AUTOSAR XML (schema 4-2-2)
standard types defined: boolean, float32, float64, sint16, sint32, sint64, sint8, uint16, uint32, uint64, uint8
package /AUTOSAR_PlatformTypes/CompuMethods
  compu method CompuMethod_boolean: 0=false (CompuMethod_boolean_false), 1=true (CompuMethod_boolean_true)
package /AUTOSAR_PlatformTypes/DataConstraints
  range DataConstr_boolean: raw 0..1
  range DataConstr_sint16: phys -32768..32767, raw -32768..32767
  range DataConstr_sint32: phys -2147483648..2147483647, raw -2147483648..2147483647
  range DataConstr_sint64: phys -9223372036854775808..9223372036854775807, raw -9223372036854775808..9223372036854775807
  range DataConstr_sint8: phys -128..127, raw -128..127
  range DataConstr_uint16: phys 0..65535, raw 0..65535
  range DataConstr_uint32: phys 0..4294967295, raw 0..4294967295
  range DataConstr_uint64: phys 0..18446744073709551615, raw 0..18446744073709551615
  range DataConstr_uint8: phys 0..255, raw 0..255
package /BaseType
  77 x base type:
    BT_AB_Abschaltanf_SIH_BF: category=FIXED_LENGTH, base-type-size=1, base-type-encoding=NONE, byte-order=little-endian
    BT_AB_Anforderung_USM: category=FIXED_LENGTH, base-type-size=1, base-type-encoding=NONE, byte-order=little-endian
    BT_AB_Anforderung_eCall: category=FIXED_LENGTH, base-type-size=1, base-type-encoding=NONE, byte-order=little-endian
    BT_AB_Anprall_FGS: category=FIXED_LENGTH, base-type-size=1, base-type-encoding=NONE, byte-order=little-endian
    BT_AB_Anprall_Front_Beifahrer: category=FIXED_LENGTH, base-type-size=1, base-type-encoding=NONE, byte-order=little-endian
    BT_AB_Anprall_Front_Fahrer: category=FIXED_LENGTH, base-type-size=1, base-type-encoding=NONE, byte-order=little-endian
    BT_AB_Anprall_Heck_Beifahrer: category=FIXED_LENGTH, base-type-size=1, base-type-encoding=NONE, byte-order=little-endian
    BT_AB_Anprall_Heck_Fahrer: category=FIXED_LENGTH, base-type-size=1, base-type-encoding=NONE, byte-order=little-endian
    BT_AB_Anprall_Rollover: category=FIXED_LENGTH, base-type-size=1, base-type-encoding=NONE, byte-order=little-endian
    BT_AB_Anprall_Seite_Beifahrer: category=FIXED_LENGTH, base-type-size=1, base-type-encoding=NONE, byte-order=little-endian
    BT_AB_Anprall_Seite_Fahrer: category=FIXED_LENGTH, base-type-size=1, base-type-encoding=NONE, byte-order=little-endian
    BT_AB_Anzeige_Fussg: category=FIXED_LENGTH, base-type-size=2, base-type-encoding=NONE, byte-order=little-endian
    BT_AB_Belegung_VB: category=FIXED_LENGTH, base-type-size=2, base-type-encoding=NONE, byte-order=little-endian
    BT_AB_Belegung_VF: category=FIXED_LENGTH, base-type-size=2, base-type-encoding=NONE, byte-order=little-endian
    BT_AB_Crash_Int: category=FIXED_LENGTH, base-type-size=3, base-type-encoding=NONE, byte-order=little-endian
    BT_AB_Crashschwere: category=FIXED_LENGTH, base-type-size=3, base-type-encoding=NONE, byte-order=little-endian
    BT_AB_Deaktiviert: category=FIXED_LENGTH, base-type-size=1, base-type-encoding=NONE, byte-order=little-endian
    BT_AB_Deaktivierung_HV: category=FIXED_LENGTH, base-type-size=3, base-type-encoding=NONE, byte-order=little-endian
    BT_AB_Diagnose: category=FIXED_LENGTH, base-type-size=1, base-type-encoding=NONE, byte-order=little-endian
    BT_AB_EDR_Trigger: category=FIXED_LENGTH, base-type-size=2, base-type-encoding=NONE, byte-order=little-endian
    BT_AB_Erh_Auf_VB: category=FIXED_LENGTH, base-type-size=2, base-type-encoding=NONE, byte-order=little-endian
    BT_AB_Front_Crash: category=FIXED_LENGTH, base-type-size=1, base-type-encoding=NONE, byte-order=little-endian
    BT_AB_Gurtschloss_BF: category=FIXED_LENGTH, base-type-size=2, base-type-encoding=NONE, byte-order=little-endian
    BT_AB_Gurtschloss_FA: category=FIXED_LENGTH, base-type-size=2, base-type-encoding=NONE, byte-order=little-endian
    BT_AB_Gurtschloss_FA_ext: category=FIXED_LENGTH, base-type-size=3, base-type-encoding=NONE, byte-order=little-endian
    BT_AB_Gurtschloss_FA_ext_aktiv: category=FIXED_LENGTH, base-type-size=1, base-type-encoding=NONE, byte-order=little-endian
    BT_AB_Gurtschloss_Reihe2_BF: category=FIXED_LENGTH, base-type-size=2, base-type-encoding=NONE, byte-order=little-endian
    BT_AB_Gurtschloss_Reihe2_FA: category=FIXED_LENGTH, base-type-size=2, base-type-encoding=NONE, byte-order=little-endian
    BT_AB_Gurtschloss_Reihe2_MI: category=FIXED_LENGTH, base-type-size=2, base-type-encoding=NONE, byte-order=little-endian
    BT_AB_Gurtschloss_Reihe3_BF: category=FIXED_LENGTH, base-type-size=2, base-type-encoding=NONE, byte-order=little-endian
    BT_AB_Gurtschloss_Reihe3_FA: category=FIXED_LENGTH, base-type-size=2, base-type-encoding=NONE, byte-order=little-endian
    BT_AB_Gurtschloss_Reihe3_MI: category=FIXED_LENGTH, base-type-size=2, base-type-encoding=NONE, byte-order=little-endian
    BT_AB_Gurtwarn_VB: category=FIXED_LENGTH, base-type-size=1, base-type-encoding=NONE, byte-order=little-endian
    BT_AB_Gurtwarn_VF: category=FIXED_LENGTH, base-type-size=1, base-type-encoding=NONE, byte-order=little-endian
    BT_AB_Heck_Crash: category=FIXED_LENGTH, base-type-size=1, base-type-encoding=NONE, byte-order=little-endian
    BT_AB_Lampe: category=FIXED_LENGTH, base-type-size=1, base-type-encoding=NONE, byte-order=little-endian
    BT_AB_MKB_Anforderung: category=FIXED_LENGTH, base-type-size=1, base-type-encoding=NONE, byte-order=little-endian
    BT_AB_MKB_gueltig: category=FIXED_LENGTH, base-type-size=1, base-type-encoding=NONE, byte-order=little-endian
    BT_AB_PAO_Leuchte_Anf: category=FIXED_LENGTH, base-type-size=1, base-type-encoding=NONE, byte-order=little-endian
    BT_AB_RGS_Anst: category=FIXED_LENGTH, base-type-size=4, base-type-encoding=NONE, byte-order=little-endian
    BT_AB_Rollover_Crash: category=FIXED_LENGTH, base-type-size=1, base-type-encoding=NONE, byte-order=little-endian
    BT_AB_SB_Crash: category=FIXED_LENGTH, base-type-size=1, base-type-encoding=NONE, byte-order=little-endian
    BT_AB_SF_Crash: category=FIXED_LENGTH, base-type-size=1, base-type-encoding=NONE, byte-order=little-endian
    BT_AB_Sitzpos_Sens_BF: category=FIXED_LENGTH, base-type-size=2, base-type-encoding=NONE, byte-order=little-endian
    BT_AB_Sitzpos_Sens_FA: category=FIXED_LENGTH, base-type-size=2, base-type-encoding=NONE, byte-order=little-endian
    BT_AB_Stellgliedtest: category=FIXED_LENGTH, base-type-size=1, base-type-encoding=NONE, byte-order=little-endian
    BT_AB_Systemfehler: category=FIXED_LENGTH, base-type-size=1, base-type-encoding=NONE, byte-order=little-endian
    BT_AB_Texte_AKS: category=FIXED_LENGTH, base-type-size=2, base-type-encoding=NONE, byte-order=little-endian
    BT_AB_VB_deaktiviert: category=FIXED_LENGTH, base-type-size=1, base-type-encoding=NONE, byte-order=little-endian
    BT_AB_Versorgungsspannung: category=FIXED_LENGTH, base-type-size=1, base-type-encoding=NONE, byte-order=little-endian
    BT_AB_Wickelklappung_Reihe2_BF: category=FIXED_LENGTH, base-type-size=2, base-type-encoding=NONE, byte-order=little-endian
    BT_AB_Wickelklappung_Reihe2_FA: category=FIXED_LENGTH, base-type-size=2, base-type-encoding=NONE, byte-order=little-endian
    BT_AB_Wickelklappung_Reihe2_MI: category=FIXED_LENGTH, base-type-size=2, base-type-encoding=NONE, byte-order=little-endian
    BT_AB_eCS_Aktuatortest_BF: category=FIXED_LENGTH, base-type-size=2, base-type-encoding=NONE, byte-order=little-endian
    BT_AB_eCS_Aktuatortest_FA: category=FIXED_LENGTH, base-type-size=2, base-type-encoding=NONE, byte-order=little-endian
    BT_AB_eCS_Aktuatortest_Reihe2_BF: category=FIXED_LENGTH, base-type-size=2, base-type-encoding=NONE, byte-order=little-endian
    BT_AB_eCS_Aktuatortest_Reihe2_FA: category=FIXED_LENGTH, base-type-size=2, base-type-encoding=NONE, byte-order=little-endian
    BT_AB_eCS_Aktuatortest_Reihe3_BF: category=FIXED_LENGTH, base-type-size=2, base-type-encoding=NONE, byte-order=little-endian
    BT_AB_eCS_Aktuatortest_Reihe3_FA: category=FIXED_LENGTH, base-type-size=2, base-type-encoding=NONE, byte-order=little-endian
    BT_AB_eCS_Error: category=FIXED_LENGTH, base-type-size=1, base-type-encoding=NONE, byte-order=little-endian
    BT_ASM_Masterzeit_02: category=FIXED_LENGTH, base-type-size=8, base-type-encoding=NONE, byte-order=little-endian
    BT_Airbag_01_BZ: category=FIXED_LENGTH, base-type-size=4, base-type-encoding=NONE, byte-order=little-endian
    BT_Airbag_01_CRC: category=FIXED_LENGTH, base-type-size=8, base-type-encoding=NONE, byte-order=little-endian
    BT_Airbag_02_BZ: category=FIXED_LENGTH, base-type-size=4, base-type-encoding=NONE, byte-order=little-endian
    BT_Airbag_02_CRC: category=FIXED_LENGTH, base-type-size=8, base-type-encoding=NONE, byte-order=little-endian
    BT_LoGeWa_Event_Kombiwarnung: category=FIXED_LENGTH, base-type-size=4, base-type-encoding=NONE, byte-order=little-endian
    BT_SC_PAO_OFF_Anf: category=FIXED_LENGTH, base-type-size=2, base-type-encoding=NONE, byte-order=little-endian
    BT_SC_PAO_ON_Anf: category=FIXED_LENGTH, base-type-size=2, base-type-encoding=NONE, byte-order=little-endian
    BT_SC_PAO_Schriftzug_Anf: category=FIXED_LENGTH, base-type-size=2, base-type-encoding=NONE, byte-order=little-endian
    BT_SignalVoid: category=VOID, base-type-encoding=VOID
    BT_eCS_Gurtschloss_Status_Reihe2_BF: category=FIXED_LENGTH, base-type-size=2, base-type-encoding=NONE, byte-order=little-endian
    BT_eCS_Gurtschloss_Status_Reihe2_FA: category=FIXED_LENGTH, base-type-size=2, base-type-encoding=NONE, byte-order=little-endian
    BT_eCS_HW_defekt: category=FIXED_LENGTH, base-type-size=1, base-type-encoding=NONE, byte-order=little-endian
    BT_eCS_SBS_Belegung_Reihe2_BF: category=FIXED_LENGTH, base-type-size=2, base-type-encoding=NONE, byte-order=little-endian
    BT_eCS_SBS_Belegung_Reihe2_FA: category=FIXED_LENGTH, base-type-size=2, base-type-encoding=NONE, byte-order=little-endian
    BT_eCS_Status: category=FIXED_LENGTH, base-type-size=2, base-type-encoding=NONE, byte-order=little-endian
    BT_eCS_Stoerung: category=FIXED_LENGTH, base-type-size=1, base-type-encoding=NONE, byte-order=little-endian
package /BasetypePackage
  base type uint1: category=FIXED_LENGTH, base-type-size=32, base-type-encoding=NONE, byte-order=opaque
  base type uint512: category=FIXED_LENGTH, base-type-size=32, base-type-encoding=NONE, byte-order=opaque
package /Cluster
  can cluster Airbag_SUBCANFD: baudrate=500000, protocol-name=CAN, protocol-version=2.0, bus-off-recovery={bor-counter-l-1-to-l-2=1, bor-time-l-1=0.05, bor-time-l-2=0.2}, can-fd-baudrate=500000  # SubCAN FD Airbag
    can physical channel CHNL: comm-connectors=[CanCommunicationConnector_0, CanCommunicationConnector_1]
      frame Airbag_01: id 0x40, from Airbag, frame-length=8, can-addressing-mode=STANDARD, can-frame-rx-behavior=CAN-FD, can-frame-tx-behavior=CAN-FD
        pdu ipdu_Airbag_01: length=8, transmission-mode-true-timing=cyclic-timing={time-offset=0.0, time-period=0.04}
          signal is_AB_Anzeige_Fussg1: start 34, 2 bit, little-endian, system signal sys_AB_Anzeige_Fussg, init-value=0, base-type=BasetypePackage/uint8, transfer-property=TRIGGERED, to eCS  # Anzeige für ausgelöste Fussgängerschutz-Aktuatorik  # Airbag_SUBCANFD_V14.09.00.01E Generated by BUSNETNG Produktiv 9.24.6
          signal is_AB_Belegung_VF1: start 47, 2 bit, little-endian, system signal sys_AB_Belegung_VF, init-value=0, base-type=BasetypePackage/uint8, transfer-property=TRIGGERED, to eCS  # Belegungserkennung vorne Fahrer.  # Airbag_SUBCANFD_V14.09.00.01E Generated by BUSNETNG Produktiv 9.24.6
          signal is_AB_Crash_Int1: start 21, 3 bit, little-endian, system signal sys_AB_Crash_Int, init-value=0, base-type=BasetypePackage/uint8, transfer-property=TRIGGERED, to eCS  # Crash_Intensität_1 = fahrzeugabhängige Reaktionen im Crash Crash_Intensität_2 = fahrzeugabhängige Reaktionen im Crash Crash_Intensität_3 = fahrzeugabhängige Reaktionen im Crash Die jeweiligen fahrzeugabhängigen Reaktionen im Crash sind in einem separ  # Airbag_SUBCANFD_V14.09.00.01E Generated by BUSNETNG Produktiv 9.24.6
          signal is_AB_Deaktiviert1: start 25, 1 bit, little-endian, system signal sys_AB_Deaktiviert, init-value=0, base-type=uint1, transfer-property=TRIGGERED, to eCS  # Airbag oder Gurtstraffer wurden per Anpassung deaktiviert: Aktualisierung erst nach Selbsttest  # Airbag_SUBCANFD_V14.09.00.01E Generated by BUSNETNG Produktiv 9.24.6
          signal is_AB_Deaktivierung_HV1: start 42, 3 bit, little-endian, system signal sys_AB_Deaktivierung_HV, init-value=0, base-type=BasetypePackage/uint8, transfer-property=TRIGGERED, to eCS  # Deaktivierung des HV-Systems und der HV-Teilnehmer im Crash (u.a. Hybrid- und Elektrofahrzeuge)  # Airbag_SUBCANFD_V14.09.00.01E Generated by BUSNETNG Produktiv 9.24.6
          signal is_AB_Diagnose1: start 28, 1 bit, little-endian, system signal sys_AB_Diagnose, init-value=0, base-type=uint1, transfer-property=TRIGGERED, to eCS  # Airbag in Diagnose  # Airbag_SUBCANFD_V14.09.00.01E Generated by BUSNETNG Produktiv 9.24.6
          signal is_AB_EDR_Trigger1: start 45, 2 bit, little-endian, system signal sys_AB_EDR_Trigger, init-value=0, base-type=BasetypePackage/uint8, transfer-property=TRIGGERED, to eCS  # Triggerbedingung zur dezentralen Aufzeichnung unfallrelevanter Daten im Event Data Recorder  # Airbag_SUBCANFD_V14.09.00.01E Generated by BUSNETNG Produktiv 9.24.6
          signal is_AB_Erh_Auf_VB1: start 30, 2 bit, little-endian, system signal sys_AB_Erh_Auf_VB, init-value=0, base-type=BasetypePackage/uint8, transfer-property=TRIGGERED, to eCS  # Der Fahrer soll bei einem Statuswechsel des Beifahrerairbags (ausgelöst durch die Beifahrerinsassenerkennung oder den Schlüsselschloßschalter) aufmerksam gemacht werden durch eine Anzeige im Kombi. Nur Audi: gültig für: AB2 (4-Türer AU352), B7, C6, D3  # Airbag_SUBCANFD_V14.09.00.01E Generated by BUSNETNG Produktiv 9.24.6
          signal is_AB_Front_Crash1: start 16, 1 bit, little-endian, system signal sys_AB_Front_Crash, init-value=0, base-type=uint1, transfer-property=TRIGGERED, to eCS  # Bit wird bei Überschreitung der Gurtstraffer-, US- und RdW-Schwelle gesetzt  # Airbag_SUBCANFD_V14.09.00.01E Generated by BUSNETNG Produktiv 9.24.6
          signal is_AB_Gurtschloss_FA_ext1: start 49, 3 bit, little-endian, system signal sys_AB_Gurtschloss_FA_ext, init-value=6, base-type=BasetypePackage/uint8, transfer-property=TRIGGERED, to eCS  # Das Ergebnis der Basisfunktion 'Plausibilisierung Gurtschloss' des Verlassenskonzepts wird im Signal dargestellt.  # Airbag_SUBCANFD_V14.09.00.01E Generated by BUSNETNG Produktiv 9.24.6
          signal is_AB_Gurtschloss_FA_ext_aktiv1: start 52, 1 bit, little-endian, system signal sys_AB_Gurtschloss_FA_ext_aktiv, init-value=0, base-type=uint1, transfer-property=TRIGGERED, to eCS  # Über dieses Signal wird signalisiert ob die Erweiterte Gurtdiagnose (Ergebnis wird im Signal AB_Gurtschloss_FA_ext dargestellt) aktiviert oder deaktiviert ist.  # Airbag_SUBCANFD_V14.09.00.01E Generated by BUSNETNG Produktiv 9.24.6
          signal is_AB_Gurtwarn_VB1: start 33, 1 bit, little-endian, system signal sys_AB_Gurtwarn_VB, init-value=0, base-type=uint1, transfer-property=TRIGGERED, to eCS  # Beifahrer hat Gurt nicht gesteckt, Anzeige im Kombi  # Airbag_SUBCANFD_V14.09.00.01E Generated by BUSNETNG Produktiv 9.24.6
          signal is_AB_Gurtwarn_VF1: start 32, 1 bit, little-endian, system signal sys_AB_Gurtwarn_VF, init-value=0, base-type=uint1, transfer-property=TRIGGERED, to eCS  # Fahrer hat Gurt nicht gesteckt, Anzeige im Kombi  # Airbag_SUBCANFD_V14.09.00.01E Generated by BUSNETNG Produktiv 9.24.6
          signal is_AB_Heck_Crash1: start 17, 1 bit, little-endian, system signal sys_AB_Heck_Crash, init-value=0, base-type=uint1, transfer-property=TRIGGERED, to eCS  # Wird für alle neu anlaufenden Projekte umgesetzt: AB8.4, Audi8/VW8  # Airbag_SUBCANFD_V14.09.00.01E Generated by BUSNETNG Produktiv 9.24.6
          signal is_AB_Lampe1: start 24, 1 bit, little-endian, system signal sys_AB_Lampe, init-value=1, base-type=uint1, transfer-property=TRIGGERED, to eCS  # Sicherheitswarnlampe im Kombi wird vom Airbag-SG angesteuert; Zustand der Lampe wird auf dem CAN-Bus ausgegeben (auch Blinkinformation).  # Airbag_SUBCANFD_V14.09.00.01E Generated by BUSNETNG Produktiv 9.24.6
          signal is_AB_MKB_Anforderung1: start 40, 1 bit, little-endian, system signal sys_AB_MKB_Anforderung, init-value=0, base-type=uint1, transfer-property=TRIGGERED, to eCS  # Anforderung Multi-Kollisions-Bremsung  # Airbag_SUBCANFD_V14.09.00.01E Generated by BUSNETNG Produktiv 9.24.6
          signal is_AB_MKB_gueltig1: start 39, 1 bit, little-endian, system signal sys_AB_MKB_gueltig, init-value=0, base-type=uint1, transfer-property=TRIGGERED, to eCS  # Multi-Kollisions-Bremsung im Airbag freigeschaltet  # Airbag_SUBCANFD_V14.09.00.01E Generated by BUSNETNG Produktiv 9.24.6
          signal is_AB_PAO_Leuchte_Anf1: start 38, 1 bit, little-endian, system signal sys_AB_PAO_Leuchte_Anf, init-value=1, base-type=uint1, transfer-property=TRIGGERED, to eCS  # Anforderung an die Passenger-Airbag-Off Leuchte in der Dachkonsole (ein / aus), Einsatz nur bei PAG  # Airbag_SUBCANFD_V14.09.00.01E Generated by BUSNETNG Produktiv 9.24.6
          signal is_AB_RGS_Anst1: start 12, 4 bit, little-endian, system signal sys_AB_RGS_Anst, init-value=8, base-type=BasetypePackage/uint8, transfer-property=TRIGGERED, to eCS  # PreCrash-Ansteuerung reversibler Gurtstraffer (Aktivierung und Kraftniveau) 10xx = deaktiviert  # Airbag_SUBCANFD_V14.09.00.01E Generated by BUSNETNG Produktiv 9.24.6
          signal is_AB_Rollover_Crash1: start 20, 1 bit, little-endian, system signal sys_AB_Rollover_Crash, init-value=0, base-type=uint1, transfer-property=TRIGGERED, to eCS  # Wird im B6/B7 Cabrio und New Beetle Cabrio bedient.  # Airbag_SUBCANFD_V14.09.00.01E Generated by BUSNETNG Produktiv 9.24.6
          signal is_AB_SB_Crash1: start 19, 1 bit, little-endian, system signal sys_AB_SB_Crash, init-value=0, base-type=uint1, transfer-property=TRIGGERED, to eCS  # Z.Zt. nur in Verbindung mit Crash-Intensität >= 100b (Kraftstoffpumpenabschaltung) verwendet.  # Airbag_SUBCANFD_V14.09.00.01E Generated by BUSNETNG Produktiv 9.24.6
          signal is_AB_SF_Crash1: start 18, 1 bit, little-endian, system signal sys_AB_SF_Crash, init-value=0, base-type=uint1, transfer-property=TRIGGERED, to eCS  # Z.Zt. nur in Verbindung mit Crash-Intensität >= 100b (Kraftstoffpumpenabschaltung) verwendet.  # Airbag_SUBCANFD_V14.09.00.01E Generated by BUSNETNG Produktiv 9.24.6
          signal is_AB_Stellgliedtest1: start 29, 1 bit, little-endian, system signal sys_AB_Stellgliedtest, init-value=0, base-type=uint1, transfer-property=TRIGGERED, to eCS  # Information, ob Airbag im Stellgliedtest ist, um eine Notrufauflösung beim Stellgliedtest zu verhindern  # Airbag_SUBCANFD_V14.09.00.01E Generated by BUSNETNG Produktiv 9.24.6
          signal is_AB_Systemfehler1: start 27, 1 bit, little-endian, system signal sys_AB_Systemfehler, init-value=0, base-type=uint1, transfer-property=TRIGGERED, to eCS  # Systemfehler Ggf. wird Warnlampe dauernd eingeschaltet.  # Airbag_SUBCANFD_V14.09.00.01E Generated by BUSNETNG Produktiv 9.24.6
          signal is_AB_Texte_AKS1: start 36, 2 bit, little-endian, system signal sys_AB_Texte_AKS, init-value=0, base-type=BasetypePackage/uint8, transfer-property=TRIGGERED, to eCS  # Textanzeige für pyrotechnische Auslösung der aktiven Kopfstütze (AKS)  # Airbag_SUBCANFD_V14.09.00.01E Generated by BUSNETNG Produktiv 9.24.6
          signal is_AB_VB_deaktiviert1: start 26, 1 bit, little-endian, system signal sys_AB_VB_deaktiviert, init-value=1, base-type=uint1, transfer-property=TRIGGERED, to eCS  # Als Option vorgehalten, Beifahrerairbag wurden per Schlüsselschalter oder Insassenerkennung deaktiviert  # Airbag_SUBCANFD_V14.09.00.01E Generated by BUSNETNG Produktiv 9.24.6
          signal is_AB_Versorgungsspannung1: start 41, 1 bit, little-endian, system signal sys_AB_Versorgungsspannung, init-value=0, base-type=uint1, transfer-property=TRIGGERED, to eCS  # Übertragung der Plausibilitätsinformation Kl.15-Last vs. Kl.15-CAN. Bedienung im Fall Kl.15-Last 'EIN' und Kl.15-CAN 'AUS' mit Ausgabe Warnung/Akustik im Kombi.  # Airbag_SUBCANFD_V14.09.00.01E Generated by BUSNETNG Produktiv 9.24.6
          signal is_AB_eCS_Error1: start 53, 1 bit, little-endian, system signal sys_AB_eCS_Error, init-value=0, base-type=uint1, transfer-property=TRIGGERED, to eCS  # Signal zur Anforderung der Anzeige von Störungen im System der elektrischen Gurtverriegelung  # Airbag_SUBCANFD_V14.09.00.01E Generated by BUSNETNG Produktiv 9.24.6
          signal is_ASM_Masterzeit_021: start 56, 8 bit, little-endian, system signal sys_ASM_Masterzeit_02, init-value=255, base-type=BasetypePackage/uint8, transfer-property=TRIGGERED, to eCS  # Masterzeit für alle ASM Sender  # Airbag_SUBCANFD_V14.09.00.01E Generated by BUSNETNG Produktiv 9.24.6
          signal is_Airbag_01_BZ1: start 8, 4 bit, little-endian, system signal sys_Airbag_01_BZ, init-value=0, base-type=BasetypePackage/uint8, transfer-property=TRIGGERED, to eCS  # Airbag_SUBCANFD_V14.09.00.01E Generated by BUSNETNG Produktiv 9.24.6
          signal is_Airbag_01_CRC1: start 0, 8 bit, little-endian, system signal sys_Airbag_01_CRC, init-value=0, base-type=BasetypePackage/uint8, transfer-property=TRIGGERED, to eCS  # Für MLB: 'Berechnung siehe Lastenheft 'Kommunikationsabsicherung für FlexRay und CAN'' Ab MQB und MLBevo: 'Berechnung siehe Lastenheft 'End-to-End Kommunikationsabsicherung'' Endwerte siehe Begleitdokument 'S-PDU Kennungsfolgen'  # Airbag_SUBCANFD_V14.09.00.01E Generated by BUSNETNG Produktiv 9.24.6
      frame Airbag_02: id 0x520, from Airbag, frame-length=8, can-addressing-mode=STANDARD, can-frame-rx-behavior=CAN-FD, can-frame-tx-behavior=CAN-FD
        pdu ipdu_Airbag_02: length=8, transmission-mode-true-timing=cyclic-timing={time-offset=0.0, time-period=0.2}
          signal is_AB_Abschaltanf_SIH_BF1: start 28, 1 bit, little-endian, system signal sys_AB_Abschaltanf_SIH_BF, init-value=0, base-type=uint1, transfer-property=TRIGGERED, to eCS  # Die Insassenerkennung auf der Beifahrerseite fordert bei Übertemperatur eine Abschaltung der Sitzheizung an. Die Übertemperatur kann bei niederohmigen Nebenschlüssen der Sitzheizungsmatte als Folge von zu hohem resultierenden Strom auftreten.  # Airbag_SUBCANFD_V14.09.00.01E Generated by BUSNETNG Produktiv 9.24.6
          signal is_AB_Anforderung_USM1: start 39, 1 bit, little-endian, system signal sys_AB_Anforderung_USM, init-value=0, base-type=uint1, transfer-property=TRIGGERED, to eCS  # Trigger für Gateway (OBDC) und MIB/MMI, dass ein USM-Ereignis erkannt wurde.  # Airbag_SUBCANFD_V14.09.00.01E Generated by BUSNETNG Produktiv 9.24.6
          signal is_AB_Anforderung_eCall1: start 16, 1 bit, little-endian, system signal sys_AB_Anforderung_eCall, init-value=0, base-type=uint1, transfer-property=TRIGGERED, to eCS  # Trigger für Car2X Steuergerät das ein eCall Ereignis erkannt wurde.  # Airbag_SUBCANFD_V14.09.00.01E Generated by BUSNETNG Produktiv 9.24.6
          signal is_AB_Anprall_FGS1: start 19, 1 bit, little-endian, system signal sys_AB_Anprall_FGS, init-value=0, base-type=uint1, transfer-property=TRIGGERED, to eCS  # Uebermittlung der Lage einer Kollision, Fussgaengerschutz-Aktorik  # Airbag_SUBCANFD_V14.09.00.01E Generated by BUSNETNG Produktiv 9.24.6
          signal is_AB_Anprall_Front_Beifahrer1: start 20, 1 bit, little-endian, system signal sys_AB_Anprall_Front_Beifahrer, init-value=0, base-type=uint1, transfer-property=TRIGGERED, to eCS  # Uebermittlung der Lage einer Kollision, Anprallzone Front Beifahrerseite  # Airbag_SUBCANFD_V14.09.00.01E Generated by BUSNETNG Produktiv 9.24.6
          signal is_AB_Anprall_Front_Fahrer1: start 21, 1 bit, little-endian, system signal sys_AB_Anprall_Front_Fahrer, init-value=0, base-type=uint1, transfer-property=TRIGGERED, to eCS  # Uebermittlung der Lage einer Kollision, Anprallzone Front Fahrerseite  # Airbag_SUBCANFD_V14.09.00.01E Generated by BUSNETNG Produktiv 9.24.6
          signal is_AB_Anprall_Heck_Beifahrer1: start 22, 1 bit, little-endian, system signal sys_AB_Anprall_Heck_Beifahrer, init-value=0, base-type=uint1, transfer-property=TRIGGERED, to eCS  # Uebermittlung der Lage einer Kollision, Anprallzone Beifahrerseite hinten  # Airbag_SUBCANFD_V14.09.00.01E Generated by BUSNETNG Produktiv 9.24.6
          signal is_AB_Anprall_Heck_Fahrer1: start 23, 1 bit, little-endian, system signal sys_AB_Anprall_Heck_Fahrer, init-value=0, base-type=uint1, transfer-property=TRIGGERED, to eCS  # Uebermittlung der Lage einer Kollision, Anprallzone Fahrerseite hinten  # Airbag_SUBCANFD_V14.09.00.01E Generated by BUSNETNG Produktiv 9.24.6
          signal is_AB_Anprall_Rollover1: start 18, 1 bit, little-endian, system signal sys_AB_Anprall_Rollover, init-value=0, base-type=uint1, transfer-property=TRIGGERED, to eCS  # Uebermittlung der Lage einer Kollision, Rollover erkannt  # Airbag_SUBCANFD_V14.09.00.01E Generated by BUSNETNG Produktiv 9.24.6
          signal is_AB_Anprall_Seite_Beifahrer1: start 17, 1 bit, little-endian, system signal sys_AB_Anprall_Seite_Beifahrer, init-value=0, base-type=uint1, transfer-property=TRIGGERED, to eCS  # Uebermittlung der Lage einer Kollision, Anprallzone Beifahrerseite Seite  # Airbag_SUBCANFD_V14.09.00.01E Generated by BUSNETNG Produktiv 9.24.6
          signal is_AB_Anprall_Seite_Fahrer1: start 29, 1 bit, little-endian, system signal sys_AB_Anprall_Seite_Fahrer, init-value=0, base-type=uint1, transfer-property=TRIGGERED, to eCS  # Uebermittlung der Lage einer Kollision, Anprallzone Fahrerseite Seite  # Airbag_SUBCANFD_V14.09.00.01E Generated by BUSNETNG Produktiv 9.24.6
          signal is_AB_Belegung_VB1: start 26, 2 bit, little-endian, system signal sys_AB_Belegung_VB, init-value=0, base-type=BasetypePackage/uint8, transfer-property=TRIGGERED, to eCS  # Belegungserkennung vorne Beifahrer. Wird in US-Steuergeräten über Bladder-Matte bedient, optional bei RdW, falls SBE_EuroNCAP entschieden wird.  # Airbag_SUBCANFD_V14.09.00.01E Generated by BUSNETNG Produktiv 9.24.6
          signal is_AB_Crashschwere1: start 36, 3 bit, little-endian, system signal sys_AB_Crashschwere, init-value=0, base-type=BasetypePackage/uint8, transfer-property=TRIGGERED, to eCS  # Übermittlung der Crashschwere an das Gateway (OBDC)  # Airbag_SUBCANFD_V14.09.00.01E Generated by BUSNETNG Produktiv 9.24.6
          signal is_AB_Gurtschloss_BF1: start 42, 2 bit, little-endian, system signal sys_AB_Gurtschloss_BF, init-value=1, base-type=BasetypePackage/uint8, transfer-property=TRIGGERED, to eCS  # Gurtschlossstatus Beifahrerseite  # Airbag_SUBCANFD_V14.09.00.01E Generated by BUSNETNG Produktiv 9.24.6
          signal is_AB_Gurtschloss_FA1: start 40, 2 bit, little-endian, system signal sys_AB_Gurtschloss_FA, init-value=1, base-type=BasetypePackage/uint8, transfer-property=TRIGGERED, to eCS  # Gurtschlosstatatus Fahrerseite  # Airbag_SUBCANFD_V14.09.00.01E Generated by BUSNETNG Produktiv 9.24.6
          signal is_AB_Gurtschloss_Reihe2_BF1: start 48, 2 bit, little-endian, system signal sys_AB_Gurtschloss_Reihe2_BF, init-value=1, base-type=BasetypePackage/uint8, transfer-property=TRIGGERED, to eCS  # Gurtschlossstatus 2. Reihe Beifahrerseite, Mehrausstattung  # Airbag_SUBCANFD_V14.09.00.01E Generated by BUSNETNG Produktiv 9.24.6
          signal is_AB_Gurtschloss_Reihe2_FA1: start 44, 2 bit, little-endian, system signal sys_AB_Gurtschloss_Reihe2_FA, init-value=1, base-type=BasetypePackage/uint8, transfer-property=TRIGGERED, to eCS  # Gurtschlossstatus 2. Reihe Fahrerseite, Mehrausstattung  # Airbag_SUBCANFD_V14.09.00.01E Generated by BUSNETNG Produktiv 9.24.6
          signal is_AB_Gurtschloss_Reihe2_MI1: start 46, 2 bit, little-endian, system signal sys_AB_Gurtschloss_Reihe2_MI, init-value=1, base-type=BasetypePackage/uint8, transfer-property=TRIGGERED, to eCS  # Gurtschlossstatus 2. Reihe Mitte, Mehrausstattung  # Airbag_SUBCANFD_V14.09.00.01E Generated by BUSNETNG Produktiv 9.24.6
          signal is_AB_Gurtschloss_Reihe3_BF1: start 54, 2 bit, little-endian, system signal sys_AB_Gurtschloss_Reihe3_BF, init-value=1, base-type=BasetypePackage/uint8, transfer-property=TRIGGERED, to eCS  # Gurtschlossstatus 3. Reihe Beifahrerseite, Mehrausstattung  # Airbag_SUBCANFD_V14.09.00.01E Generated by BUSNETNG Produktiv 9.24.6
          signal is_AB_Gurtschloss_Reihe3_FA1: start 50, 2 bit, little-endian, system signal sys_AB_Gurtschloss_Reihe3_FA, init-value=1, base-type=BasetypePackage/uint8, transfer-property=TRIGGERED, to eCS  # Gurtschlossstatus 3. Reihe Fahrerseite, Mehrausstattung  # Airbag_SUBCANFD_V14.09.00.01E Generated by BUSNETNG Produktiv 9.24.6
          signal is_AB_Gurtschloss_Reihe3_MI1: start 52, 2 bit, little-endian, system signal sys_AB_Gurtschloss_Reihe3_MI, init-value=1, base-type=BasetypePackage/uint8, transfer-property=TRIGGERED, to eCS  # Gurtschlossstatus 3. Reihe Mitte, Mehrausstattung  # Airbag_SUBCANFD_V14.09.00.01E Generated by BUSNETNG Produktiv 9.24.6
          signal is_AB_Sitzpos_Sens_BF1: start 58, 2 bit, little-endian, system signal sys_AB_Sitzpos_Sens_BF, init-value=0, base-type=BasetypePackage/uint8, transfer-property=TRIGGERED, to eCS  # Ausgabe Sitzposition Beifahrer  # Airbag_SUBCANFD_V14.09.00.01E Generated by BUSNETNG Produktiv 9.24.6
          signal is_AB_Sitzpos_Sens_FA1: start 56, 2 bit, little-endian, system signal sys_AB_Sitzpos_Sens_FA, init-value=0, base-type=BasetypePackage/uint8, transfer-property=TRIGGERED, to eCS  # Ausgabe Sitzposition Fahrer  # Airbag_SUBCANFD_V14.09.00.01E Generated by BUSNETNG Produktiv 9.24.6
          signal is_AB_Wickelklappung_Reihe2_BF1: start 60, 2 bit, little-endian, system signal sys_AB_Wickelklappung_Reihe2_BF, init-value=1, base-type=BasetypePackage/uint8, transfer-property=TRIGGERED, to eCS  # Status Wickelklappung 2. Reihe Beifahrerseite, Mehrausstattung  # Airbag_SUBCANFD_V14.09.00.01E Generated by BUSNETNG Produktiv 9.24.6
          signal is_AB_Wickelklappung_Reihe2_FA1: start 62, 2 bit, little-endian, system signal sys_AB_Wickelklappung_Reihe2_FA, init-value=1, base-type=BasetypePackage/uint8, transfer-property=TRIGGERED, to eCS  # Status Wickelklappung 2. Reihe Fahrerseite, Mehrausstattung  # Airbag_SUBCANFD_V14.09.00.01E Generated by BUSNETNG Produktiv 9.24.6
          signal is_AB_Wickelklappung_Reihe2_MI1: start 24, 2 bit, little-endian, system signal sys_AB_Wickelklappung_Reihe2_MI, init-value=1, base-type=BasetypePackage/uint8, transfer-property=TRIGGERED, to eCS  # Status Wickelklappung 2. Reihe Mitte, Mehrausstattung  # Airbag_SUBCANFD_V14.09.00.01E Generated by BUSNETNG Produktiv 9.24.6
          signal is_Airbag_02_BZ1: start 8, 4 bit, little-endian, system signal sys_Airbag_02_BZ, init-value=0, base-type=BasetypePackage/uint8, transfer-property=TRIGGERED, to eCS  # Airbag_SUBCANFD_V14.09.00.01E Generated by BUSNETNG Produktiv 9.24.6
          signal is_Airbag_02_CRC1: start 0, 8 bit, little-endian, system signal sys_Airbag_02_CRC, init-value=0, base-type=BasetypePackage/uint8, transfer-property=TRIGGERED, to eCS  # Für MLB: 'Berechnung siehe Lastenheft 'Kommunikationsabsicherung für FlexRay und CAN'' Ab MQB und MLBevo: 'Berechnung siehe Lastenheft 'End-to-End Kommunikationsabsicherung'' Endwerte siehe Begleitdokument 'S-PDU Kennungsfolgen'  # Airbag_SUBCANFD_V14.09.00.01E Generated by BUSNETNG Produktiv 9.24.6
          signal is_LoGeWa_Event_Kombiwarnung1: start 12, 4 bit, little-endian, system signal sys_LoGeWa_Event_Kombiwarnung, init-value=0, base-type=BasetypePackage/uint8, transfer-property=TRIGGERED, to eCS  # Event für Kombiwarnung  # Airbag_SUBCANFD_V14.09.00.01E Generated by BUSNETNG Produktiv 9.24.6
          signal is_SC_PAO_OFF_Anf1: start 34, 2 bit, little-endian, system signal sys_SC_PAO_OFF_Anf, init-value=0, base-type=BasetypePackage/uint8, transfer-property=TRIGGERED, to eCS  # Sollwert für LED 'OFF' in Anzeige Passenger Airbag On/Off  # Airbag_SUBCANFD_V14.09.00.01E Generated by BUSNETNG Produktiv 9.24.6
          signal is_SC_PAO_ON_Anf1: start 32, 2 bit, little-endian, system signal sys_SC_PAO_ON_Anf, init-value=0, base-type=BasetypePackage/uint8, transfer-property=TRIGGERED, to eCS  # Sollwert für LED 'ON' in Anzeige Passenger Airbag On/Off  # Airbag_SUBCANFD_V14.09.00.01E Generated by BUSNETNG Produktiv 9.24.6
          signal is_SC_PAO_Schriftzug_Anf1: start 30, 2 bit, little-endian, system signal sys_SC_PAO_Schriftzug_Anf, init-value=0, base-type=BasetypePackage/uint8, transfer-property=TRIGGERED, to eCS  # Sollwert für LED 'PASSENGER AIRBAG' in Anzeige Passenger Airbag On/Off  # Airbag_SUBCANFD_V14.09.00.01E Generated by BUSNETNG Produktiv 9.24.6
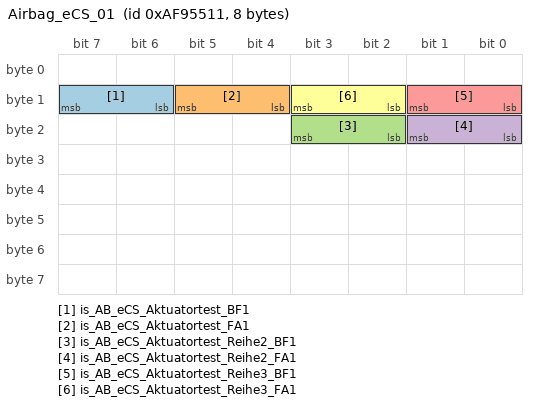
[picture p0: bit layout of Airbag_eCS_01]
      frame Airbag_eCS_01: id 0xAF95511, from Airbag, frame-length=8, can-addressing-mode=EXTENDED, can-frame-rx-behavior=CAN-FD, can-frame-tx-behavior=CAN-FD
        pdu ipdu_Airbag_eCS_01: length=8, transmission-mode-true-timing=cyclic-timing={time-offset=0.0, time-period=0.05}
          signal is_AB_eCS_Aktuatortest_BF1: start 14, 2 bit, little-endian, system signal sys_AB_eCS_Aktuatortest_BF, init-value=0, base-type=BasetypePackage/uint8, transfer-property=TRIGGERED, to eCS  # Signal zum Stellgliedtest Beifahrersitz  # Airbag_SUBCANFD_V14.09.00.01E Generated by BUSNETNG Produktiv 9.24.6
          signal is_AB_eCS_Aktuatortest_FA1: start 12, 2 bit, little-endian, system signal sys_AB_eCS_Aktuatortest_FA, init-value=0, base-type=BasetypePackage/uint8, transfer-property=TRIGGERED, to eCS  # Signal zum Stellgliedtest Fahrersitz  # Airbag_SUBCANFD_V14.09.00.01E Generated by BUSNETNG Produktiv 9.24.6
          signal is_AB_eCS_Aktuatortest_Reihe2_BF1: start 18, 2 bit, little-endian, system signal sys_AB_eCS_Aktuatortest_Reihe2_BF, init-value=0, base-type=BasetypePackage/uint8, transfer-property=TRIGGERED, to eCS  # Signal zum Stellgliedtest Sitz hinten in 2. SR Beifahrerseite  # Airbag_SUBCANFD_V14.09.00.01E Generated by BUSNETNG Produktiv 9.24.6
          signal is_AB_eCS_Aktuatortest_Reihe2_FA1: start 16, 2 bit, little-endian, system signal sys_AB_eCS_Aktuatortest_Reihe2_FA, init-value=0, base-type=BasetypePackage/uint8, transfer-property=TRIGGERED, to eCS  # Signal zum Stellgliedtest Sitz hinten in 2. SR Fahrerseite  # Airbag_SUBCANFD_V14.09.00.01E Generated by BUSNETNG Produktiv 9.24.6
          signal is_AB_eCS_Aktuatortest_Reihe3_BF1: start 8, 2 bit, little-endian, system signal sys_AB_eCS_Aktuatortest_Reihe3_BF, init-value=0, base-type=BasetypePackage/uint8, transfer-property=TRIGGERED, to eCS  # Signal zum Stellgliedtest Sitz hinten in 3. SR Beifahrerseite  # Airbag_SUBCANFD_V14.09.00.01E Generated by BUSNETNG Produktiv 9.24.6
          signal is_AB_eCS_Aktuatortest_Reihe3_FA1: start 10, 2 bit, little-endian, system signal sys_AB_eCS_Aktuatortest_Reihe3_FA, init-value=0, base-type=BasetypePackage/uint8, transfer-property=TRIGGERED, to eCS  # Signal zum Stellgliedtest Sitz hinten in 3. SR Fahrerseite  # Airbag_SUBCANFD_V14.09.00.01E Generated by BUSNETNG Produktiv 9.24.6
      frame DIA_eCS_Req_XIX_Airbag_SUBCANFD: id 0x17FC4206, from Airbag, frame-length=8, can-addressing-mode=EXTENDED, can-frame-rx-behavior=CAN-FD, can-frame-tx-behavior=CAN-FD
        n pdu DIA_eCS_Req_XIX_Airbag_SUBCANFD: length=8
      frame DIA_eCS_Req_FD_XIX_Airbag_SUBCANFD: id 0x1C404206, from Airbag, frame-length=64, can-addressing-mode=EXTENDED, can-frame-rx-behavior=CAN-FD, can-frame-tx-behavior=CAN-FD
        n pdu DIA_eCS_Req_FD_XIX_Airbag_SUBCANFD: length=64
      frame DIA_eCS_Resp_XIX_Airbag_SUBCANFD: id 0x17FE4206, from eCS, to Airbag, frame-length=8, can-addressing-mode=EXTENDED, can-frame-rx-behavior=CAN-FD, can-frame-tx-behavior=CAN-FD
        n pdu DIA_eCS_Resp_XIX_Airbag_SUBCANFD: length=8
      frame DIA_eCS_Resp_FD_XIX_Airbag_SUBCANFD: id 0x1C424206, from eCS, to Airbag, frame-length=64, can-addressing-mode=EXTENDED, can-frame-rx-behavior=CAN-FD, can-frame-tx-behavior=CAN-FD
        n pdu DIA_eCS_Resp_FD_XIX_Airbag_SUBCANFD: length=64
      frame Diag_eCS_Req_FD_XIX_Airbag_SUBCANFD: id 0x1C405206, from Airbag, frame-length=64, can-addressing-mode=EXTENDED, can-frame-rx-behavior=CAN-FD, can-frame-tx-behavior=CAN-FD
        n pdu Diag_eCS_Req_FD_XIX_Airbag_SUBCANFD: length=64
      frame Diag_eCS_Resp_FD_XIX_Airbag_SUBCANFD: id 0x1C425206, from eCS, to Airbag, frame-length=64, can-addressing-mode=EXTENDED, can-frame-rx-behavior=CAN-FD, can-frame-tx-behavior=CAN-FD
        n pdu Diag_eCS_Resp_FD_XIX_Airbag_SUBCANFD: length=64
      frame OBDC_SSN_eCS_Req_FD_XIX_Airbag_SUBCANFD: id 0x1C407206, from Airbag, frame-length=64, can-addressing-mode=EXTENDED, can-frame-rx-behavior=CAN-FD, can-frame-tx-behavior=CAN-FD
        n pdu OBDC_SSN_eCS_Req_FD_XIX_Airbag_SUBCANFD: length=64
      frame OBDC_SSN_eCS_Resp_FD_XIX_Airbag_SUBCANFD: id 0x1C427206, from eCS, to Airbag, frame-length=64, can-addressing-mode=EXTENDED, can-frame-rx-behavior=CAN-FD, can-frame-tx-behavior=CAN-FD
        n pdu OBDC_SSN_eCS_Resp_FD_XIX_Airbag_SUBCANFD: length=64
      frame eCS_01: id 0xAF95510, from eCS, to Airbag, frame-length=8, can-addressing-mode=EXTENDED, can-frame-rx-behavior=CAN-FD, can-frame-tx-behavior=CAN-FD
        pdu ipdu_eCS_01: length=8, transmission-mode-true-timing=cyclic-timing={time-offset=0.0, time-period=0.05}
          signal is_eCS_Error_Reihe1_BFS_1: start 39, 3 bit, little-endian, system signal sys_eCS_Error_Reihe1_BFS_1, init-value=0, base-type=SwBaseTypes/uint8, to Airbag
          signal is_eCS_Error_Reihe1_BFS_2: start 45, 3 bit, little-endian, system signal sys_eCS_Error_Reihe1_BFS_2, init-value=0, base-type=SwBaseTypes/uint8, to Airbag
          signal is_eCS_Error_Reihe1_FS_1: start 36, 3 bit, little-endian, system signal sys_eCS_Error_Reihe1_FS_1, init-value=0, base-type=SwBaseTypes/uint8, to Airbag
          signal is_eCS_Error_Reihe1_FS_2: start 42, 3 bit, little-endian, system signal sys_eCS_Error_Reihe1_FS_2, init-value=0, base-type=SwBaseTypes/uint8, to Airbag
          signal is_eCS_Error_Reihe2_BFS: start 51, 3 bit, little-endian, system signal sys_eCS_Error_Reihe2_BFS, init-value=0, base-type=SwBaseTypes/uint8, to Airbag
          signal is_eCS_Error_Reihe2_FS: start 48, 3 bit, little-endian, system signal sys_eCS_Error_Reihe2_FS, init-value=0, base-type=SwBaseTypes/uint8, to Airbag
          signal is_eCS_SBS_LastState_Reihe2_BFS: start 56, 2 bit, little-endian, system signal sys_eCS_SBS_LastState_Reihe2_BFS, init-value=0, base-type=SwBaseTypes/uint8, to Airbag
          signal is_eCS_SBS_LastState_Reihe2_FS: start 54, 2 bit, little-endian, system signal sys_eCS_SBS_LastState_Reihe2_FS, init-value=0, base-type=SwBaseTypes/uint8, to Airbag
          signal is_eCS_Status_Verr_Reihe1_BFS_1: start 26, 2 bit, little-endian, system signal sys_eCS_Status_Verr_Reihe1_BFS_1, init-value=0, base-type=SwBaseTypes/uint8, to Airbag
          signal is_eCS_Status_Verr_Reihe1_BFS_2: start 30, 2 bit, little-endian, system signal sys_eCS_Status_Verr_Reihe1_BFS_2, init-value=0, base-type=SwBaseTypes/uint8, to Airbag
          signal is_eCS_Status_Verr_Reihe1_FS_1: start 24, 2 bit, little-endian, system signal sys_eCS_Status_Verr_Reihe1_FS_1, init-value=0, base-type=SwBaseTypes/uint8, to Airbag
          signal is_eCS_Status_Verr_Reihe1_FS_2: start 28, 2 bit, little-endian, system signal sys_eCS_Status_Verr_Reihe1_FS_2, init-value=0, base-type=SwBaseTypes/uint8, to Airbag
          signal is_eCS_Status_Verr_Reihe2_BFS: start 34, 2 bit, little-endian, system signal sys_eCS_Status_Verr_Reihe2_BFS, init-value=0, base-type=SwBaseTypes/uint8, to Airbag
          signal is_eCS_Status_Verr_Reihe2_FS: start 32, 2 bit, little-endian, system signal sys_eCS_Status_Verr_Reihe2_FS, init-value=0, base-type=SwBaseTypes/uint8, to Airbag
          signal is_eCS_Gurtschloss_Status_Reihe2_BF1: start 18, 2 bit, little-endian, system signal sys_eCS_Gurtschloss_Status_Reihe2_BF, init-value=1, base-type=BasetypePackage/uint8, transfer-property=TRIGGERED, to Airbag  # Das eCS SG sendet den Status des Gutschlosses 2.SR Beifahrer an das Airbag SG  # Airbag_SUBCANFD_V14.09.00.01E Generated by BUSNETNG Produktiv 9.24.6
          signal is_eCS_Gurtschloss_Status_Reihe2_FA1: start 16, 2 bit, little-endian, system signal sys_eCS_Gurtschloss_Status_Reihe2_FA, init-value=1, base-type=BasetypePackage/uint8, transfer-property=TRIGGERED, to Airbag  # Das eCS SG sendet den Status des Gutschlosses 2.SR Fahrer an das Airbag SG  # Airbag_SUBCANFD_V14.09.00.01E Generated by BUSNETNG Produktiv 9.24.6
          signal is_eCS_HW_defekt1: start 15, 1 bit, little-endian, system signal sys_eCS_HW_defekt, init-value=0, base-type=BasetypePackage/uint8, transfer-property=TRIGGERED, to Airbag  # das eCS signalisiert ein HW_defekt  # Airbag_SUBCANFD_V14.09.00.01E Generated by BUSNETNG Produktiv 9.24.6
          signal is_eCS_SBS_Belegung_Reihe2_BF1: start 22, 2 bit, little-endian, system signal sys_eCS_SBS_Belegung_Reihe2_BF, init-value=2, base-type=BasetypePackage/uint8, transfer-property=TRIGGERED, to Airbag  # Das eCS SG sendet den Status der Sitzbelegung 2.SR Beifahrer an dem Airbag SG  # Airbag_SUBCANFD_V14.09.00.01E Generated by BUSNETNG Produktiv 9.24.6
          signal is_eCS_SBS_Belegung_Reihe2_FA1: start 20, 2 bit, little-endian, system signal sys_eCS_SBS_Belegung_Reihe2_FA, init-value=2, base-type=BasetypePackage/uint8, transfer-property=TRIGGERED, to Airbag  # Das eCS SG sendet den Status der Sitzbelegung 2.SR Fahrer an dem Airbag SG  # Airbag_SUBCANFD_V14.09.00.01E Generated by BUSNETNG Produktiv 9.24.6
          signal is_eCS_Status1: start 12, 2 bit, little-endian, system signal sys_eCS_Status, init-value=0, base-type=BasetypePackage/uint8, transfer-property=TRIGGERED, to Airbag  # Das eCS SG sendet den Status des Gurtband verriegelt oder entriegelt (Magnethub am Gurt gesperrt oder entsperrt)  # Airbag_SUBCANFD_V14.09.00.01E Generated by BUSNETNG Produktiv 9.24.6
          signal is_eCS_Stoerung1: start 14, 1 bit, little-endian, system signal sys_eCS_Stoerung, init-value=0, base-type=BasetypePackage/uint8, transfer-property=TRIGGERED, to Airbag  # Das eCS signalisiert einen sporadischen Fehler oder einen Kommunikations-Timeout  # Airbag_SUBCANFD_V14.09.00.01E Generated by BUSNETNG Produktiv 9.24.6
      frame Can_Frame_MF_Logger: id 0x7C5, from eCS, to Airbag, can-addressing-mode=EXTENDED, can-fd-frame-support=false, j-1939-requestable=false, rx-mask=0, tx-mask=0
      frame Can_Frame_CanDataOut_0: id 0x100, from eCS, to Airbag, can-addressing-mode=STANDARD, can-fd-frame-support=false, j-1939-requestable=false, rx-mask=0, tx-mask=0
      frame Can_Frame_MF: id 0x7C4, from eCS, to Airbag, can-addressing-mode=EXTENDED, can-fd-frame-support=false, j-1939-requestable=false, rx-mask=0, tx-mask=0
      pdu triggering PT_Airbag_SUBCANFD_XIX_TPCHType_CANFD_Diag_XIX_0x1C405206_XIX_0x1C425206_XIX_Physical: pdu=DCM_Airbag_SUBCANFD_XIX_TPCHType_CANFD_Diag_XIX_0x1C405206_XIX_0x1C425206_XIX_Physical
      pdu triggering PT_Airbag_SUBCANFD_XIX_TPCHType_CANFD_Diag_XIX_0x1C425206_XIX_0x1C405206_XIX_Physical: pdu=DCM_Airbag_SUBCANFD_XIX_TPCHType_CANFD_Diag_XIX_0x1C425206_XIX_0x1C405206_XIX_Physical
      pdu triggering PT_Airbag_SUBCANFD_XIX_TPCHType_CANFD_Flash_DIA_XIX_0x1C404206_XIX_0x1C424206_XIX_Physical: pdu=DCM_Airbag_SUBCANFD_XIX_TPCHType_CANFD_Flash_DIA_XIX_0x1C404206_XIX_0x1C424206_XIX_Physical
      pdu triggering PT_Airbag_SUBCANFD_XIX_TPCHType_CANFD_Flash_DIA_XIX_0x1C424206_XIX_0x1C404206_XIX_Physical: pdu=DCM_Airbag_SUBCANFD_XIX_TPCHType_CANFD_Flash_DIA_XIX_0x1C424206_XIX_0x1C404206_XIX_Physical
      pdu triggering PT_Airbag_SUBCANFD_XIX_TPCHType_CANFD_OBDC_SSN_Diagnose_XIX_0x1C407206_XIX_0x1C427206_XIX_Physical: pdu=DCM_Airbag_SUBCANFD_XIX_TPCHType_CANFD_OBDC_SSN_Diagnose_XIX_0x1C407206_XIX_0x1C427206_XIX_Physical
      pdu triggering PT_Airbag_SUBCANFD_XIX_TPCHType_CANFD_OBDC_SSN_Diagnose_XIX_0x1C427206_XIX_0x1C407206_XIX_Physical: pdu=DCM_Airbag_SUBCANFD_XIX_TPCHType_CANFD_OBDC_SSN_Diagnose_XIX_0x1C427206_XIX_0x1C407206_XIX_Physical
      pdu triggering PT_Airbag_SUBCANFD_XIX_TPCHType_CANHS_Flash_DIA_XIX_0x17FC4206_XIX_0x17FE4206_XIX_Physical: pdu=DCM_Airbag_SUBCANFD_XIX_TPCHType_CANHS_Flash_DIA_XIX_0x17FC4206_XIX_0x17FE4206_XIX_Physical
      pdu triggering PT_Airbag_SUBCANFD_XIX_TPCHType_CANHS_Flash_DIA_XIX_0x17FE4206_XIX_0x17FC4206_XIX_Physical: pdu=DCM_Airbag_SUBCANFD_XIX_TPCHType_CANHS_Flash_DIA_XIX_0x17FE4206_XIX_0x17FC4206_XIX_Physical
      pdu triggering PduTriggering0: pdu=IPdu_MFData, from eCS, to Airbag
      pdu triggering PduTriggering1: pdu=IPdu_MFData_Logger, from eCS, to Airbag
      pdu triggering PduTriggering65: pdu=IPdu_Dev_Out_0, from eCS, to Airbag
package /CommunicationClusterPackage
  can tp config CanTPConfig_MQBw_Baseline_eCS: communication-cluster=MQBw_Baseline_Airbag_SUBCANFD_KMatrix_V14_09_00_01E_20230404_MH_Alv_CANBus
    8 x can tp address, all with tp-address-extension-value=0:
      TA_0x17FC4206: tp-address=402407942
      TA_0x17FE4206: tp-address=402539014
      TA_0x1C404206: tp-address=473973254
      TA_0x1C405206: tp-address=473977350
      TA_0x1C407206: tp-address=473985542
      TA_0x1C424206: tp-address=474104326
      TA_0x1C425206: tp-address=474108422
      TA_0x1C427206: tp-address=474116614
    4 x can tp channel, all with channel-mode=FULL-DUPLEX-MODE:
      TPC_Airbag_SUBCANFD_XIX_TPCHType_CANFD_Diag_XIX_0x1C405206_XIX_0x1C425206_XIX_Physical: channel-id=1449258196
      TPC_Airbag_SUBCANFD_XIX_TPCHType_CANFD_Flash_DIA_XIX_0x1C404206_XIX_0x1C424206_XIX_Physical: channel-id=2060928652
      TPC_Airbag_SUBCANFD_XIX_TPCHType_CANFD_OBDC_SSN_Diagnose_XIX_0x1C407206_XIX_0x1C427206_XIX_Physical: channel-id=1803922309
      TPC_Airbag_SUBCANFD_XIX_TPCHType_CANHS_Flash_DIA_XIX_0x17FC4206_XIX_0x17FE4206_XIX_Physical: channel-id=1639721959
    tp-connections:
      addressing-format=STANDARD, can-tp-channel=TPC_Airbag_SUBCANFD_XIX_TPCHType_CANFD_Diag_XIX_0x1C405206_XIX_0x1C425206_XIX_Physical, cancellation=false, data-pdu=Diag_eCS_Req_FD_XIX_Airbag_SUBCANFD, flow-control-pdu=Diag_eCS_Resp_FD_XIX_Airbag_SUBCANFD, max-block-size=0, multicast=TA_0x1C405206, padding-activation=false, receiver=TPN_eCS_XIX_Airbag_SUBCANFD_XIX_0x1C425206, timeout-br=0.0, timeout-bs=0.0, timeout-cr=0.0, timeout-cs=0.0, tp-sdu=DCM_Airbag_SUBCANFD_XIX_TPCHType_CANFD_Diag_XIX_0x1C405206_XIX_0x1C425206_XIX_Physical, transmit-cancellation=false, transmitter=TPN_Airbag_01_XIX_Airbag_SUBCANFD_XIX_0x1C405206
      addressing-format=STANDARD, can-tp-channel=TPC_Airbag_SUBCANFD_XIX_TPCHType_CANFD_OBDC_SSN_Diagnose_XIX_0x1C407206_XIX_0x1C427206_XIX_Physical, cancellation=false, data-pdu=OBDC_SSN_eCS_Req_FD_XIX_Airbag_SUBCANFD, flow-control-pdu=OBDC_SSN_eCS_Resp_FD_XIX_Airbag_SUBCANFD, max-block-size=0, padding-activation=false, receiver=TPN_eCS_XIX_Airbag_SUBCANFD_XIX_0x1C427206, timeout-br=0.0, timeout-bs=0.0, timeout-cr=0.0, timeout-cs=0.0, tp-sdu=DCM_Airbag_SUBCANFD_XIX_TPCHType_CANFD_OBDC_SSN_Diagnose_XIX_0x1C407206_XIX_0x1C427206_XIX_Physical, transmit-cancellation=false, transmitter=TPN_Airbag_01_XIX_Airbag_SUBCANFD_XIX_0x1C407206
      addressing-format=STANDARD, can-tp-channel=TPC_Airbag_SUBCANFD_XIX_TPCHType_CANFD_Flash_DIA_XIX_0x1C404206_XIX_0x1C424206_XIX_Physical, cancellation=false, data-pdu=DIA_eCS_Req_FD_XIX_Airbag_SUBCANFD, flow-control-pdu=DIA_eCS_Resp_FD_XIX_Airbag_SUBCANFD, max-block-size=0, padding-activation=false, receiver=TPN_eCS_XIX_Airbag_SUBCANFD_XIX_0x1C424206, timeout-br=0.1, timeout-bs=1.0, timeout-cr=1.0, timeout-cs=0.2, tp-sdu=DCM_Airbag_SUBCANFD_XIX_TPCHType_CANFD_Flash_DIA_XIX_0x1C404206_XIX_0x1C424206_XIX_Physical, transmit-cancellation=false, transmitter=TPN_Airbag_01_XIX_Airbag_SUBCANFD_XIX_0x1C404206
      addressing-format=STANDARD, can-tp-channel=TPC_Airbag_SUBCANFD_XIX_TPCHType_CANHS_Flash_DIA_XIX_0x17FC4206_XIX_0x17FE4206_XIX_Physical, cancellation=false, data-pdu=DIA_eCS_Req_XIX_Airbag_SUBCANFD, flow-control-pdu=DIA_eCS_Resp_XIX_Airbag_SUBCANFD, max-block-size=0, padding-activation=false, receiver=TPN_eCS_XIX_Airbag_SUBCANFD_XIX_0x17FE4206, timeout-br=0.0, timeout-bs=0.0, timeout-cr=0.0, timeout-cs=0.0, tp-sdu=DCM_Airbag_SUBCANFD_XIX_TPCHType_CANHS_Flash_DIA_XIX_0x17FC4206_XIX_0x17FE4206_XIX_Physical, transmit-cancellation=false, transmitter=TPN_Airbag_01_XIX_Airbag_SUBCANFD_XIX_0x17FC4206
    tp-ecus:
      cycle-time-main-function=0.005, ecu-instance=eCS
      cycle-time-main-function=0.005, ecu-instance=Airbag
    8 x can tp node, all with max-fc-wait=15, st-min=0.005, timeout-ar=1.0, timeout-as=1.0:
      TPN_Airbag_01_XIX_Airbag_SUBCANFD_XIX_0x17FC4206: connector=cc_MQBw_Baseline_Airbag_SUBCANFD_KMatrix_V14_09_00_01E_202304041_MH_Alv, tp-address=TA_0x17FC4206
      TPN_Airbag_01_XIX_Airbag_SUBCANFD_XIX_0x1C404206: connector=cc_MQBw_Baseline_Airbag_SUBCANFD_KMatrix_V14_09_00_01E_202304041_MH_Alv, tp-address=TA_0x1C404206
      TPN_Airbag_01_XIX_Airbag_SUBCANFD_XIX_0x1C405206: connector=cc_MQBw_Baseline_Airbag_SUBCANFD_KMatrix_V14_09_00_01E_202304041_MH_Alv, tp-address=TA_0x1C405206
      TPN_Airbag_01_XIX_Airbag_SUBCANFD_XIX_0x1C407206: connector=cc_MQBw_Baseline_Airbag_SUBCANFD_KMatrix_V14_09_00_01E_202304041_MH_Alv, tp-address=TA_0x1C407206
      TPN_eCS_XIX_Airbag_SUBCANFD_XIX_0x17FE4206: connector=cc_MQBw_Baseline_Airbag_SUBCANFD_KMatrix_V14_09_00_01E_20230404_MH_Alv, tp-address=TA_0x17FE4206
      TPN_eCS_XIX_Airbag_SUBCANFD_XIX_0x1C424206: connector=cc_MQBw_Baseline_Airbag_SUBCANFD_KMatrix_V14_09_00_01E_20230404_MH_Alv, tp-address=TA_0x1C424206
      TPN_eCS_XIX_Airbag_SUBCANFD_XIX_0x1C425206: connector=cc_MQBw_Baseline_Airbag_SUBCANFD_KMatrix_V14_09_00_01E_20230404_MH_Alv, tp-address=TA_0x1C425206
      TPN_eCS_XIX_Airbag_SUBCANFD_XIX_0x1C427206: connector=cc_MQBw_Baseline_Airbag_SUBCANFD_KMatrix_V14_09_00_01E_20230404_MH_Alv, tp-address=TA_0x1C427206
  can cluster MQBw_Baseline_Airbag_SUBCANFD_KMatrix_V14_09_00_01E_20230404_MH_Alv_CANBus: baudrate=500000, protocol-name=CAN
    can physical channel MQBw_Baseline_Airbag_SUBCANFD_KMatrix_V14_09_00_01E_20230404_MH_Alv  # Airbag_SUBCANFD_V14.09.00.01E Generated by BUSNETNG Produktiv 9.24.6
      comm-connectors:
        cc_MQBw_Baseline_Airbag_SUBCANFD_KMatrix_V14_09_00_01E_202304041_MH_Alv
        cc_MQBw_Baseline_Airbag_SUBCANFD_KMatrix_V14_09_00_01E_20230404_MH_Alv
      frame Airbag_01: id 0x40, from Airbag, to eCS, frame-length=8, can-addressing-mode=STANDARD
        carries pdu ipdu_Airbag_01: packing-byte-order=little-endian, start-position=0
      frame Airbag_02: id 0x520, from Airbag, to eCS, frame-length=8, can-addressing-mode=STANDARD
        carries pdu ipdu_Airbag_02: packing-byte-order=little-endian, start-position=0
      frame Airbag_eCS_01: id 0xAF95511, from Airbag, to eCS, frame-length=8, can-addressing-mode=EXTENDED
        carries pdu ipdu_Airbag_eCS_01: packing-byte-order=little-endian, start-position=0
      frame Can_Frame_CanDataOut_0: id 0x100, from eCS, to Airbag, can-addressing-mode=STANDARD, can-fd-frame-support=false, j-1939-requestable=false, rx-mask=0, tx-mask=0
      frame Can_Frame_MF_Logger: id 0x7C5, from eCS, to Airbag, can-addressing-mode=STANDARD, can-fd-frame-support=false, can-frame-rx-behavior=ANY, can-frame-tx-behavior=CAN-20, j-1939-requestable=false, rx-mask=0, tx-mask=0
      frame Can_Frame_MF: id 0x7C4, from eCS, to Airbag, can-addressing-mode=STANDARD, can-fd-frame-support=false, can-frame-rx-behavior=ANY, can-frame-tx-behavior=CAN-20, j-1939-requestable=false, rx-mask=0, tx-mask=0
      frame DIA_eCS_Req_XIX_Airbag_SUBCANFD: id 0x17FC4206, from Airbag, to eCS, frame-length=8, can-addressing-mode=STANDARD, can-fd-frame-support=false, can-frame-rx-behavior=ANY, can-frame-tx-behavior=CAN-20, j-1939-requestable=false, rx-mask=0, tx-mask=0
        carries pdu DIA_eCS_Req_XIX_Airbag_SUBCANFD: packing-byte-order=little-endian, start-position=0
      frame DIA_eCS_Req_FD_XIX_Airbag_SUBCANFD: id 0x1C404206, from Airbag, to eCS, frame-length=64, can-addressing-mode=STANDARD, can-fd-frame-support=false, can-frame-rx-behavior=ANY, can-frame-tx-behavior=CAN-20, j-1939-requestable=false, rx-mask=0, tx-mask=0
        carries pdu DIA_eCS_Req_FD_XIX_Airbag_SUBCANFD: packing-byte-order=little-endian, start-position=0
      frame DIA_eCS_Resp_XIX_Airbag_SUBCANFD: id 0x17FE4206, from Airbag, to eCS, frame-length=8, can-addressing-mode=STANDARD, can-fd-frame-support=false, can-frame-rx-behavior=ANY, can-frame-tx-behavior=CAN-20, j-1939-requestable=false, rx-mask=0, tx-mask=0
        carries pdu DIA_eCS_Resp_XIX_Airbag_SUBCANFD: packing-byte-order=little-endian, start-position=0
      frame DIA_eCS_Resp_FD_XIX_Airbag_SUBCANFD: id 0x1C424206, from Airbag, to eCS, frame-length=64, can-addressing-mode=STANDARD, can-fd-frame-support=false, can-frame-rx-behavior=ANY, can-frame-tx-behavior=CAN-20, j-1939-requestable=false, rx-mask=0, tx-mask=0
        carries pdu DIA_eCS_Resp_FD_XIX_Airbag_SUBCANFD: packing-byte-order=little-endian, start-position=0
      frame Diag_eCS_Resp_FD_XIX_Airbag_SUBCANFD: id 0x1C425206, from Airbag, to eCS, frame-length=64, can-addressing-mode=STANDARD, can-fd-frame-support=false, can-frame-rx-behavior=ANY, can-frame-tx-behavior=CAN-20, j-1939-requestable=false, rx-mask=0, tx-mask=0
        carries pdu Diag_eCS_Resp_FD_XIX_Airbag_SUBCANFD: packing-byte-order=little-endian, start-position=0
      frame Diag_eCS_Req_FD_XIX_Airbag_SUBCANFD: id 0x1C405206, from Airbag, to eCS, frame-length=64, can-addressing-mode=STANDARD, can-fd-frame-support=false, can-frame-rx-behavior=ANY, can-frame-tx-behavior=CAN-20, j-1939-requestable=false, rx-mask=0, tx-mask=0
        carries pdu Diag_eCS_Req_FD_XIX_Airbag_SUBCANFD: packing-byte-order=little-endian, start-position=0
      frame Can_Frame_GliwaIn: id 0x12C, from Airbag, to eCS, can-addressing-mode=STANDARD, can-fd-frame-support=false, can-frame-rx-behavior=ANY, can-frame-tx-behavior=CAN-20, j-1939-requestable=false, rx-mask=0, tx-mask=0
      frame Can_Frame_GliwaOut: id 0xC8, from eCS, to Airbag, can-addressing-mode=STANDARD, can-fd-frame-support=false, can-frame-rx-behavior=ANY, can-frame-tx-behavior=CAN-20, j-1939-requestable=false, rx-mask=0, tx-mask=0
      frame OBDC_SSN_eCS_Req_FD_XIX_Airbag_SUBCANFD: id 0x1C407206, from Airbag, to eCS, frame-length=64, can-addressing-mode=STANDARD, can-fd-frame-support=false, can-frame-rx-behavior=ANY, can-frame-tx-behavior=CAN-20, j-1939-requestable=false, rx-mask=0, tx-mask=0
        carries pdu OBDC_SSN_eCS_Req_FD_XIX_Airbag_SUBCANFD: packing-byte-order=little-endian, start-position=0
      frame OBDC_SSN_eCS_Resp_FD_XIX_Airbag_SUBCANFD: id 0x1C427206, from Airbag, to eCS, frame-length=64, can-addressing-mode=STANDARD, can-fd-frame-support=false, can-frame-rx-behavior=ANY, can-frame-tx-behavior=CAN-20, j-1939-requestable=false, rx-mask=0, tx-mask=0
        carries pdu OBDC_SSN_eCS_Resp_FD_XIX_Airbag_SUBCANFD: packing-byte-order=little-endian, start-position=0
      frame eCS_01: id 0xAF95510, from eCS, to Airbag, frame-length=8, can-addressing-mode=EXTENDED
        carries pdu ipdu_eCS_01: packing-byte-order=little-endian, start-position=0
      pdu triggering DCM_Airbag_SUBCANFD_XIX_Baseline_Airbag_SUBCANFD_KMatrix_V14_09_00_01E_20230404_MH_Alv: pdu=DCM_Airbag_SUBCANFD_XIX_TPCHType_CANFD_Flash_DIA_XIX_0x1C404206_XIX_0x1C424206_XIX_Physical, from Airbag, to eCS
      pdu triggering DCM_Airbag_SUBCANFD_XIX_MQBw_Baseline_Airbag_SUBCANFD_KMatrix_V14_09_00_01E_20230404_MH_Alv: pdu=DCM_Airbag_SUBCANFD_XIX_TPCHType_CANFD_OBDC_SSN_Diagnose_XIX_0x1C407206_XIX_0x1C427206_XIX_Physical, from Airbag, to eCS
      pdu triggering DCM_Airbag_SUBCANFD_XIX_TPCHType_Baseline_Airbag_SUBCANFD_KMatrix_V14_09_00_01E_20230404_MH_Alv: pdu=DCM_Airbag_SUBCANFD_XIX_TPCHType_CANFD_Flash_DIA_XIX_0x1C404206_XIX_0x1C424206_XIX_Physical, from Airbag, to eCS
      pdu triggering DCM_Airbag_SUBCANFD_XIX_TPCHType_MQBw_Baseline_Airbag_SUBCANFD_KMatrix_V14_09_00_01E_20230404_MH_Alv: pdu=DCM_Airbag_SUBCANFD_XIX_TPCHType_CANFD_Diag_XIX_0x1C405206_XIX_0x1C425206_XIX_Physical, from Airbag, to eCS
      pdu triggering DCM_Airbag_SUBCANFD_XIX_TPCHType_TriggeringOn_MQBw_Baseline_Airbag_SUBCANFD_KMatrix_V14_09_00_01E_20230404_MH_Alv: pdu=DCM_Airbag_SUBCANFD_XIX_TPCHType_CANHS_Flash_DIA_XIX_0x17FC4206_XIX_0x17FE4206_XIX_Physical, from Airbag, to eCS
      pdu triggering PduTriggering196: pdu=IPdu_MFData, from eCS, to Airbag
      pdu triggering PduTriggering271: pdu=IPdu_Dev_Out_0, from eCS, to Airbag
      pdu triggering PduTriggering304: pdu=ipdu_DIA_eCS_Resp, from Airbag, to eCS
      pdu triggering PduTriggering394: pdu=IPdu_Gliwa_Out, from eCS, to Airbag
      pdu triggering PduTriggering397: pdu=IPdu_Gliwa_In, from Airbag, to eCS
      pdu triggering PduTriggering4: pdu=IPdu_MFData_Logger, from eCS, to Airbag
      pdu triggering PduTriggering66: pdu=IPdu_Dev_Out_0, from eCS, to Airbag
      pdu triggering TriggeringOn_MQBw_Baseline_Airbag_SUBCANFD_KMatrix_V14_09_00_01E_20230404_MH_Alv: pdu=ipdu_Diag_eCS_Resp_FD, from eCS, to Airbag
      pdu triggering TriggeringOn_MQBw_Baseline_Airbag_SUBCANFD_KMatrix_V14_09_00_01E_20230404_MH_Alv: pdu=ipdu_OBDC_SSN_eCS_Req_FD, from Airbag, to eCS
      pdu triggering ipt_DIA_eCS_Req_FD: pdu=ipdu_DIA_eCS_Req_FD, from Airbag, to eCS
      pdu triggering ipt_DIA_eCS_Resp_FD: pdu=ipdu_DIA_eCS_Resp_FD, from eCS, to Airbag
      pdu triggering ipt_Diag_eCS_Req_FD: pdu=ipdu_Diag_eCS_Req_FD, from Airbag, to eCS
      pdu triggering ipt_Diag_eCS_Resp_FD: pdu=ipdu_Diag_eCS_Resp_FD, from eCS, to Airbag
      pdu triggering ipt_OBDC_SSN_eCS_Req_FD: pdu=ipdu_OBDC_SSN_eCS_Req_FD, from Airbag, to eCS
      pdu triggering ipt_OBDC_SSN_eCS_Resp_FD: pdu=ipdu_OBDC_SSN_eCS_Resp_FD, from eCS, to Airbag
package /ComponentTypes
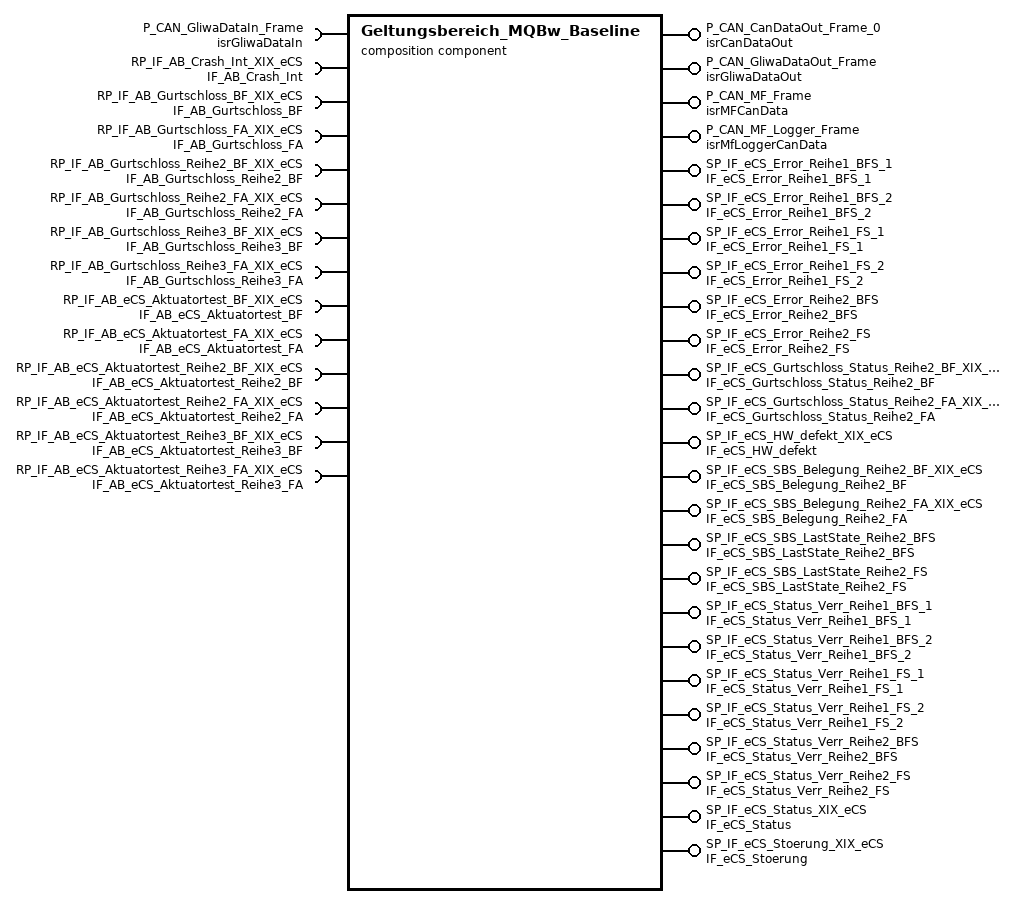
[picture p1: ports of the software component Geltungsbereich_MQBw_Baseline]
  composition sw component type Geltungsbereich_MQBw_Baseline
    provide port P_CAN_CanDataOut_Frame_0: provided-interface=isrCanDataOut
    require port P_CAN_GliwaDataIn_Frame: required-interface=isrGliwaDataIn
    provide port P_CAN_GliwaDataOut_Frame: provided-interface=isrGliwaDataOut
    provide port P_CAN_MF_Frame: provided-interface=isrMFCanData
    provide port P_CAN_MF_Logger_Frame: provided-interface=isrMfLoggerCanData
    13 x require port:
      RP_IF_AB_Crash_Int_XIX_eCS: required-interface=IF_AB_Crash_Int
      RP_IF_AB_Gurtschloss_BF_XIX_eCS: required-interface=IF_AB_Gurtschloss_BF
      RP_IF_AB_Gurtschloss_FA_XIX_eCS: required-interface=IF_AB_Gurtschloss_FA
      RP_IF_AB_Gurtschloss_Reihe2_BF_XIX_eCS: required-interface=IF_AB_Gurtschloss_Reihe2_BF
      RP_IF_AB_Gurtschloss_Reihe2_FA_XIX_eCS: required-interface=IF_AB_Gurtschloss_Reihe2_FA
      RP_IF_AB_Gurtschloss_Reihe3_BF_XIX_eCS: required-interface=IF_AB_Gurtschloss_Reihe3_BF
      RP_IF_AB_Gurtschloss_Reihe3_FA_XIX_eCS: required-interface=IF_AB_Gurtschloss_Reihe3_FA
      RP_IF_AB_eCS_Aktuatortest_BF_XIX_eCS: required-interface=IF_AB_eCS_Aktuatortest_BF
      RP_IF_AB_eCS_Aktuatortest_FA_XIX_eCS: required-interface=IF_AB_eCS_Aktuatortest_FA
      RP_IF_AB_eCS_Aktuatortest_Reihe2_BF_XIX_eCS: required-interface=IF_AB_eCS_Aktuatortest_Reihe2_BF
      RP_IF_AB_eCS_Aktuatortest_Reihe2_FA_XIX_eCS: required-interface=IF_AB_eCS_Aktuatortest_Reihe2_FA
      RP_IF_AB_eCS_Aktuatortest_Reihe3_BF_XIX_eCS: required-interface=IF_AB_eCS_Aktuatortest_Reihe3_BF
      RP_IF_AB_eCS_Aktuatortest_Reihe3_FA_XIX_eCS: required-interface=IF_AB_eCS_Aktuatortest_Reihe3_FA
    21 x provide port:
      SP_IF_eCS_Error_Reihe1_BFS_1: provided-interface=IF_eCS_Error_Reihe1_BFS_1
      SP_IF_eCS_Error_Reihe1_BFS_2: provided-interface=IF_eCS_Error_Reihe1_BFS_2
      SP_IF_eCS_Error_Reihe1_FS_1: provided-interface=IF_eCS_Error_Reihe1_FS_1
      SP_IF_eCS_Error_Reihe1_FS_2: provided-interface=IF_eCS_Error_Reihe1_FS_2
      SP_IF_eCS_Error_Reihe2_BFS: provided-interface=IF_eCS_Error_Reihe2_BFS
      SP_IF_eCS_Error_Reihe2_FS: provided-interface=IF_eCS_Error_Reihe2_FS
      SP_IF_eCS_Gurtschloss_Status_Reihe2_BF_XIX_eCS: provided-interface=IF_eCS_Gurtschloss_Status_Reihe2_BF
      SP_IF_eCS_Gurtschloss_Status_Reihe2_FA_XIX_eCS: provided-interface=IF_eCS_Gurtschloss_Status_Reihe2_FA
      SP_IF_eCS_HW_defekt_XIX_eCS: provided-interface=IF_eCS_HW_defekt
      SP_IF_eCS_SBS_Belegung_Reihe2_BF_XIX_eCS: provided-interface=IF_eCS_SBS_Belegung_Reihe2_BF
      SP_IF_eCS_SBS_Belegung_Reihe2_FA_XIX_eCS: provided-interface=IF_eCS_SBS_Belegung_Reihe2_FA
      SP_IF_eCS_SBS_LastState_Reihe2_BFS: provided-interface=IF_eCS_SBS_LastState_Reihe2_BFS
      SP_IF_eCS_SBS_LastState_Reihe2_FS: provided-interface=IF_eCS_SBS_LastState_Reihe2_FS
      SP_IF_eCS_Status_Verr_Reihe1_BFS_1: provided-interface=IF_eCS_Status_Verr_Reihe1_BFS_1
      SP_IF_eCS_Status_Verr_Reihe1_BFS_2: provided-interface=IF_eCS_Status_Verr_Reihe1_BFS_2
      SP_IF_eCS_Status_Verr_Reihe1_FS_1: provided-interface=IF_eCS_Status_Verr_Reihe1_FS_1
      SP_IF_eCS_Status_Verr_Reihe1_FS_2: provided-interface=IF_eCS_Status_Verr_Reihe1_FS_2
      SP_IF_eCS_Status_Verr_Reihe2_BFS: provided-interface=IF_eCS_Status_Verr_Reihe2_BFS
      SP_IF_eCS_Status_Verr_Reihe2_FS: provided-interface=IF_eCS_Status_Verr_Reihe2_FS
      SP_IF_eCS_Status_XIX_eCS: provided-interface=IF_eCS_Status
      SP_IF_eCS_Stoerung_XIX_eCS: provided-interface=IF_eCS_Stoerung
    component Grundumfang_XIX_eCS: type=Grundumfang_XIX_eCS
    connectors delegation-sw-connector={inner-port=Grundumfang_XIX_eCS.P_CAN_GliwaDataIn_Frame, outer-port=Geltungsbereich_MQBw_Baseline/P_CAN_GliwaDataIn_Frame}, delegation-sw-connector={inner-port=Grundumfang_XIX_eCS.SP_IF_eCS_Error_Reihe1_BFS_1, outer-port=Geltungsbereich_MQBw_Baseline/SP_IF_eCS_Error_Reihe1_BFS_1}, delegation-sw-connector={inner-port=Grundumfang_XIX_eCS.SP_IF_eCS_Error_Reihe1_BFS_2, outer-port=Geltungsbereich_MQBw_Baseline/SP_IF_eCS_Error_Reihe1_BFS_2}, delegation-sw-connector={inner-port=Grundumfang_XIX_eCS.SP_IF_eCS_Error_Reihe1_FS_1, outer-port=Geltungsbereich_MQBw_Baseline/SP_IF_eCS_Error_Reihe1_FS_1}, delegation-sw-connector={inner-port=Grundumfang_XIX_eCS.SP_IF_eCS_Error_Reihe1_FS_2, outer-port=Geltungsbereich_MQBw_Baseline/SP_IF_eCS_Error_Reihe1_FS_2}, delegation-sw-connector={inner-port=Grundumfang_XIX_eCS.SP_IF_eCS_Error_Reihe2_BFS, outer-port=Geltungsbereich_MQBw_Baseline/SP_IF_eCS_Error_Reihe2_BFS}, delegation-sw-connector={inner-port=Grundumfang_XIX_eCS.SP_IF_eCS_Error_Reihe2_FS, outer-port=Geltungsbereich_MQBw_Baseline/SP_IF_eCS_Error_Reihe2_FS}, delegation-sw-connector={inner-port=Grundumfang_XIX_eCS.SP_IF_eCS_SBS_LastState_Reihe2_BFS, outer-port=Geltungsbereich_MQBw_Baseline/SP_IF_eCS_SBS_LastState_Reihe2_BFS}, delegation-sw-connector={inner-port=Grundumfang_XIX_eCS.SP_IF_eCS_SBS_LastState_Reihe2_FS, outer-port=Geltungsbereich_MQBw_Baseline/SP_IF_eCS_SBS_LastState_Reihe2_FS}, delegation-sw-connector={inner-port=Grundumfang_XIX_eCS.SP_IF_eCS_Status_Verr_Reihe1_BFS_1, outer-port=Geltungsbereich_MQBw_Baseline/SP_IF_eCS_Status_Verr_Reihe1_BFS_1}, delegation-sw-connector={inner-port=Grundumfang_XIX_eCS.SP_IF_eCS_Status_Verr_Reihe1_BFS_2, outer-port=Geltungsbereich_MQBw_Baseline/SP_IF_eCS_Status_Verr_Reihe1_BFS_2}, delegation-sw-connector={inner-port=Grundumfang_XIX_eCS.SP_IF_eCS_Status_Verr_Reihe1_FS_1, outer-port=Geltungsbereich_MQBw_Baseline/SP_IF_eCS_Status_Verr_Reihe1_FS_1}, delegation-sw-connector={inner-port=Grundumfang_XIX_eCS.SP_IF_eCS_Status_Verr_Reihe1_FS_2, outer-port=Geltungsbereich_MQBw_Baseline/SP_IF_eCS_Status_Verr_Reihe1_FS_2}, delegation-sw-connector={inner-port=Grundumfang_XIX_eCS.SP_IF_eCS_Status_Verr_Reihe2_BFS, outer-port=Geltungsbereich_MQBw_Baseline/SP_IF_eCS_Status_Verr_Reihe2_BFS}, delegation-sw-connector={inner-port=Grundumfang_XIX_eCS.SP_IF_eCS_Status_Verr_Reihe2_FS, outer-port=Geltungsbereich_MQBw_Baseline/SP_IF_eCS_Status_Verr_Reihe2_FS}:
      delegate Grundumfang_XIX_eCS.RP_IF_AB_Crash_Int_XIX_Grundumfang_XIX_eCS <-> outer port RP_IF_AB_Crash_Int_XIX_eCS
      delegate Grundumfang_XIX_eCS.RP_IF_AB_Gurtschloss_BF_XIX_Grundumfang_XIX_eCS <-> outer port RP_IF_AB_Gurtschloss_BF_XIX_eCS
      delegate Grundumfang_XIX_eCS.RP_IF_AB_Gurtschloss_FA_XIX_Grundumfang_XIX_eCS <-> outer port RP_IF_AB_Gurtschloss_FA_XIX_eCS
      delegate Grundumfang_XIX_eCS.RP_IF_AB_Gurtschloss_Reihe2_BF_XIX_Grundumfang_XIX_eCS <-> outer port RP_IF_AB_Gurtschloss_Reihe2_BF_XIX_eCS
      delegate Grundumfang_XIX_eCS.RP_IF_AB_Gurtschloss_Reihe2_FA_XIX_Grundumfang_XIX_eCS <-> outer port RP_IF_AB_Gurtschloss_Reihe2_FA_XIX_eCS
      delegate Grundumfang_XIX_eCS.RP_IF_AB_Gurtschloss_Reihe3_BF_XIX_Grundumfang_XIX_eCS <-> outer port RP_IF_AB_Gurtschloss_Reihe3_BF_XIX_eCS
      delegate Grundumfang_XIX_eCS.RP_IF_AB_Gurtschloss_Reihe3_FA_XIX_Grundumfang_XIX_eCS <-> outer port RP_IF_AB_Gurtschloss_Reihe3_FA_XIX_eCS
      delegate Grundumfang_XIX_eCS.RP_IF_AB_eCS_Aktuatortest_BF_XIX_Grundumfang_XIX_eCS <-> outer port RP_IF_AB_eCS_Aktuatortest_BF_XIX_eCS
      delegate Grundumfang_XIX_eCS.RP_IF_AB_eCS_Aktuatortest_FA_XIX_Grundumfang_XIX_eCS <-> outer port RP_IF_AB_eCS_Aktuatortest_FA_XIX_eCS
      delegate Grundumfang_XIX_eCS.RP_IF_AB_eCS_Aktuatortest_Reihe2_BF_XIX_Grundumfang_XIX_eCS <-> outer port RP_IF_AB_eCS_Aktuatortest_Reihe2_BF_XIX_eCS
      delegate Grundumfang_XIX_eCS.RP_IF_AB_eCS_Aktuatortest_Reihe2_FA_XIX_Grundumfang_XIX_eCS <-> outer port RP_IF_AB_eCS_Aktuatortest_Reihe2_FA_XIX_eCS
      delegate Grundumfang_XIX_eCS.RP_IF_AB_eCS_Aktuatortest_Reihe3_BF_XIX_Grundumfang_XIX_eCS <-> outer port RP_IF_AB_eCS_Aktuatortest_Reihe3_BF_XIX_eCS
      delegate Grundumfang_XIX_eCS.RP_IF_AB_eCS_Aktuatortest_Reihe3_FA_XIX_Grundumfang_XIX_eCS <-> outer port RP_IF_AB_eCS_Aktuatortest_Reihe3_FA_XIX_eCS
      delegate Grundumfang_XIX_eCS.SP_IF_eCS_Gurtschloss_Status_Reihe2_BF_XIX_Grundumfang_XIX_eCS <-> outer port SP_IF_eCS_Gurtschloss_Status_Reihe2_BF_XIX_eCS
      delegate Grundumfang_XIX_eCS.SP_IF_eCS_Gurtschloss_Status_Reihe2_FA_XIX_Grundumfang_XIX_eCS <-> outer port SP_IF_eCS_Gurtschloss_Status_Reihe2_FA_XIX_eCS
      delegate Grundumfang_XIX_eCS.SP_IF_eCS_HW_defekt_XIX_Grundumfang_XIX_eCS <-> outer port SP_IF_eCS_HW_defekt_XIX_eCS
      delegate Grundumfang_XIX_eCS.SP_IF_eCS_SBS_Belegung_Reihe2_BF_XIX_Grundumfang_XIX_eCS <-> outer port SP_IF_eCS_SBS_Belegung_Reihe2_BF_XIX_eCS
      delegate Grundumfang_XIX_eCS.SP_IF_eCS_SBS_Belegung_Reihe2_FA_XIX_Grundumfang_XIX_eCS <-> outer port SP_IF_eCS_SBS_Belegung_Reihe2_FA_XIX_eCS
      delegate Grundumfang_XIX_eCS.SP_IF_eCS_Status_XIX_Grundumfang_XIX_eCS <-> outer port SP_IF_eCS_Status_XIX_eCS
      delegate Grundumfang_XIX_eCS.SP_IF_eCS_Stoerung_XIX_Grundumfang_XIX_eCS <-> outer port SP_IF_eCS_Stoerung_XIX_eCS
      delegate Grundumfang_XIX_eCS.P_CAN_CanDataOut_Frame_0 <-> outer port Geltungsbereich_MQBw_Baseline/P_CAN_CanDataOut_Frame_0
      delegate Grundumfang_XIX_eCS.P_CAN_GliwaDataOut_Frame <-> outer port Geltungsbereich_MQBw_Baseline/P_CAN_GliwaDataOut_Frame
      delegate Grundumfang_XIX_eCS.P_CAN_MF_Frame <-> outer port Geltungsbereich_MQBw_Baseline/P_CAN_MF_Frame
      delegate Grundumfang_XIX_eCS.P_CAN_MF_Loger_Frame <-> outer port P_CAN_MF_Logger_Frame
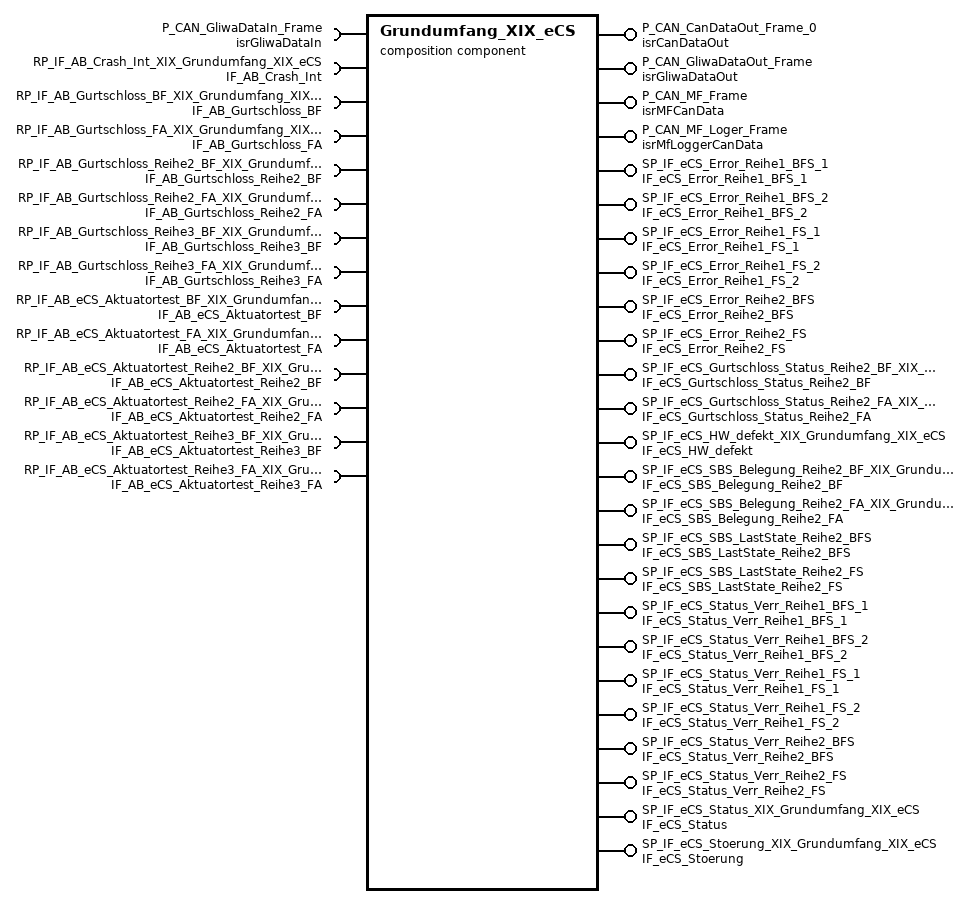
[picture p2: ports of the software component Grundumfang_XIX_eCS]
  composition sw component type Grundumfang_XIX_eCS
    provide port P_CAN_CanDataOut_Frame_0: provided-interface=isrCanDataOut
    require port P_CAN_GliwaDataIn_Frame: required-interface=isrGliwaDataIn
    provide port P_CAN_GliwaDataOut_Frame: provided-interface=isrGliwaDataOut
    provide port P_CAN_MF_Frame: provided-interface=isrMFCanData
    provide port P_CAN_MF_Loger_Frame: provided-interface=isrMfLoggerCanData
    13 x require port:
      RP_IF_AB_Crash_Int_XIX_Grundumfang_XIX_eCS: required-interface=IF_AB_Crash_Int
      RP_IF_AB_Gurtschloss_BF_XIX_Grundumfang_XIX_eCS: required-interface=IF_AB_Gurtschloss_BF
      RP_IF_AB_Gurtschloss_FA_XIX_Grundumfang_XIX_eCS: required-interface=IF_AB_Gurtschloss_FA
      RP_IF_AB_Gurtschloss_Reihe2_BF_XIX_Grundumfang_XIX_eCS: required-interface=IF_AB_Gurtschloss_Reihe2_BF
      RP_IF_AB_Gurtschloss_Reihe2_FA_XIX_Grundumfang_XIX_eCS: required-interface=IF_AB_Gurtschloss_Reihe2_FA
      RP_IF_AB_Gurtschloss_Reihe3_BF_XIX_Grundumfang_XIX_eCS: required-interface=IF_AB_Gurtschloss_Reihe3_BF
      RP_IF_AB_Gurtschloss_Reihe3_FA_XIX_Grundumfang_XIX_eCS: required-interface=IF_AB_Gurtschloss_Reihe3_FA
      RP_IF_AB_eCS_Aktuatortest_BF_XIX_Grundumfang_XIX_eCS: required-interface=IF_AB_eCS_Aktuatortest_BF
      RP_IF_AB_eCS_Aktuatortest_FA_XIX_Grundumfang_XIX_eCS: required-interface=IF_AB_eCS_Aktuatortest_FA
      RP_IF_AB_eCS_Aktuatortest_Reihe2_BF_XIX_Grundumfang_XIX_eCS: required-interface=IF_AB_eCS_Aktuatortest_Reihe2_BF
      RP_IF_AB_eCS_Aktuatortest_Reihe2_FA_XIX_Grundumfang_XIX_eCS: required-interface=IF_AB_eCS_Aktuatortest_Reihe2_FA
      RP_IF_AB_eCS_Aktuatortest_Reihe3_BF_XIX_Grundumfang_XIX_eCS: required-interface=IF_AB_eCS_Aktuatortest_Reihe3_BF
      RP_IF_AB_eCS_Aktuatortest_Reihe3_FA_XIX_Grundumfang_XIX_eCS: required-interface=IF_AB_eCS_Aktuatortest_Reihe3_FA
    21 x provide port:
      SP_IF_eCS_Error_Reihe1_BFS_1: provided-interface=IF_eCS_Error_Reihe1_BFS_1
      SP_IF_eCS_Error_Reihe1_BFS_2: provided-interface=IF_eCS_Error_Reihe1_BFS_2
      SP_IF_eCS_Error_Reihe1_FS_1: provided-interface=IF_eCS_Error_Reihe1_FS_1
      SP_IF_eCS_Error_Reihe1_FS_2: provided-interface=IF_eCS_Error_Reihe1_FS_2
      SP_IF_eCS_Error_Reihe2_BFS: provided-interface=IF_eCS_Error_Reihe2_BFS
      SP_IF_eCS_Error_Reihe2_FS: provided-interface=IF_eCS_Error_Reihe2_FS
      SP_IF_eCS_Gurtschloss_Status_Reihe2_BF_XIX_Grundumfang_XIX_eCS: provided-interface=IF_eCS_Gurtschloss_Status_Reihe2_BF
      SP_IF_eCS_Gurtschloss_Status_Reihe2_FA_XIX_Grundumfang_XIX_eCS: provided-interface=IF_eCS_Gurtschloss_Status_Reihe2_FA
      SP_IF_eCS_HW_defekt_XIX_Grundumfang_XIX_eCS: provided-interface=IF_eCS_HW_defekt
      SP_IF_eCS_SBS_Belegung_Reihe2_BF_XIX_Grundumfang_XIX_eCS: provided-interface=IF_eCS_SBS_Belegung_Reihe2_BF
      SP_IF_eCS_SBS_Belegung_Reihe2_FA_XIX_Grundumfang_XIX_eCS: provided-interface=IF_eCS_SBS_Belegung_Reihe2_FA
      SP_IF_eCS_SBS_LastState_Reihe2_BFS: provided-interface=IF_eCS_SBS_LastState_Reihe2_BFS
      SP_IF_eCS_SBS_LastState_Reihe2_FS: provided-interface=IF_eCS_SBS_LastState_Reihe2_FS
      SP_IF_eCS_Status_Verr_Reihe1_BFS_1: provided-interface=IF_eCS_Status_Verr_Reihe1_BFS_1
      SP_IF_eCS_Status_Verr_Reihe1_BFS_2: provided-interface=IF_eCS_Status_Verr_Reihe1_BFS_2
      SP_IF_eCS_Status_Verr_Reihe1_FS_1: provided-interface=IF_eCS_Status_Verr_Reihe1_FS_1
      SP_IF_eCS_Status_Verr_Reihe1_FS_2: provided-interface=IF_eCS_Status_Verr_Reihe1_FS_2
      SP_IF_eCS_Status_Verr_Reihe2_BFS: provided-interface=IF_eCS_Status_Verr_Reihe2_BFS
      SP_IF_eCS_Status_Verr_Reihe2_FS: provided-interface=IF_eCS_Status_Verr_Reihe2_FS
      SP_IF_eCS_Status_XIX_Grundumfang_XIX_eCS: provided-interface=IF_eCS_Status
      SP_IF_eCS_Stoerung_XIX_Grundumfang_XIX_eCS: provided-interface=IF_eCS_Stoerung
    component S32K_eCS_ECU_Application: type=S32K_eCS_ECU_Application
    component S32K_eCS_ECU_Autosar_Interfaces: type=S32K_eCS_ECU_Autosar_Interfaces
    connectors delegation-sw-connector={inner-port=S32K_eCS_ECU_Application.SP_IF_eCS_Gurtschloss_Status_Reihe2_BF_XIX_Grundumfang_XIX_eCS, outer-port=SP_IF_eCS_Gurtschloss_Status_Reihe2_BF_XIX_Grundumfang_XIX_eCS}, delegation-sw-connector={inner-port=S32K_eCS_ECU_Application.SP_IF_eCS_Gurtschloss_Status_Reihe2_FA_XIX_Grundumfang_XIX_eCS, outer-port=SP_IF_eCS_Gurtschloss_Status_Reihe2_FA_XIX_Grundumfang_XIX_eCS}, delegation-sw-connector={inner-port=S32K_eCS_ECU_Application.RP_IF_AB_Crash_Int_XIX_Grundumfang_XIX_eCS, outer-port=RP_IF_AB_Crash_Int_XIX_Grundumfang_XIX_eCS}, delegation-sw-connector={inner-port=S32K_eCS_ECU_Application.RP_IF_AB_Gurtschloss_BF_XIX_Grundumfang_XIX_eCS, outer-port=RP_IF_AB_Gurtschloss_BF_XIX_Grundumfang_XIX_eCS}, delegation-sw-connector={inner-port=S32K_eCS_ECU_Application.RP_IF_AB_Gurtschloss_FA_XIX_Grundumfang_XIX_eCS, outer-port=RP_IF_AB_Gurtschloss_FA_XIX_Grundumfang_XIX_eCS}, delegation-sw-connector={inner-port=S32K_eCS_ECU_Application.RP_IF_AB_Gurtschloss_Reihe2_BF_XIX_Grundumfang_XIX_eCS, outer-port=RP_IF_AB_Gurtschloss_Reihe2_BF_XIX_Grundumfang_XIX_eCS}, delegation-sw-connector={inner-port=S32K_eCS_ECU_Application.RP_IF_AB_Gurtschloss_Reihe2_FA_XIX_Grundumfang_XIX_eCS, outer-port=RP_IF_AB_Gurtschloss_Reihe2_FA_XIX_Grundumfang_XIX_eCS}, delegation-sw-connector={inner-port=S32K_eCS_ECU_Application.RP_IF_AB_Gurtschloss_Reihe3_BF_XIX_Grundumfang_XIX_eCS, outer-port=RP_IF_AB_Gurtschloss_Reihe3_BF_XIX_Grundumfang_XIX_eCS}, delegation-sw-connector={inner-port=S32K_eCS_ECU_Application.RP_IF_AB_Gurtschloss_Reihe3_FA_XIX_Grundumfang_XIX_eCS, outer-port=RP_IF_AB_Gurtschloss_Reihe3_FA_XIX_Grundumfang_XIX_eCS}, delegation-sw-connector={inner-port=S32K_eCS_ECU_Application.RP_IF_AB_eCS_Aktuatortest_BF_XIX_Grundumfang_XIX_eCS, outer-port=RP_IF_AB_eCS_Aktuatortest_BF_XIX_Grundumfang_XIX_eCS}, delegation-sw-connector={inner-port=S32K_eCS_ECU_Application.RP_IF_AB_eCS_Aktuatortest_FA_XIX_Grundumfang_XIX_eCS, outer-port=RP_IF_AB_eCS_Aktuatortest_FA_XIX_Grundumfang_XIX_eCS}, delegation-sw-connector={inner-port=S32K_eCS_ECU_Application.RP_IF_AB_eCS_Aktuatortest_Reihe2_BF_XIX_Grundumfang_XIX_eCS, outer-port=RP_IF_AB_eCS_Aktuatortest_Reihe2_BF_XIX_Grundumfang_XIX_eCS}, delegation-sw-connector={inner-port=S32K_eCS_ECU_Application.RP_IF_AB_eCS_Aktuatortest_Reihe2_FA_XIX_Grundumfang_XIX_eCS, outer-port=RP_IF_AB_eCS_Aktuatortest_Reihe2_FA_XIX_Grundumfang_XIX_eCS}, delegation-sw-connector={inner-port=S32K_eCS_ECU_Application.RP_IF_AB_eCS_Aktuatortest_Reihe3_BF_XIX_Grundumfang_XIX_eCS, outer-port=RP_IF_AB_eCS_Aktuatortest_Reihe3_BF_XIX_Grundumfang_XIX_eCS}, delegation-sw-connector={inner-port=S32K_eCS_ECU_Application.RP_IF_AB_eCS_Aktuatortest_Reihe3_FA_XIX_Grundumfang_XIX_eCS, outer-port=RP_IF_AB_eCS_Aktuatortest_Reihe3_FA_XIX_Grundumfang_XIX_eCS}, delegation-sw-connector={inner-port=S32K_eCS_ECU_Application.SP_IF_eCS_HW_defekt_XIX_Grundumfang_XIX_eCS, outer-port=SP_IF_eCS_HW_defekt_XIX_Grundumfang_XIX_eCS}, delegation-sw-connector={inner-port=S32K_eCS_ECU_Application.SP_IF_eCS_SBS_Belegung_Reihe2_BF_XIX_Grundumfang_XIX_eCS, outer-port=SP_IF_eCS_SBS_Belegung_Reihe2_BF_XIX_Grundumfang_XIX_eCS}, delegation-sw-connector={inner-port=S32K_eCS_ECU_Application.SP_IF_eCS_SBS_Belegung_Reihe2_FA_XIX_Grundumfang_XIX_eCS, outer-port=SP_IF_eCS_SBS_Belegung_Reihe2_FA_XIX_Grundumfang_XIX_eCS}, delegation-sw-connector={inner-port=S32K_eCS_ECU_Application.SP_IF_eCS_Status_XIX_Grundumfang_XIX_eCS, outer-port=SP_IF_eCS_Status_XIX_Grundumfang_XIX_eCS}, delegation-sw-connector={inner-port=S32K_eCS_ECU_Application.SP_IF_eCS_Stoerung_XIX_Grundumfang_XIX_eCS, outer-port=SP_IF_eCS_Stoerung_XIX_Grundumfang_XIX_eCS}, delegation-sw-connector={inner-port=S32K_eCS_ECU_Application.SP_IF_eCS_Error_Reihe1_BFS_1, outer-port=Grundumfang_XIX_eCS/SP_IF_eCS_Error_Reihe1_BFS_1}, delegation-sw-connector={inner-port=S32K_eCS_ECU_Application.SP_IF_eCS_Error_Reihe1_BFS_2, outer-port=Grundumfang_XIX_eCS/SP_IF_eCS_Error_Reihe1_BFS_2}, delegation-sw-connector={inner-port=S32K_eCS_ECU_Application.SP_IF_eCS_Error_Reihe1_FS_1, outer-port=Grundumfang_XIX_eCS/SP_IF_eCS_Error_Reihe1_FS_1}, delegation-sw-connector={inner-port=S32K_eCS_ECU_Application.SP_IF_eCS_Error_Reihe1_FS_2, outer-port=Grundumfang_XIX_eCS/SP_IF_eCS_Error_Reihe1_FS_2}, delegation-sw-connector={inner-port=S32K_eCS_ECU_Application.SP_IF_eCS_Error_Reihe2_BFS, outer-port=Grundumfang_XIX_eCS/SP_IF_eCS_Error_Reihe2_BFS}, delegation-sw-connector={inner-port=S32K_eCS_ECU_Application.SP_IF_eCS_Error_Reihe2_FS, outer-port=Grundumfang_XIX_eCS/SP_IF_eCS_Error_Reihe2_FS}, delegation-sw-connector={inner-port=S32K_eCS_ECU_Application.SP_IF_eCS_SBS_LastState_Reihe2_BFS, outer-port=Grundumfang_XIX_eCS/SP_IF_eCS_SBS_LastState_Reihe2_BFS}, delegation-sw-connector={inner-port=S32K_eCS_ECU_Application.SP_IF_eCS_SBS_LastState_Reihe2_FS, outer-port=Grundumfang_XIX_eCS/SP_IF_eCS_SBS_LastState_Reihe2_FS}, delegation-sw-connector={inner-port=S32K_eCS_ECU_Application.SP_IF_eCS_Status_Verr_Reihe1_BFS_1, outer-port=Grundumfang_XIX_eCS/SP_IF_eCS_Status_Verr_Reihe1_BFS_1}, delegation-sw-connector={inner-port=S32K_eCS_ECU_Application.SP_IF_eCS_Status_Verr_Reihe1_BFS_2, outer-port=Grundumfang_XIX_eCS/SP_IF_eCS_Status_Verr_Reihe1_BFS_2}, delegation-sw-connector={inner-port=S32K_eCS_ECU_Application.SP_IF_eCS_Status_Verr_Reihe1_FS_1, outer-port=Grundumfang_XIX_eCS/SP_IF_eCS_Status_Verr_Reihe1_FS_1}, delegation-sw-connector={inner-port=S32K_eCS_ECU_Application.SP_IF_eCS_Status_Verr_Reihe1_FS_2, outer-port=Grundumfang_XIX_eCS/SP_IF_eCS_Status_Verr_Reihe1_FS_2}, delegation-sw-connector={inner-port=S32K_eCS_ECU_Application.SP_IF_eCS_Status_Verr_Reihe2_BFS, outer-port=Grundumfang_XIX_eCS/SP_IF_eCS_Status_Verr_Reihe2_BFS}, delegation-sw-connector={inner-port=S32K_eCS_ECU_Application.SP_IF_eCS_Status_Verr_Reihe2_FS, outer-port=Grundumfang_XIX_eCS/SP_IF_eCS_Status_Verr_Reihe2_FS}:
      connect S32K_eCS_ECU_Application.ptrpAsrBswMServicesBswMIf -> S32K_eCS_ECU_Autosar_Interfaces.ptrrAsrBswMServicesBswMIf
      connect S32K_eCS_ECU_Application.ptrpAsrCanServicesEcuMIf -> S32K_eCS_ECU_Autosar_Interfaces.ptrrAsrCanServicesEcuMIf
      connect S32K_eCS_ECU_Application.ptrpAsrComServicesNmIf -> S32K_eCS_ECU_Autosar_Interfaces.ptrrAsrComServicesNmIf
      connect S32K_eCS_ECU_Application.ptrpAsrDcmServicesDcmIf -> S32K_eCS_ECU_Autosar_Interfaces.ptrrAsrDcmServicesDcmIf
      connect S32K_eCS_ECU_Application.ptrpAsrDemServicesDemIf -> S32K_eCS_ECU_Autosar_Interfaces.ptrrAsrDemServicesDemIf
      connect S32K_eCS_ECU_Application.ptrpAsrEcuMServicesEcuMIf -> S32K_eCS_ECU_Autosar_Interfaces.ptrrAsrEcuMServicesEcuMIf
      connect S32K_eCS_ECU_Application.ptrpAsrEcuMServicesSbc -> S32K_eCS_ECU_Autosar_Interfaces.ptrrAsrEcuMServicesSbc
      connect S32K_eCS_ECU_Application.ptrpAsrGptServicesAdcIf -> S32K_eCS_ECU_Autosar_Interfaces.ptrrAsrGptServicesAdcIf
      connect S32K_eCS_ECU_Application.ptrpAsrGptServicesBswMIf -> S32K_eCS_ECU_Autosar_Interfaces.ptrrAsrGptServicesBswMIf
      connect S32K_eCS_ECU_Application.ptrpAsrNvMServicesBswMIf -> S32K_eCS_ECU_Autosar_Interfaces.ptrrAsrNvMServicesBswMIf
      connect S32K_eCS_ECU_Application.ptrpAsrOsServicesATM -> S32K_eCS_ECU_Autosar_Interfaces.ptrrAsrOsServicesATM
      connect S32K_eCS_ECU_Application.ptrpAsrOsServicesBswMIf -> S32K_eCS_ECU_Autosar_Interfaces.ptrrAsrOsServicesBswMIf
      connect S32K_eCS_ECU_Application.ptrpAsrOsServicesIoHwAb -> S32K_eCS_ECU_Autosar_Interfaces.ptrrAsrOsServicesIoHwAb
      connect S32K_eCS_ECU_Application.ptrpAsrOsServicesLpm -> S32K_eCS_ECU_Autosar_Interfaces.ptrrAsrOsServicesLpm
      connect S32K_eCS_ECU_Application.ptrpAsrOsServicesNmIf -> S32K_eCS_ECU_Autosar_Interfaces.ptrrAsrOsServicesNmIf
      connect S32K_eCS_ECU_Application.ptrpAsrOsServicesACC -> S32K_eCS_ECU_Autosar_Interfaces.ptrrAsrOsServicesACC
      connect S32K_eCS_ECU_Application.ptrpAsrOsServicesCIL -> S32K_eCS_ECU_Autosar_Interfaces.ptrrAsrOsServicesCIL
      connect S32K_eCS_ECU_Application.ptrpAsrOsServicesECS -> S32K_eCS_ECU_Autosar_Interfaces.ptrrAsrOsServicesECS
      connect S32K_eCS_ECU_Application.ptrpAsrOsServicesFSM -> S32K_eCS_ECU_Autosar_Interfaces.ptrrAsrOsServicesFSM
      connect S32K_eCS_ECU_Application.ptrpAsrOsServicesOsIf -> S32K_eCS_ECU_Autosar_Interfaces.ptrrAsrOsServicesOsIf
      connect S32K_eCS_ECU_Application.ptrpAsrOsServicesSAD -> S32K_eCS_ECU_Autosar_Interfaces.ptrrAsrOsServicesSAD
      connect S32K_eCS_ECU_Application.ptrpAsrOsServicesSBC -> S32K_eCS_ECU_Autosar_Interfaces.ptrrAsrOsServicesSBC
      connect S32K_eCS_ECU_Application.ptrpAsrOsServicesSTM -> S32K_eCS_ECU_Autosar_Interfaces.ptrrAsrOsServicesSTM
      connect S32K_eCS_ECU_Autosar_Interfaces.ptrpAsrAdcServicesAdcIf -> S32K_eCS_ECU_Application.ptrrAsrAdcServiceAdcIf
      connect S32K_eCS_ECU_Autosar_Interfaces.ptrpAsrAdcServicesEcuMIf -> S32K_eCS_ECU_Application.ptrrAsrAdcServicesEcuMIf
      connect S32K_eCS_ECU_Autosar_Interfaces.ptrpAsrBswMServicesBswMIf -> S32K_eCS_ECU_Application.ptrrAsrBswMServicesBswMIf
      connect S32K_eCS_ECU_Autosar_Interfaces.ptrpAsrBswMServicesNmIf -> S32K_eCS_ECU_Application.ptrrAsrBswMServicesNmIf
      connect S32K_eCS_ECU_Autosar_Interfaces.ptrpAsrBswMServicesOsIf -> S32K_eCS_ECU_Application.ptrrAsrBswMServicesOsIf
      connect S32K_eCS_ECU_Autosar_Interfaces.ptrpAsrCanIfServicesBswMIf -> S32K_eCS_ECU_Application.ptrrAsrCanIfServicesBswMIf
      connect S32K_eCS_ECU_Autosar_Interfaces.ptrpAsrCanIfServicesEcuMIf -> S32K_eCS_ECU_Application.ptrrAsrCanIfServicesEcuMIf
      connect S32K_eCS_ECU_Autosar_Interfaces.ptrpAsrCanSMServicesBswMIf -> S32K_eCS_ECU_Application.ptrrAsrCanSMServicesBswMIf
      connect S32K_eCS_ECU_Autosar_Interfaces.ptrpAsrCanServicesBswMIf -> S32K_eCS_ECU_Application.ptrrAsrCanServicesBswMIf
      connect S32K_eCS_ECU_Autosar_Interfaces.ptrpAsrCanServicesEcuMIf -> S32K_eCS_ECU_Application.ptrrAsrCanServicesEcuMIf
      connect S32K_eCS_ECU_Autosar_Interfaces.ptrpAsrCanTpServicesBswMIf -> S32K_eCS_ECU_Application.ptrrAsrCanTpServicesBswMIf
      connect S32K_eCS_ECU_Autosar_Interfaces.ptrpAsrComMServicesBswMIf -> S32K_eCS_ECU_Application.ptrrAsrComMServicesBswMIf
      connect S32K_eCS_ECU_Autosar_Interfaces.ptrpAsrComMServicesNmIf -> S32K_eCS_ECU_Application.ptrrAsrComMServicesNmIf
      connect S32K_eCS_ECU_Autosar_Interfaces.ptrpAsrComServicesBswMIf -> S32K_eCS_ECU_Application.ptrrAsrComServicesBswMIf
      connect S32K_eCS_ECU_Autosar_Interfaces.ptrpAsrDcmServicesBswMIf -> S32K_eCS_ECU_Application.ptrrAsrDcmServicesBswMIf
      connect S32K_eCS_ECU_Autosar_Interfaces.ptrpAsrDemServicesBswMIf -> S32K_eCS_ECU_Application.ptrrAsrDemServicesBswMIf
      connect S32K_eCS_ECU_Autosar_Interfaces.ptrpAsrDemServicesEcuMIf -> S32K_eCS_ECU_Application.ptrrAsrDemServicesEcuMIf
      connect S32K_eCS_ECU_Autosar_Interfaces.ptrpAsrDioServicesDioIf -> S32K_eCS_ECU_Application.ptrrAsrDioServicesDioIf
      connect S32K_eCS_ECU_Autosar_Interfaces.ptrpAsrEcuMServicesBswMIf -> S32K_eCS_ECU_Application.ptrrAsrEcuMServicesBswMIf
      connect S32K_eCS_ECU_Autosar_Interfaces.ptrpAsrEcuMServicesEcuMIf -> S32K_eCS_ECU_Application.ptrrAsrEcuMServicesEcuMIf
      connect S32K_eCS_ECU_Autosar_Interfaces.ptrpAsrEcuMServicesOsIf -> S32K_eCS_ECU_Application.ptrrAsrEcuMServicesOsIf
      connect S32K_eCS_ECU_Autosar_Interfaces.ptrpAsrFeeServicesBswMIf -> S32K_eCS_ECU_Application.ptrrAsrFeeServicesBswMIf
      connect S32K_eCS_ECU_Autosar_Interfaces.ptrpAsrFeeServicesEcuMIf -> S32K_eCS_ECU_Application.ptrrAsrFeeServicesEcuMIf
      connect S32K_eCS_ECU_Autosar_Interfaces.ptrpAsrFlsServicesBswMIf -> S32K_eCS_ECU_Application.ptrrAsrFlsServicesBswMIf
      connect S32K_eCS_ECU_Autosar_Interfaces.ptrpAsrFlsServicesEcuMIf -> S32K_eCS_ECU_Application.ptrrAsrFlsServicesEcuMIf
      connect S32K_eCS_ECU_Autosar_Interfaces.ptrpAsrGptServicesAdcIf -> S32K_eCS_ECU_Application.ptrrAsrGptServicesAdcIf
      connect S32K_eCS_ECU_Autosar_Interfaces.ptrpAsrGptServicesBswMIf -> S32K_eCS_ECU_Application.ptrrAsrGptServicesBswMIf
      connect S32K_eCS_ECU_Autosar_Interfaces.ptrpAsrNvMServicesBswMIf -> S32K_eCS_ECU_Application.ptrrAsrNvMServicesBswMIf
      connect S32K_eCS_ECU_Autosar_Interfaces.ptrpAsrOsServicesBswMIf -> S32K_eCS_ECU_Application.ptrrAsrOsServicesBswMIf
      connect S32K_eCS_ECU_Autosar_Interfaces.ptrpAsrPduRServicesBswMIf -> S32K_eCS_ECU_Application.ptrrAsrPduRServicesBswMIf
      connect S32K_eCS_ECU_Autosar_Interfaces.ptrpAsrPwmServicesEcuMIf -> S32K_eCS_ECU_Application.ptrrAsrPwmServicesEcuMIf
      connect S32K_eCS_ECU_Autosar_Interfaces.ptrpAsrPwmServicesPwmIf -> S32K_eCS_ECU_Application.ptrrAsrPwmServicesPwmIf
      connect S32K_eCS_ECU_Autosar_Interfaces.ptrpAsrRteServicesBswMIf -> S32K_eCS_ECU_Application.ptrrAsrRteServicesBswMIf
      connect S32K_eCS_ECU_Autosar_Interfaces.ptrpAsrSpiServicesEcuMIf -> S32K_eCS_ECU_Application.ptrrAsrSpiServicesEcuMIf
      connect S32K_eCS_ECU_Autosar_Interfaces.ptrpAsrSpiServicesSpiIf -> S32K_eCS_ECU_Application.ptrrAsrSpiServicesSpiIf
      connect S32K_eCS_ECU_Autosar_Interfaces.ptrpMcuServicesEcuMIf -> S32K_eCS_ECU_Application.ptrrAsrMcuServicesEcuMIf
      delegate S32K_eCS_ECU_Application.P_CAN_CanDataOut_Frame_0 <-> outer port Grundumfang_XIX_eCS/P_CAN_CanDataOut_Frame_0
      delegate S32K_eCS_ECU_Application.P_CAN_GliwaDataIn_Frame <-> outer port Grundumfang_XIX_eCS/P_CAN_GliwaDataIn_Frame
      delegate S32K_eCS_ECU_Application.P_CAN_GliwaDataOut_Frame <-> outer port Grundumfang_XIX_eCS/P_CAN_GliwaDataOut_Frame
      delegate S32K_eCS_ECU_Application.P_CAN_MF_Frame <-> outer port Grundumfang_XIX_eCS/P_CAN_MF_Frame
      delegate S32K_eCS_ECU_Application.P_CAN_MF_Logger_Frame <-> outer port P_CAN_MF_Loger_Frame
package /Constraints
  range DC_AB_Abschaltanf_SIH_BF: raw 0..1
  range DC_AB_Anforderung_USM: raw 0..1
  range DC_AB_Anforderung_eCall: raw 0..1
  range DC_AB_Anprall_FGS: raw 0..1
  range DC_AB_Anprall_Front_Beifahrer: raw 0..1
  range DC_AB_Anprall_Front_Fahrer: raw 0..1
  range DC_AB_Anprall_Heck_Beifahrer: raw 0..1
  range DC_AB_Anprall_Heck_Fahrer: raw 0..1
  range DC_AB_Anprall_Rollover: raw 0..1
  range DC_AB_Anprall_Seite_Beifahrer: raw 0..1
  range DC_AB_Anprall_Seite_Fahrer: raw 0..1
  range DC_AB_Anzeige_Fussg: raw 0..2
  range DC_AB_Belegung_VB: raw 0..3
  range DC_AB_Belegung_VF: raw 0..3
  range DC_AB_Crash_Int: raw 0..7
  range DC_AB_Crashschwere: raw 0..7
  range DC_AB_Deaktiviert: raw 0..1
  range DC_AB_Deaktivierung_HV: raw 0..7
  range DC_AB_Diagnose: raw 0..1
  range DC_AB_EDR_Trigger: raw 0..3
  range DC_AB_Erh_Auf_VB: raw 0..3
  range DC_AB_Front_Crash: raw 0..1
  range DC_AB_Gurtschloss_BF: raw 0..3
  range DC_AB_Gurtschloss_FA: raw 0..3
  range DC_AB_Gurtschloss_FA_ext: raw 0..7
  range DC_AB_Gurtschloss_FA_ext_aktiv: raw 0..1
  range DC_AB_Gurtschloss_Reihe2_BF: raw 0..3
  range DC_AB_Gurtschloss_Reihe2_FA: raw 0..3
  range DC_AB_Gurtschloss_Reihe2_MI: raw 0..3
  range DC_AB_Gurtschloss_Reihe3_BF: raw 0..3
  range DC_AB_Gurtschloss_Reihe3_FA: raw 0..3
  range DC_AB_Gurtschloss_Reihe3_MI: raw 0..3
  range DC_AB_Gurtwarn_VB: raw 0..1
  range DC_AB_Gurtwarn_VF: raw 0..1
  range DC_AB_Heck_Crash: raw 0..1
  range DC_AB_Lampe: raw 0..1
  range DC_AB_MKB_Anforderung: raw 0..1
  range DC_AB_MKB_gueltig: raw 0..1
  range DC_AB_PAO_Leuchte_Anf: raw 0..1
  range DC_AB_RGS_Anst: raw 4..8
  range DC_AB_Rollover_Crash: raw 0..1
  range DC_AB_SB_Crash: raw 0..1
  range DC_AB_SF_Crash: raw 0..1
  range DC_AB_Sitzpos_Sens_BF: raw 0..3
  range DC_AB_Sitzpos_Sens_FA: raw 0..3
  range DC_AB_Stellgliedtest: raw 0..1
  range DC_AB_Systemfehler: raw 0..1
  range DC_AB_Texte_AKS: raw 0..2
  range DC_AB_VB_deaktiviert: raw 0..1
  range DC_AB_Versorgungsspannung: raw 0..1
  range DC_AB_Wickelklappung_Reihe2_BF: raw 0..3
  range DC_AB_Wickelklappung_Reihe2_FA: raw 0..3
  range DC_AB_Wickelklappung_Reihe2_MI: raw 0..3
  range DC_AB_eCS_Aktuatortest_BF: raw 0..3
  range DC_AB_eCS_Aktuatortest_FA: raw 0..3
  range DC_AB_eCS_Aktuatortest_Reihe2_BF: raw 0..3
  range DC_AB_eCS_Aktuatortest_Reihe2_FA: raw 0..3
  range DC_AB_eCS_Aktuatortest_Reihe3_BF: raw 0..3
  range DC_AB_eCS_Aktuatortest_Reihe3_FA: raw 0..3
  range DC_AB_eCS_Error: raw 0..1
  range DC_ASM_Masterzeit_02: phys 0..10.16 Unit_Secon, raw 0..255
  range DC_Airbag_01_BZ: phys 0..15, raw 0..15
  range DC_Airbag_01_CRC: phys 0..255, raw 0..255
  range DC_Airbag_02_BZ: phys 0..15, raw 0..15
  range DC_Airbag_02_CRC: phys 0..255, raw 0..255
  range DC_LoGeWa_Event_Kombiwarnung: raw 0..5
  range DC_SC_PAO_OFF_Anf: raw 0..3
  range DC_SC_PAO_ON_Anf: raw 0..3
  range DC_SC_PAO_Schriftzug_Anf: raw 0..3
  range DC_eCS_Gurtschloss_Status_Reihe2_BF: raw 0..3
  range DC_eCS_Gurtschloss_Status_Reihe2_FA: raw 0..3
  range DC_eCS_HW_defekt: raw 0..1
  range DC_eCS_SBS_Belegung_Reihe2_BF: raw 0..3
  range DC_eCS_SBS_Belegung_Reihe2_FA: raw 0..3
  range DC_eCS_Status: raw 0..3
  range DC_eCS_Stoerung: raw 0..1
  range dcMfLogger: raw 0..255
package /DiagnosticServices
  4 x diagnostic connection:
    DC_eCS_XIX_TPCHType_CANFD_Diag
    DC_eCS_XIX_TPCHType_CANFD_Flash_DIA
    DC_eCS_XIX_TPCHType_CANFD_OBDC_SSN_Diagnose
    DC_eCS_XIX_TPCHType_CANHS_Flash_DIA
  diagnostic service table DST_eCS
    diagnostic-connections:
      DC_eCS_XIX_TPCHType_CANFD_Diag
      DC_eCS_XIX_TPCHType_CANFD_Flash_DIA
      DC_eCS_XIX_TPCHType_CANFD_OBDC_SSN_Diagnose
      DC_eCS_XIX_TPCHType_CANHS_Flash_DIA
package /EcuInstancePackage
  ecu instance Airbag: associated-com-i-pdu-group=[IPDUGroupIN_Airbag, IPDUGroupOUT_Airbag], com-configuration-rx-time-base=0.05, com-configuration-tx-time-base=0.01, sleep-mode-supported=false, wake-up-over-bus-supported=false
    can communication controller CHNL_Controller
    can communication controller ctl_MQBw_Baseline_Airbag_SUBCANFD_KMatrix_V14_09_00_01E_20230404_MH_Alv: can-controller-attributes=can-controller-configuration={sync-jump-width=0, time-seg-1=0, time-seg-2=0}
    can communication connector CanCommunicationConnector_0: comm-controller=Airbag/CHNL_Controller
    can communication connector cc_MQBw_Baseline_Airbag_SUBCANFD_KMatrix_V14_09_00_01E_202304041_MH_Alv: comm-controller=Airbag/ctl_MQBw_Baseline_Airbag_SUBCANFD_KMatrix_V14_09_00_01E_20230404_MH_Alv  # cc_MQBw_Baseline_Airbag_SUBCANFD_KMatrix_V14_09_00_01E_20230404_MH_Alv
  ecu instance eCS: associated-com-i-pdu-group=[IPDUGroupIN_eCS, IPDUGroupOUT_eCS, IPDUGroupOUT_eCS_Comm], com-configuration-rx-time-base=0.01, com-configuration-tx-time-base=0.05, sleep-mode-supported=false, wake-up-over-bus-supported=false
    can communication controller CHNL_Controller
    can communication controller ctl_MQBw_Baseline_Airbag_SUBCANFD_KMatrix_V14_09_00_01E_20230404_MH_Alv: can-controller-attributes=can-controller-configuration={sync-jump-width=0, time-seg-1=0, time-seg-2=0}
    can communication connector CanCommunicationConnector_1: comm-controller=eCS/CHNL_Controller
    can communication connector cc_MQBw_Baseline_Airbag_SUBCANFD_KMatrix_V14_09_00_01E_20230404_MH_Alv: comm-controller=eCS/ctl_MQBw_Baseline_Airbag_SUBCANFD_KMatrix_V14_09_00_01E_20230404_MH_Alv
package /FramePackage
  i signal MF_Logger_Byte_0: data-type-policy=OVERRIDE, handle-out-of-range=IGNORE, init-value=KU8_ZERO:0, length=8, base-type=uint8, system-signal=MF_Logger_Byte_0
  84 x constant specification:
    cst_init_sys_AB_Abschaltanf_SIH_BF
    cst_init_sys_AB_Anforderung_USM
    cst_init_sys_AB_Anforderung_eCall
    cst_init_sys_AB_Anprall_FGS
    cst_init_sys_AB_Anprall_Front_Beifahrer
    cst_init_sys_AB_Anprall_Front_Fahrer
    cst_init_sys_AB_Anprall_Heck_Beifahrer
    cst_init_sys_AB_Anprall_Heck_Fahrer
    cst_init_sys_AB_Anprall_Rollover
    cst_init_sys_AB_Anprall_Seite_Beifahrer
    cst_init_sys_AB_Anprall_Seite_Fahrer
    cst_init_sys_AB_Anzeige_Fussg
    cst_init_sys_AB_Belegung_VB
    cst_init_sys_AB_Belegung_VF
    cst_init_sys_AB_Crash_Int
    cst_init_sys_AB_Crashschwere
    cst_init_sys_AB_Deaktiviert
    cst_init_sys_AB_Deaktivierung_HV
    cst_init_sys_AB_Diagnose
    cst_init_sys_AB_EDR_Trigger
    cst_init_sys_AB_Erh_Auf_VB
    cst_init_sys_AB_Front_Crash
    cst_init_sys_AB_Gurtschloss_BF
    cst_init_sys_AB_Gurtschloss_FA
    cst_init_sys_AB_Gurtschloss_FA_ext
    cst_init_sys_AB_Gurtschloss_FA_ext_aktiv
    cst_init_sys_AB_Gurtschloss_Reihe2_BF
    cst_init_sys_AB_Gurtschloss_Reihe2_FA
    cst_init_sys_AB_Gurtschloss_Reihe2_MI
    cst_init_sys_AB_Gurtschloss_Reihe3_BF
    cst_init_sys_AB_Gurtschloss_Reihe3_FA
    cst_init_sys_AB_Gurtschloss_Reihe3_MI
    cst_init_sys_AB_Gurtwarn_VB
    cst_init_sys_AB_Gurtwarn_VF
    cst_init_sys_AB_Heck_Crash
    cst_init_sys_AB_Lampe
    cst_init_sys_AB_MKB_Anforderung
    cst_init_sys_AB_MKB_gueltig
    cst_init_sys_AB_PAO_Leuchte_Anf
    cst_init_sys_AB_RGS_Anst
    cst_init_sys_AB_Rollover_Crash
    cst_init_sys_AB_SB_Crash
    cst_init_sys_AB_SF_Crash
    cst_init_sys_AB_Sitzpos_Sens_BF
    cst_init_sys_AB_Sitzpos_Sens_FA
    cst_init_sys_AB_Stellgliedtest
    cst_init_sys_AB_Systemfehler
    cst_init_sys_AB_Texte_AKS
    cst_init_sys_AB_VB_deaktiviert
    cst_init_sys_AB_Versorgungsspannung
    cst_init_sys_AB_Wickelklappung_Reihe2_BF
    cst_init_sys_AB_Wickelklappung_Reihe2_FA
    cst_init_sys_AB_Wickelklappung_Reihe2_MI
    cst_init_sys_AB_eCS_Aktuatortest_BF
    cst_init_sys_AB_eCS_Aktuatortest_FA
    cst_init_sys_AB_eCS_Aktuatortest_Reihe2_BF
    cst_init_sys_AB_eCS_Aktuatortest_Reihe2_FA
    cst_init_sys_AB_eCS_Aktuatortest_Reihe3_BF
    cst_init_sys_AB_eCS_Aktuatortest_Reihe3_FA
    cst_init_sys_AB_eCS_Error
    cst_init_sys_ASM_Masterzeit_02
    cst_init_sys_Airbag_01_BZ
    cst_init_sys_Airbag_01_CRC
    cst_init_sys_Airbag_02_BZ
    cst_init_sys_Airbag_02_CRC
    cst_init_sys_DIA_eCS_Req_Data
    cst_init_sys_DIA_eCS_Req_FD_Data
    cst_init_sys_DIA_eCS_Resp_Data
    cst_init_sys_DIA_eCS_Resp_FD_Data
    cst_init_sys_Diag_eCS_Req_FD_Data
    cst_init_sys_Diag_eCS_Resp_FD_Data
    cst_init_sys_LoGeWa_Event_Kombiwarnung
    cst_init_sys_OBDC_SSN_eCS_Req_FD_Data
    cst_init_sys_OBDC_SSN_eCS_Resp_FD_Data
    cst_init_sys_SC_PAO_OFF_Anf
    cst_init_sys_SC_PAO_ON_Anf
    cst_init_sys_SC_PAO_Schriftzug_Anf
    cst_init_sys_eCS_Gurtschloss_Status_Reihe2_BF
    cst_init_sys_eCS_Gurtschloss_Status_Reihe2_FA
    cst_init_sys_eCS_HW_defekt
    cst_init_sys_eCS_SBS_Belegung_Reihe2_BF
    cst_init_sys_eCS_SBS_Belegung_Reihe2_FA
    cst_init_sys_eCS_Status
    cst_init_sys_eCS_Stoerung
package /HwElementPackage
  hw element Airbag_ECUType
  hw element eCS_ECUType
package /IPduPackage
  pdu ipdu_DIA_eCS_Req: length=8, transmission-mode-true-timing=cyclic-timing={time-offset=0.0, time-period=0.0}
    signal is_DIA_eCS_Req_Data1: start 0, 64 bit, little-endian, system signal sys_DIA_eCS_Req_Data, init-value=0, base-type=BasetypePackage/uint64, transfer-property=TRIGGERED  # Diagnose Request Flashen <SG-Name>  # Airbag_SUBCANFD_V14.09.00.01E Generated by BUSNETNG Produktiv 9.24.6
  pdu ipdu_DIA_eCS_Req_FD: length=64, transmission-mode-true-timing=cyclic-timing={time-offset=0.0, time-period=0.0}
    signal is_DIA_eCS_Req_FD_Data1: start 0, 512 bit, little-endian, system signal sys_DIA_eCS_Req_FD_Data, init-value=0, base-type=uint512, transfer-property=TRIGGERED  # Diagnose Request Flashen eCS  # Airbag_SUBCANFD_V14.09.00.01E Generated by BUSNETNG Produktiv 9.24.6
  pdu ipdu_DIA_eCS_Resp: length=8, transmission-mode-true-timing=cyclic-timing={time-offset=0.0, time-period=0.0}
    signal is_DIA_eCS_Resp_Data1: start 0, 64 bit, little-endian, system signal sys_DIA_eCS_Resp_Data, init-value=0, base-type=BasetypePackage/uint64, transfer-property=TRIGGERED  # Diagnose Response Flashen <SG-Name>  # Airbag_SUBCANFD_V14.09.00.01E Generated by BUSNETNG Produktiv 9.24.6
  pdu ipdu_DIA_eCS_Resp_FD: length=64, transmission-mode-true-timing=cyclic-timing={time-offset=0.0, time-period=0.0}
    signal is_DIA_eCS_Resp_FD_Data1: start 0, 512 bit, little-endian, system signal sys_DIA_eCS_Resp_FD_Data, init-value=0, base-type=uint512, transfer-property=TRIGGERED  # Diagnose Response Flashen eCS  # Airbag_SUBCANFD_V14.09.00.01E Generated by BUSNETNG Produktiv 9.24.6
  pdu ipdu_Diag_eCS_Req_FD: length=64, transmission-mode-true-timing=cyclic-timing={time-offset=0.0, time-period=0.0}
    signal is_Diag_eCS_Req_FD_Data1: start 0, 512 bit, little-endian, system signal sys_Diag_eCS_Req_FD_Data, init-value=0, base-type=uint512, transfer-property=TRIGGERED  # UDS-Diagnose ISO-TP Datenkanal - FID2NA Request Funktion 0x07 Diagnosezugriff vom DK4-Master auf DK1/2-Knoten 0x742  # Airbag_SUBCANFD_V14.09.00.01E Generated by BUSNETNG Produktiv 9.24.6
  pdu ipdu_Diag_eCS_Resp_FD: length=64, transmission-mode-true-timing=cyclic-timing={time-offset=0.0, time-period=0.0}
    signal is_Diag_eCS_Resp_FD_Data1: start 0, 512 bit, little-endian, system signal sys_Diag_eCS_Resp_FD_Data, init-value=0, base-type=uint512, transfer-property=TRIGGERED, to Airbag  # UDS-Diganose ISO-TP Datenkanal - FID2NA Response DK1/2-Knoten 0x742 an Funktion 0x07 Diagnosezugriff vom DK4-Master  # Airbag_SUBCANFD_V14.09.00.01E Generated by BUSNETNG Produktiv 9.24.6
  pdu ipdu_OBDC_SSN_eCS_Req_FD: length=64, transmission-mode-true-timing=cyclic-timing={time-offset=0.0, time-period=0.0}
    signal is_OBDC_SSN_eCS_Req_FD_Data1: start 0, 512 bit, little-endian, system signal sys_OBDC_SSN_eCS_Req_FD_Data, init-value=0, base-type=uint512, transfer-property=TRIGGERED, to eCS  # Request FID- zu NA- Kommunikation zw. OnboardDiagnoseClient und DK2F Sub-System  # Airbag_SUBCANFD_V14.09.00.01E Generated by BUSNETNG Produktiv 9.24.6
  pdu ipdu_OBDC_SSN_eCS_Resp_FD: length=64, transmission-mode-true-timing=cyclic-timing={time-offset=0.0, time-period=0.0}
    signal is_OBDC_SSN_eCS_Resp_FD_Data1: start 0, 512 bit, little-endian, system signal sys_OBDC_SSN_eCS_Resp_FD_Data, init-value=0, base-type=uint512, transfer-property=TRIGGERED  # Response FID- zu NA- Kommunikation zw. OnboardDiagnoseClient und DK2F Sub-System  # Airbag_SUBCANFD_V14.09.00.01E Generated by BUSNETNG Produktiv 9.24.6
package /ISignalIPdugroupPackage
  5 x i signal i pdu group:
    IPDUGroupIN_Airbag: communication-direction=IN, communication-mode=Normal
      i-signal-i-pdus:
        ipdu_DIA_eCS_Resp
        ipdu_DIA_eCS_Resp_FD
        ipdu_Diag_eCS_Resp_FD
        ipdu_eCS_01
        ipdu_OBDC_SSN_eCS_Resp_FD
        IPdu_Dev_Out_0
        IPdu_MFData
        IPdu_Gliwa_Out
        IPdu_MFData_Logger
    IPDUGroupIN_eCS: communication-direction=IN
      i-signal-i-pdus:
        ipdu_Airbag_01
        ipdu_Airbag_02
        ipdu_Airbag_eCS_01
        ipdu_DIA_eCS_Req
        ipdu_DIA_eCS_Req_FD
        ipdu_Diag_eCS_Req_FD
        ipdu_OBDC_SSN_eCS_Req_FD
        IPdu_Gliwa_In
    IPDUGroupOUT_Airbag: communication-direction=OUT
      i-signal-i-pdus:
        ipdu_Airbag_01
        ipdu_Airbag_02
        ipdu_Airbag_eCS_01
        ipdu_DIA_eCS_Req
        ipdu_DIA_eCS_Req_FD
        ipdu_Diag_eCS_Req_FD
        ipdu_OBDC_SSN_eCS_Req_FD
        IPdu_Gliwa_In
    IPDUGroupOUT_eCS: communication-direction=OUT, communication-mode=Normal
      i-signal-i-pdus:
        ipdu_DIA_eCS_Resp
        ipdu_DIA_eCS_Resp_FD
        ipdu_Diag_eCS_Resp_FD
        ipdu_eCS_01
        ipdu_OBDC_SSN_eCS_Resp_FD
        IPdu_Dev_Out_0
        IPdu_MFData
        IPdu_Gliwa_Out
    IPDUGroupOUT_eCS_Comm: communication-direction=OUT, communication-mode=Normal, i-signal-i-pdus=IPdu_MFData_Logger
package /Interfaces
  35 x sender receiver interface:
    IF_AB_Crash_Int
      data DE_AB_Crash_Int: type=u8AbCrashIntType_Appl, init-value=CM_AB_Crash_Int_Cx0_kein_Crash
    IF_AB_Gurtschloss_BF
      data DE_AB_Gurtschloss_BF: type=u8GurtschlossStatusReihe2BFType_Appl, init-value=CM_eCS_Gurtschloss_Status_Reihe2_BF_Cx0_nicht_verbaut
    IF_AB_Gurtschloss_FA
      data DE_AB_Gurtschloss_FA: type=u8GurtschlossStatusReihe2BFType_Appl, init-value=CM_eCS_Gurtschloss_Status_Reihe2_BF_Cx0_nicht_verbaut
    IF_AB_Gurtschloss_Reihe2_BF
      data DE_AB_Gurtschloss_Reihe2_BF: type=u8GurtschlossStatusReihe2BFType_Appl, init-value=CM_eCS_Gurtschloss_Status_Reihe2_BF_Cx0_nicht_verbaut
    IF_AB_Gurtschloss_Reihe2_FA
      data DE_AB_Gurtschloss_Reihe2_FA: type=u8GurtschlossStatusReihe2BFType_Appl, init-value=CM_eCS_Gurtschloss_Status_Reihe2_BF_Cx0_nicht_verbaut
    IF_AB_Gurtschloss_Reihe3_BF
      data DE_AB_Gurtschloss_Reihe3_BF: type=u8GurtschlossStatusReihe2BFType_Appl, init-value=CM_eCS_Gurtschloss_Status_Reihe2_BF_Cx0_nicht_verbaut
    IF_AB_Gurtschloss_Reihe3_FA
      data DE_AB_Gurtschloss_Reihe3_FA: type=u8GurtschlossStatusReihe2BFType_Appl, init-value=CM_eCS_Gurtschloss_Status_Reihe2_BF_Cx0_nicht_verbaut
    IF_AB_eCS_Aktuatortest_BF
      data DE_AB_eCS_Aktuatortest_BF: type=u8AbAktuatorTestBFType_Appl, init-value=CM_AB_eCS_Aktuatortest_BF_Cx0_Keine_Aktion
    IF_AB_eCS_Aktuatortest_FA
      data DE_AB_eCS_Aktuatortest_FA: type=u8AbAktuatorTestFAType_Appl, init-value=CM_AB_eCS_Aktuatortest_FA_Cx0_Keine_Aktion
    IF_AB_eCS_Aktuatortest_Reihe2_BF
      data DE_AB_eCS_Aktuatortest_Reihe2_BF: type=u8AbAktuatorTestReihe2BFType_Appl, init-value=CM_AB_eCS_Aktuatortest_Reihe2_BF_Cx0_Keine_Aktion
    IF_AB_eCS_Aktuatortest_Reihe2_FA
      data DE_AB_eCS_Aktuatortest_Reihe2_FA: type=u8AbAktuatorTestReihe2FAType_Appl, init-value=CM_AB_eCS_Aktuatortest_Reihe2_FA_Cx0_Keine_Aktion
    IF_AB_eCS_Aktuatortest_Reihe3_BF
      data DE_AB_eCS_Aktuatortest_Reihe3_BF: type=u8AbAktuatorTestReihe3BFType_Appl, init-value=Cx0_Keine_Aktion
    IF_AB_eCS_Aktuatortest_Reihe3_FA
      data DE_AB_eCS_Aktuatortest_Reihe3_FA: type=u8AbAktuatorTestReihe3FAType_Appl, init-value=CM_AB_eCS_Aktuatortest_Reihe3_FA_Cx0_Keine_Aktion
    IF_eCS_Error_Reihe1_BFS_1
      data DE_eCS_Error_Reihe1_BFS_1: type=u8Error_Reihe1_BFS_1Type_Appl, init-value=Cx0_kein_Fehler
    IF_eCS_Error_Reihe1_BFS_2
      data DE_eCS_Error_Reihe1_BFS_2: type=u8Error_Reihe1_BFS_2Type_Appl, init-value=Cx0_kein_Fehler
    IF_eCS_Error_Reihe1_FS_1
      data DE_eCS_Error_Reihe1_FS_1: type=u8Error_Reihe1_FS_1Type_Appl, init-value=Cx0_kein_Fehler
    IF_eCS_Error_Reihe1_FS_2
      data DE_eCS_Error_Reihe1_FS_2: type=u8Error_Reihe1_FS_2Type_Appl, init-value=Cx0_kein_Fehler
    IF_eCS_Error_Reihe2_BFS
      data DE_eCS_Error_Reihe2_BFS: type=u8Error_Reihe2_BFSType_Appl, init-value=Cx0_kein_Fehler
    IF_eCS_Error_Reihe2_FS
      data DE_eCS_Error_Reihe2_FS: type=u8Error_Reihe2_FSType_Appl, init-value=Cx0_kein_Fehler
    IF_eCS_Gurtschloss_Status_Reihe2_BF
      data DE_eCS_Gurtschloss_Status_Reihe2_BF: type=u8GurtschlossStatusReihe2BFType_Appl, init-value=CM_eCS_Gurtschloss_Status_Reihe2_BF_Cx0_nicht_verbaut
    IF_eCS_Gurtschloss_Status_Reihe2_FA
      data DE_eCS_Gurtschloss_Status_Reihe2_FA: type=u8GurtschlossStatusReihe2FAType_Appl, init-value=CM_eCS_Gurtschloss_Status_Reihe2_FA_Cx0_nicht_verbaut
    IF_eCS_HW_defekt
      data DE_eCS_HW_defekt: type=u8eCSHwErrorType_Appl, init-value=CM_eCS_HW_defekt_Cx0_nicht_defekt
    IF_eCS_SBS_Belegung_Reihe2_BF
      data DE_eCS_SBS_Belegung_Reihe2_BF: type=u8SbsBelegungReihe2BFType_Appl, init-value=CM_eCS_SBS_Belegung_Reihe2_BF_Cx0_nicht_verfuegbar
    IF_eCS_SBS_Belegung_Reihe2_FA
      data DE_eCS_SBS_Belegung_Reihe2_FA: type=u8SbsBelegungReihe2FAType_Appl, init-value=CM_eCS_SBS_Belegung_Reihe2_FA_Cx0_nicht_verfuegbar
    IF_eCS_SBS_LastState_Reihe2_BFS
      data DE_eCS_SBS_LastState_Reihe2_BFS: type=u8SBS_LastState_Reihe2_BFSType_Appl, init-value=Cx0_Init
    IF_eCS_SBS_LastState_Reihe2_FS
      data DE_eCS_SBS_LastState_Reihe2_FS: type=u8SBS_LastState_Reihe2_FSType_Appl, init-value=Cx0_Init
    IF_eCS_Status
      data DE_eCS_Status: type=u8eCSStatusType_Appl, init-value=CM_eCS_Status_Cx0_Init
    IF_eCS_Status_Verr_Reihe1_BFS_1
      data DE_eCS_Status_Verr_Reihe1_BFS_1: type=u8Status_Verr_Reihe1_BFS_1Type_Appl, init-value=Cx0_Init_oder_Fehler
    IF_eCS_Status_Verr_Reihe1_BFS_2
      data DE_eCS_Status_Verr_Reihe1_BFS_2: type=u8Status_Verr_Reihe1_BFS_2Type_Appl, init-value=Cx0_Init_oder_Fehler
    IF_eCS_Status_Verr_Reihe1_FS_1
      data DE_eCS_Status_Verr_Reihe1_FS_1: type=u8Status_Verr_Reihe1_FS_1Type_Appl, init-value=Cx0_Init_oder_Fehler
    IF_eCS_Status_Verr_Reihe1_FS_2
      data DE_eCS_Status_Verr_Reihe1_FS_2: type=u8Status_Verr_Reihe1_FS_2Type_Appl, init-value=Cx0_Init_oder_Fehler
    IF_eCS_Status_Verr_Reihe2_BFS
      data DE_eCS_Status_Verr_Reihe2_BFS: type=u8Status_Verr_Reihe2_BFSType_Appl, init-value=Cx0_Init_oder_Fehler
    IF_eCS_Status_Verr_Reihe2_FS
      data DE_eCS_Status_Verr_Reihe2_FS: type=u8Status_Verr_Reihe2_FSType_Appl, init-value=Cx0_Init_oder_Fehler
    IF_eCS_Stoerung
      data DE_eCS_Stoerung: type=u8eCSStoerungErrorType_Appl, init-value=CM_eCS_Stoerung_Cx0_keine_Stoerung
    isrSbcFailiureSource
      data u32SbcReg1Status: type=u32SbcFailiureCauseType_Appl, init-value=0
package /MQBw_Baseline
  system System: category=SYSTEM_EXTRACT, ecu-extract-version=2022.09.15, system-version=14.09.00.01E
    system mapping System
      data-mappings:
        sender-receiver-to-signal-mapping={communication-direction=IN, data-element=Grundumfang_XIX_eCS.Geltungsbereich_MQBw_Baseline.RP_IF_AB_Crash_Int_XIX_Grundumfang_XIX_eCS.DE_AB_Crash_Int, system-signal=sys_AB_Crash_Int}
        sender-receiver-to-signal-group-mapping={communication-direction=OUT, data-element=Grundumfang_XIX_eCS.Geltungsbereich_MQBw_Baseline.P_CAN_MF_Frame.stMFData, signal-group=MeasurementFrameGroup, type-mapping=sender-rec-record-type-mapping=record-element-mappings=[u64Byte_0_7, u64Byte_8_15, u64Byte_16_23, u64Byte_24_31, u64Byte_32_39, u64Byte_40_47, u64Byte_48_55, u64Byte_56_63, u8Byte7, u8Byte8, u8Byte9, u8Byte10, u8Byte11, u8Byte12, u8Byte13, u8Byte14, u8Byte15, u8Byte16, u8Byte17, u8Byte18, u8Byte19, u8Byte20, u8Byte21, u8Byte22, u8Byte23, u8Byte24, u8Byte25, u8Byte26, u8Byte27, u8Byte28, u8Byte29, u8Byte30, u8Byte31, u8Byte32, u8Byte33, u8Byte34, u8Byte35, u8Byte36, u8Byte37, u8Byte38, u8Byte39, u8Byte40, u8Byte41, u8Byte42, u8Byte43, u8Byte44, u8Byte45, u8Byte46, u8Byte47, u8Byte48, u8Byte49, u8Byte50, u8Byte51, u8Byte52, u8Byte53, u8Byte54, u8Byte55, u8Byte56, u8Byte57, u8Byte58, u8Byte59, u8Byte60, u8Byte61, u8Byte62]}
        sender-receiver-to-signal-group-mapping={communication-direction=OUT, data-element=Grundumfang_XIX_eCS.Geltungsbereich_MQBw_Baseline.P_CAN_CanDataOut_Frame_0.EcuCanDataOut, signal-group=DataOutGroup_0, type-mapping=sender-rec-record-type-mapping=record-element-mappings=[u8Byte0, u8Byte1, u8Byte2, u8Byte3, u8Byte4, u8Byte5, u8Byte6, u8Byte7, u8Byte8, u8Byte9, u8Byte10, u8Byte11, u8Byte12, u8Byte13, u8Byte14, u8Byte15, u8Byte16, u8Byte17, u8Byte18, u8Byte19, u8Byte20, u8Byte21, u8Byte22, u8Byte23, u8Byte24, u8Byte25, u8Byte26, u8Byte27, u8Byte28, u8Byte29, u8Byte30, u8Byte31, u8Byte32, u8Byte33, u8Byte34, u8Byte35, u8Byte36, u8Byte37, u8Byte38, u8Byte39, u8Byte40, u8Byte41, u8Byte42, u8Byte43, u8Byte44, u8Byte45, u8Byte46, u8Byte47, u8Byte48, u8Byte49, u8Byte50, u8Byte51, u8Byte52, u8Byte53, u8Byte54, u8Byte55, u8Byte56, u8Byte57, u8Byte58, u8Byte59, u8Byte60, u8Byte61, u8Byte62, u8Byte63]}
      sw-impl-mappings:
        24 x swc to impl mapping:
          ACC_ImplMapping: component-implementation=ACC_imp, component=Geltungsbereich_MQBw_Baseline.Grundumfang_XIX_eCS.S32K_eCS_ECU_Application.ACC
          ATM_ImplMapping: component-implementation=ATM_imp, component=Geltungsbereich_MQBw_Baseline.Grundumfang_XIX_eCS.S32K_eCS_ECU_Application.ATM
          AdcIf_ImplMapping: component-implementation=AdcIf_imp, component=Geltungsbereich_MQBw_Baseline.Grundumfang_XIX_eCS.S32K_eCS_ECU_Application.AdcIf
          BswMIf_ImplMapping: component-implementation=BswMIf_imp, component=Geltungsbereich_MQBw_Baseline.Grundumfang_XIX_eCS.S32K_eCS_ECU_Application.BswMIf
          CIL_ImplMapping: component-implementation=CIL_impCommunicationInteractionLayer, component=Geltungsbereich_MQBw_Baseline.Grundumfang_XIX_eCS.S32K_eCS_ECU_Application.CIL
          DIA_ImplMapping: component-implementation=DIA_imp, component=Geltungsbereich_MQBw_Baseline.Grundumfang_XIX_eCS.S32K_eCS_ECU_Application.DIA
          DcmIf_ImplMapping: component-implementation=DcmIf_imp, component=Geltungsbereich_MQBw_Baseline.Grundumfang_XIX_eCS.S32K_eCS_ECU_Application.DcmIf
          DemIf_ImplMapping: component-implementation=DemIf_imp, component=Geltungsbereich_MQBw_Baseline.Grundumfang_XIX_eCS.S32K_eCS_ECU_Application.DemIf
          DioIf_ImplMapping: component-implementation=DioIf_imp, component=Geltungsbereich_MQBw_Baseline.Grundumfang_XIX_eCS.S32K_eCS_ECU_Application.DioIf
          EcuMIf_ImplMapping: component-implementation=EcuMIf_imp, component=Geltungsbereich_MQBw_Baseline.Grundumfang_XIX_eCS.S32K_eCS_ECU_Application.EcuMIf
          FSM_ImplMapping: component-implementation=FSM_imp, component=Geltungsbereich_MQBw_Baseline.Grundumfang_XIX_eCS.S32K_eCS_ECU_Application.FSM
          IoHwAb_ImplMapping: component-implementation=IoHwAb_imp, component=Geltungsbereich_MQBw_Baseline.Grundumfang_XIX_eCS.S32K_eCS_ECU_Application.IoHwAb
          MIC_ImplMapping: component-implementation=MIC_impMemoryIntegrityControl, component=Geltungsbereich_MQBw_Baseline.Grundumfang_XIX_eCS.S32K_eCS_ECU_Application.MIC
          NVP_ImplMapping: component-implementation=NVP_impNonVolatileParameters, component=Geltungsbereich_MQBw_Baseline.Grundumfang_XIX_eCS.S32K_eCS_ECU_Application.NVP
          NmIf_ImplMapping: component-implementation=NmIf_imp, component=Geltungsbereich_MQBw_Baseline.Grundumfang_XIX_eCS.S32K_eCS_ECU_Application.NmIf
          NvmIf_ImplMapping: component-implementation=NvmIf_imp, component=Geltungsbereich_MQBw_Baseline.Grundumfang_XIX_eCS.S32K_eCS_ECU_Application.NvmIf
          OsIf_ImplMapping: component-implementation=OsIf_imp, component=Geltungsbereich_MQBw_Baseline.Grundumfang_XIX_eCS.S32K_eCS_ECU_Application.OsIf
          PwmIf_ImplMapping: component-implementation=PwmIf_imp, component=Geltungsbereich_MQBw_Baseline.Grundumfang_XIX_eCS.S32K_eCS_ECU_Application.PwmIf
          RCM_ImplMapping: component-implementation=RCM_imp, component=Geltungsbereich_MQBw_Baseline.Grundumfang_XIX_eCS.S32K_eCS_ECU_Application.RCM
          SAD_ImplMapping: component-implementation=SAD_imp, component=Geltungsbereich_MQBw_Baseline.Grundumfang_XIX_eCS.S32K_eCS_ECU_Application.SAD
          SBC_ImplMapping: component-implementation=SBC_imp, component=Geltungsbereich_MQBw_Baseline.Grundumfang_XIX_eCS.S32K_eCS_ECU_Application.SBC
          STM_ImplMapping: component-implementation=STM_imp, component=Geltungsbereich_MQBw_Baseline.Grundumfang_XIX_eCS.S32K_eCS_ECU_Application.STM
          SpiIf_ImplMapping: component-implementation=SpiIf_imp, component=Geltungsbereich_MQBw_Baseline.Grundumfang_XIX_eCS.S32K_eCS_ECU_Application.SpiIf
          eCS_ImplMapping: component-implementation=eCS_imp, component=Geltungsbereich_MQBw_Baseline.Grundumfang_XIX_eCS.S32K_eCS_ECU_Application.eCS
      sw-mappings:
        swc to ecu mapping AirbagMapping: ecu-instance=Airbag
        swc to ecu mapping eCSMapping: component=Geltungsbereich_MQBw_Baseline.Grundumfang_XIX_eCS.S32K_eCS_ECU_Application, ecu-instance=eCS
    root-software-compositions:
      root sw composition prototype Geltungsbereich_MQBw_Baseline: software-composition=Geltungsbereich_MQBw_Baseline
package /PDU
  dcm i pdu DCM_Airbag_SUBCANFD_XIX_TPCHType_CANFD_Diag_XIX_0x1C405206_XIX_0x1C425206_XIX_Physical: length=512, diag-pdu-type=DIAG-REQUEST
  dcm i pdu DCM_Airbag_SUBCANFD_XIX_TPCHType_CANFD_Diag_XIX_0x1C425206_XIX_0x1C405206_XIX_Physical: length=512, diag-pdu-type=DIAG-RESPONSE
  dcm i pdu DCM_Airbag_SUBCANFD_XIX_TPCHType_CANFD_Flash_DIA_XIX_0x1C404206_XIX_0x1C424206_XIX_Physical: length=512, diag-pdu-type=DIAG-REQUEST
  dcm i pdu DCM_Airbag_SUBCANFD_XIX_TPCHType_CANFD_Flash_DIA_XIX_0x1C424206_XIX_0x1C404206_XIX_Physical: length=512, diag-pdu-type=DIAG-RESPONSE
  dcm i pdu DCM_Airbag_SUBCANFD_XIX_TPCHType_CANFD_OBDC_SSN_Diagnose_XIX_0x1C407206_XIX_0x1C427206_XIX_Physical: length=512, diag-pdu-type=DIAG-REQUEST
  dcm i pdu DCM_Airbag_SUBCANFD_XIX_TPCHType_CANFD_OBDC_SSN_Diagnose_XIX_0x1C427206_XIX_0x1C407206_XIX_Physical: length=512, diag-pdu-type=DIAG-RESPONSE
  dcm i pdu DCM_Airbag_SUBCANFD_XIX_TPCHType_CANHS_Flash_DIA_XIX_0x17FC4206_XIX_0x17FE4206_XIX_Physical: length=512, diag-pdu-type=DIAG-REQUEST
  dcm i pdu DCM_Airbag_SUBCANFD_XIX_TPCHType_CANHS_Flash_DIA_XIX_0x17FE4206_XIX_0x17FC4206_XIX_Physical: length=512, diag-pdu-type=DIAG-RESPONSE
package /PhysicalDimension
  physical dimension PD_siSecond: time-exp=1
package /Semantics
  compu method CM_AB_Abschaltanf_SIH_BF: 1=Cx1_Abschaltung_angefordert (CM_AB_Abschaltanf_SIH_BF_Cx1_Abschaltung_angefordert), 0=Cx0_Normalbetrieb (CM_AB_Abschaltanf_SIH_BF_Cx0_Normalbetrieb)
  compu method CM_AB_Anforderung_USM: 0=Cx0_keine_Anforderung (CM_AB_Anforderung_USM_Cx0_keine_Anforderung), 1=Cx1_Anforderung (CM_AB_Anforderung_USM_Cx1_Anforderung)
  compu method CM_AB_Anforderung_eCall: 0=Cx0_keine_Anforderung (CM_AB_Anforderung_eCall_Cx0_keine_Anforderung), 1=Cx1_Anforderung (CM_AB_Anforderung_eCall_Cx1_Anforderung)
  compu method CM_AB_Anprall_FGS: 0=Cx0_kein_Anprall (CM_AB_Anprall_FGS_Cx0_kein_Anprall), 1=Cx1_Anprall_erkannt (CM_AB_Anprall_FGS_Cx1_Anprall_erkannt)
  compu method CM_AB_Anprall_Front_Beifahrer: 0=Cx0_kein_Anprall (CM_AB_Anprall_Front_Beifahrer_Cx0_kein_Anprall), 1=Cx1_Anprall_erkannt (CM_AB_Anprall_Front_Beifahrer_Cx1_Anprall_erkannt)
  compu method CM_AB_Anprall_Front_Fahrer: 1=Cx1_Anprall_erkannt, 0=Cx0_kein_Anprall
  compu method CM_AB_Anprall_Heck_Beifahrer: 1=Cx1_Anprall_erkannt (CM_AB_Anprall_Heck_Beifahrer_Cx1_Anprall_erkannt), 0=Cx0_kein_Anprall (CM_AB_Anprall_Heck_Beifahrer_Cx0_kein_Anprall)
  compu method CM_AB_Anprall_Heck_Fahrer: 1=Cx1_Anprall_erkannt (CM_AB_Anprall_Heck_Fahrer_Cx1_Anprall_erkannt), 0=Cx0_kein_Anprall (CM_AB_Anprall_Heck_Fahrer_Cx0_kein_Anprall)
  compu method CM_AB_Anprall_Rollover: 1=Cx1_Anprall_erkannt (CM_AB_Anprall_Rollover_Cx1_Anprall_erkannt), 0=Cx0_kein_Anprall (CM_AB_Anprall_Rollover_Cx0_kein_Anprall)
  compu method CM_AB_Anprall_Seite_Beifahrer: 1=Cx1_Anprall_erkannt (CM_AB_Anprall_Seite_Beifahrer_Cx1_Anprall_erkannt), 0=Cx0_kein_Anprall (CM_AB_Anprall_Seite_Beifahrer_Cx0_kein_Anprall)
  compu method CM_AB_Anprall_Seite_Fahrer: 1=Cx1_Anprall_erkannt (CM_AB_Anprall_Seite_Fahrer_Cx1_Anprall_erkannt), 0=Cx0_kein_Anprall (CM_AB_Anprall_Seite_Fahrer_Cx0_kein_Anprall)
  compu method CM_AB_Anzeige_Fussg: 0=Cx0_keine_FSG_Aktion_ausgeloest (CM_AB_Anzeige_Fussg_Cx0_keine_FSG_Aktion_ausgeloest), 1=Cx1_Motorhaube_offen (CM_AB_Anzeige_Fussg_Cx1_Motorhaube_offen), 2=Cx2_Systemfehler (CM_AB_Anzeige_Fussg_Cx2_Systemfehler)
  compu method CM_AB_Belegung_VB: 1=Cx1_Fehler (CM_AB_Belegung_VB_Cx1_Fehler), 0=Cx0_nicht_verfuegbar (CM_AB_Belegung_VB_Cx0_nicht_verfuegbar), 2=Cx2_nicht_belegt (CM_AB_Belegung_VB_Cx2_nicht_belegt), 3=Cx3_belegt (CM_AB_Belegung_VB_Cx3_belegt)
  compu method CM_AB_Belegung_VF: 1=Cx1_Fehler (CM_AB_Belegung_VF_Cx1_Fehler), 0=Cx0_nicht_verfuegbar (CM_AB_Belegung_VF_Cx0_nicht_verfuegbar), 2=Cx2_nicht_belegt (CM_AB_Belegung_VF_Cx2_nicht_belegt), 3=Cx3_belegt (CM_AB_Belegung_VF_Cx3_belegt)
  compu method CM_AB_Crash_Int: 3=Cx3_Crash_Intensitaet_2_nur_D4_C7_Colorado_NF_PAG_Crash_im_MLB_B8 (CM_AB_Crash_Int_Cx3_Crash_Intensitaet_2_nur_D4_C7_Colorado_NF_PAG_Crash_im_MLB_B8) (Crash_Intensitaet_2_(nur_D4_C7_Colorado_NF_PAG__Crash_im_MLB_B8)), 1=Cx1_Crash_Intensitaet_1 (CM_AB_Crash_Int_Cx1_Crash_Intensitaet_1), 5=Cx5_Crash_Intensitaet_3_alt_PAG (CM_AB_Crash_Int_Cx5_Crash_Intensitaet_3_alt_PAG) (Crash_Intensitaet_3_(alt_PAG)), 7=Cx7_Crash_Intensitaet_3 (CM_AB_Crash_Int_Cx7_Crash_Intensitaet_3), 0=Cx0_kein_Crash (CM_AB_Crash_Int_Cx0_kein_Crash), 2=Cx2_Crash_Intensitaet_2_nur_Stellgliedtest_MLB_B8 (CM_AB_Crash_Int_Cx2_Crash_Intensitaet_2_nur_Stellgliedtest_MLB_B8) (Crash_Intensitaet_2_(nur_Stellgliedtest_MLB_B8)), 4=Cx4_Crash_Intensitaet_3_alt_VW_AUDI_Stellgliedtest_MLB_B8 (CM_AB_Crash_Int_Cx4_Crash_Intensitaet_3_alt_VW_AUDI_Stellgliedtest_MLB_B8) (Crash_Intensitaet_3_(alt_VW/AUDI__Stellgliedtest_MLB_B8))
  compu method CM_AB_Crashschwere: 7=Cx7_Fehler (CM_AB_Crashschwere_Cx7_Fehler), 6=Cx6_Crashschwere_2_bis_5 (CM_AB_Crashschwere_Cx6_Crashschwere_2_bis_5), 3=Cx3_Crashschwere_3 (CM_AB_Crashschwere_Cx3_Crashschwere_3), 4=Cx4_Crashschwere_4 (CM_AB_Crashschwere_Cx4_Crashschwere_4), 0=Cx0_kein_Ereignis (CM_AB_Crashschwere_Cx0_kein_Ereignis), 1=Cx1_Crashschwere_1 (CM_AB_Crashschwere_Cx1_Crashschwere_1), 2=Cx2_Crashschwere_2 (CM_AB_Crashschwere_Cx2_Crashschwere_2), 5=Cx5_Crashschwere_5 (CM_AB_Crashschwere_Cx5_Crashschwere_5)
  compu method CM_AB_Deaktiviert: 0=Cx0_aktiv (CM_AB_Deaktiviert_Cx0_aktiv), 1=Cx1_deaktiviert (CM_AB_Deaktiviert_Cx1_deaktiviert)
  compu method CM_AB_Deaktivierung_HV: 7=Cx7_Fehler (CM_AB_Deaktivierung_HV_Cx7_Fehler), 0=Cx0_keine_Deaktivierung (CM_AB_Deaktivierung_HV_Cx0_keine_Deaktivierung), 1=Cx1_Deaktivierung_1 (CM_AB_Deaktivierung_HV_Cx1_Deaktivierung_1), 2=Cx2_Deaktivierung_2 (CM_AB_Deaktivierung_HV_Cx2_Deaktivierung_2), 3=Cx3_Deaktivierung_3 (CM_AB_Deaktivierung_HV_Cx3_Deaktivierung_3), 4=Cx4_Deaktivierung_4 (CM_AB_Deaktivierung_HV_Cx4_Deaktivierung_4), 5=Cx5_Deaktivierung_5 (CM_AB_Deaktivierung_HV_Cx5_Deaktivierung_5), 6=Cx6_Deaktivierung_6 (CM_AB_Deaktivierung_HV_Cx6_Deaktivierung_6)
  compu method CM_AB_Diagnose: 1=Cx1_in_Diagnose (CM_AB_Diagnose_Cx1_in_Diagnose), 0=Cx0_nicht_in_Diagnose (CM_AB_Diagnose_Cx0_nicht_in_Diagnose)
  compu method CM_AB_EDR_Trigger: 0=Cx0_No_Event (CM_AB_EDR_Trigger_Cx0_No_Event), 2=Cx2_NonDeployment_Event (CM_AB_EDR_Trigger_Cx2_NonDeployment_Event), 3=Cx3_Deployment_Event (CM_AB_EDR_Trigger_Cx3_Deployment_Event), 1=Cx1_Start_Event (CM_AB_EDR_Trigger_Cx1_Start_Event)
  compu method CM_AB_Erh_Auf_VB: 2=Cx2_Beifahrerairbag_aktiviert (CM_AB_Erh_Auf_VB_Cx2_Beifahrerairbag_aktiviert), 1=Cx1_Beifahrerairbag_deaktiviert (CM_AB_Erh_Auf_VB_Cx1_Beifahrerairbag_deaktiviert), 3=Cx3_nicht_definiert (CM_AB_Erh_Auf_VB_Cx3_nicht_definiert), 0=Cx0_keine_Anzeige (CM_AB_Erh_Auf_VB_Cx0_keine_Anzeige)
  compu method CM_AB_Front_Crash: 1=Cx1_Front_Crash (CM_AB_Front_Crash_Cx1_Front_Crash), 0=Cx0_kein_Front_Crash (CM_AB_Front_Crash_Cx0_kein_Front_Crash)
  compu method CM_AB_Gurtschloss_BF: 3=Cx3_gesteckt (CM_AB_Gurtschloss_BF_Cx3_gesteckt), 2=Cx2_nicht_gesteckt (CM_AB_Gurtschloss_BF_Cx2_nicht_gesteckt), 0=Cx0_nicht_verbaut (CM_AB_Gurtschloss_BF_Cx0_nicht_verbaut), 1=Cx1_nicht_verfuegbar_Fehler_oder_Init (CM_AB_Gurtschloss_BF_Cx1_nicht_verfuegbar_Fehler_oder_Init) (nicht_verfügbar (Fehler oder Init))
  compu method CM_AB_Gurtschloss_FA: 3=Cx3_gesteckt (CM_AB_Gurtschloss_FA_Cx3_gesteckt), 2=Cx2_nicht_gesteckt (CM_AB_Gurtschloss_FA_Cx2_nicht_gesteckt), 0=Cx0_nicht_verbaut (CM_AB_Gurtschloss_FA_Cx0_nicht_verbaut), 1=Cx1_nicht_verfuegbar_Fehler_oder_Init (CM_AB_Gurtschloss_FA_Cx1_nicht_verfuegbar_Fehler_oder_Init) (nicht_verfügbar (Fehler oder Init))
  compu method CM_AB_Gurtschloss_FA_ext: 7=Cx7_Fehler (CM_AB_Gurtschloss_FA_ext_Cx7_Fehler), 2=Cx2_nicht_gesteckt (CM_AB_Gurtschloss_FA_ext_Cx2_nicht_gesteckt), 6=Cx6_Init (CM_AB_Gurtschloss_FA_ext_Cx6_Init), 1=Cx1_reserviert (CM_AB_Gurtschloss_FA_ext_Cx1_reserviert), 3=Cx3_gesteckt (CM_AB_Gurtschloss_FA_ext_Cx3_gesteckt), 4=Cx4_dauerhaft_nicht_gesteckt (CM_AB_Gurtschloss_FA_ext_Cx4_dauerhaft_nicht_gesteckt), 0=Cx0_nicht_verbaut (CM_AB_Gurtschloss_FA_ext_Cx0_nicht_verbaut), 5=Cx5_dauerhaft_gesteckt (CM_AB_Gurtschloss_FA_ext_Cx5_dauerhaft_gesteckt)
  compu method CM_AB_Gurtschloss_FA_ext_aktiv: 1=Cx1_aktiv (CM_AB_Gurtschloss_FA_ext_aktiv_Cx1_aktiv), 0=Cx0_inaktiv (CM_AB_Gurtschloss_FA_ext_aktiv_Cx0_inaktiv)
  compu method CM_AB_Gurtschloss_Reihe2_BF: 3=Cx3_gesteckt (CM_AB_Gurtschloss_Reihe2_BF_Cx3_gesteckt), 2=Cx2_nicht_gesteckt (CM_AB_Gurtschloss_Reihe2_BF_Cx2_nicht_gesteckt), 0=Cx0_nicht_verbaut (CM_AB_Gurtschloss_Reihe2_BF_Cx0_nicht_verbaut), 1=Cx1_nicht_verfuegbar_Fehler_oder_Init (CM_AB_Gurtschloss_Reihe2_BF_Cx1_nicht_verfuegbar_Fehler_oder_Init) (nicht_verfügbar (Fehler oder Init))
  compu method CM_AB_Gurtschloss_Reihe2_FA: 3=Cx3_gesteckt (CM_AB_Gurtschloss_Reihe2_FA_Cx3_gesteckt), 2=Cx2_nicht_gesteckt (CM_AB_Gurtschloss_Reihe2_FA_Cx2_nicht_gesteckt), 0=Cx0_nicht_verbaut (CM_AB_Gurtschloss_Reihe2_FA_Cx0_nicht_verbaut), 1=Cx1_nicht_verfuegbar_Fehler_oder_Init (CM_AB_Gurtschloss_Reihe2_FA_Cx1_nicht_verfuegbar_Fehler_oder_Init) (nicht_verfügbar (Fehler oder Init))
  compu method CM_AB_Gurtschloss_Reihe2_MI: 3=Cx3_gesteckt (CM_AB_Gurtschloss_Reihe2_MI_Cx3_gesteckt), 2=Cx2_nicht_gesteckt (CM_AB_Gurtschloss_Reihe2_MI_Cx2_nicht_gesteckt), 0=Cx0_nicht_verbaut (CM_AB_Gurtschloss_Reihe2_MI_Cx0_nicht_verbaut), 1=Cx1_nicht_verfuegbar_Fehler_oder_Init (CM_AB_Gurtschloss_Reihe2_MI_Cx1_nicht_verfuegbar_Fehler_oder_Init) (nicht_verfügbar (Fehler oder Init))
  compu method CM_AB_Gurtschloss_Reihe3_BF: 3=Cx3_gesteckt (CM_AB_Gurtschloss_Reihe3_BF_Cx3_gesteckt), 2=Cx2_nicht_gesteckt (CM_AB_Gurtschloss_Reihe3_BF_Cx2_nicht_gesteckt), 0=Cx0_nicht_verbaut (CM_AB_Gurtschloss_Reihe3_BF_Cx0_nicht_verbaut), 1=Cx1_nicht_verfuegbar_Fehler_oder_Init (CM_AB_Gurtschloss_Reihe3_BF_Cx1_nicht_verfuegbar_Fehler_oder_Init) (nicht_verfügbar (Fehler oder Init))
  compu method CM_AB_Gurtschloss_Reihe3_FA: 3=Cx3_gesteckt (CM_AB_Gurtschloss_Reihe3_FA_Cx3_gesteckt), 2=Cx2_nicht_gesteckt (CM_AB_Gurtschloss_Reihe3_FA_Cx2_nicht_gesteckt), 0=Cx0_nicht_verbaut (CM_AB_Gurtschloss_Reihe3_FA_Cx0_nicht_verbaut), 1=Cx1_nicht_verfuegbar_Fehler_oder_Init (CM_AB_Gurtschloss_Reihe3_FA_Cx1_nicht_verfuegbar_Fehler_oder_Init) (nicht_verfügbar (Fehler oder Init))
  compu method CM_AB_Gurtschloss_Reihe3_MI: 3=Cx3_gesteckt (CM_AB_Gurtschloss_Reihe3_MI_Cx3_gesteckt), 2=Cx2_nicht_gesteckt (CM_AB_Gurtschloss_Reihe3_MI_Cx2_nicht_gesteckt), 0=Cx0_nicht_verbaut (CM_AB_Gurtschloss_Reihe3_MI_Cx0_nicht_verbaut), 1=Cx1_nicht_verfuegbar_Fehler_oder_Init (CM_AB_Gurtschloss_Reihe3_MI_Cx1_nicht_verfuegbar_Fehler_oder_Init) (nicht_verfügbar (Fehler oder Init))
  compu method CM_AB_Gurtwarn_VB: 1=Cx1_Gurtwarnung_ausloesen (CM_AB_Gurtwarn_VB_Cx1_Gurtwarnung_ausloesen), 0=Cx0_keine_Warnung (CM_AB_Gurtwarn_VB_Cx0_keine_Warnung)
  compu method CM_AB_Gurtwarn_VF: 1=Cx1_Gurtwarnung_ausloesen (CM_AB_Gurtwarn_VF_Cx1_Gurtwarnung_ausloesen), 0=Cx0_keine_Warnung (CM_AB_Gurtwarn_VF_Cx0_keine_Warnung)
  compu method CM_AB_Heck_Crash: 1=Cx1_Heck_Crash (CM_AB_Heck_Crash_Cx1_Heck_Crash), 0=Cx0_kein_Heck_Crash (CM_AB_Heck_Crash_Cx0_kein_Heck_Crash)
  compu method CM_AB_Lampe: 0=Cx0_Aus (CM_AB_Lampe_Cx0_Aus), 1=Cx1_Ein (CM_AB_Lampe_Cx1_Ein)
  compu method CM_AB_MKB_Anforderung: 0=Cx0_Multikollisionsbremsung_nicht_angefordert (CM_AB_MKB_Anforderung_Cx0_Multikollisionsbremsung_nicht_angefordert), 1=Cx1_Multikollisionsbremsung_angefordert (CM_AB_MKB_Anforderung_Cx1_Multikollisionsbremsung_angefordert)
  compu method CM_AB_MKB_gueltig: 0=Cx0_Multikollisionsbremsung_nicht_freigeschaltet (CM_AB_MKB_gueltig_Cx0_Multikollisionsbremsung_nicht_freigeschaltet), 1=Cx1_Multikollisionsbremsung_freigeschaltet (CM_AB_MKB_gueltig_Cx1_Multikollisionsbremsung_freigeschaltet)
  compu method CM_AB_PAO_Leuchte_Anf: 0=Cx0_Leuchte_ausschalten (CM_AB_PAO_Leuchte_Anf_Cx0_Leuchte_ausschalten), 1=Cx1_Leuchte_einschalten (CM_AB_PAO_Leuchte_Anf_Cx1_Leuchte_einschalten)
  compu method CM_AB_RGS_Anst: 4=Cx4_aktiv_Niveau_1 (CM_AB_RGS_Anst_Cx4_aktiv_Niveau_1), 5=Cx5_aktiv_Niveau_2 (CM_AB_RGS_Anst_Cx5_aktiv_Niveau_2), 8=Cx8_deaktiviert (CM_AB_RGS_Anst_Cx8_deaktiviert), 6=Cx6_aktiv_Niveau_3 (CM_AB_RGS_Anst_Cx6_aktiv_Niveau_3), 7=Cx7_aktiv_Niveau_4 (CM_AB_RGS_Anst_Cx7_aktiv_Niveau_4)
  compu method CM_AB_Rollover_Crash: 0=Cx0_kein_Rollover (CM_AB_Rollover_Crash_Cx0_kein_Rollover), 1=Cx1_Rollover (CM_AB_Rollover_Crash_Cx1_Rollover)
  compu method CM_AB_SB_Crash: 0=Cx0_kein_Seiten_Crash_Beifahrer (CM_AB_SB_Crash_Cx0_kein_Seiten_Crash_Beifahrer), 1=Cx1_Seiten_Crash_Beifahrer (CM_AB_SB_Crash_Cx1_Seiten_Crash_Beifahrer)
  compu method CM_AB_SF_Crash: 0=Cx0_kein_Seiten_Crash_Fahrer (CM_AB_SF_Crash_Cx0_kein_Seiten_Crash_Fahrer), 1=Cx1_Seiten_Crash_Fahrer (CM_AB_SF_Crash_Cx1_Seiten_Crash_Fahrer)
  compu method CM_AB_Sitzpos_Sens_BF: 1=Cx1_Fehler (CM_AB_Sitzpos_Sens_BF_Cx1_Fehler), 3=Cx3_Sitz_vorne (CM_AB_Sitzpos_Sens_BF_Cx3_Sitz_vorne) (Sitz vorne), 2=Cx2_Sitz_nicht_vorne (CM_AB_Sitzpos_Sens_BF_Cx2_Sitz_nicht_vorne) (Sitz nicht vorne), 0=Cx0_nicht_verfuegbar (CM_AB_Sitzpos_Sens_BF_Cx0_nicht_verfuegbar) (nicht verfügbar)
  compu method CM_AB_Sitzpos_Sens_FA: 1=Cx1_Fehler (CM_AB_Sitzpos_Sens_FA_Cx1_Fehler), 3=Cx3_Sitz_vorne (CM_AB_Sitzpos_Sens_FA_Cx3_Sitz_vorne) (Sitz vorne), 2=Cx2_Sitz_nicht_vorne (CM_AB_Sitzpos_Sens_FA_Cx2_Sitz_nicht_vorne) (Sitz nicht vorne), 0=Cx0_nicht_verfuegbar (CM_AB_Sitzpos_Sens_FA_Cx0_nicht_verfuegbar) (nicht verfügbar)
  compu method CM_AB_Stellgliedtest: 0=Cx0_nicht_im_Stellgliedtest (CM_AB_Stellgliedtest_Cx0_nicht_im_Stellgliedtest), 1=Cx1_Airbag_im_Stellgliedtest (CM_AB_Stellgliedtest_Cx1_Airbag_im_Stellgliedtest)
  compu method CM_AB_Systemfehler: 0=Cx0_kein_Fehler (CM_AB_Systemfehler_Cx0_kein_Fehler), 1=Cx1_Airbag_Systemfehler (CM_AB_Systemfehler_Cx1_Airbag_Systemfehler)
  compu method CM_AB_Texte_AKS: 0=Cx0_keine_AKS_Ausloesung (CM_AB_Texte_AKS_Cx0_keine_AKS_Ausloesung), 1=Cx1_AKS_ausgeloest (CM_AB_Texte_AKS_Cx1_AKS_ausgeloest), 2=Cx2_AKS_Systemfehler (CM_AB_Texte_AKS_Cx2_AKS_Systemfehler)
  compu method CM_AB_VB_deaktiviert: 1=Cx1_Beifahrerairbag_deaktiviert (CM_AB_VB_deaktiviert_Cx1_Beifahrerairbag_deaktiviert), 0=Cx0_Beifahrerairbag_aktiv (CM_AB_VB_deaktiviert_Cx0_Beifahrerairbag_aktiv)
  compu method CM_AB_Versorgungsspannung: 0=Cx0_plausibel (CM_AB_Versorgungsspannung_Cx0_plausibel), 1=Cx1_unplausibel (CM_AB_Versorgungsspannung_Cx1_unplausibel)
  compu method CM_AB_Wickelklappung_Reihe2_BF: 2=Cx2_nicht_verriegelt (CM_AB_Wickelklappung_Reihe2_BF_Cx2_nicht_verriegelt), 3=Cx3_verriegelt (CM_AB_Wickelklappung_Reihe2_BF_Cx3_verriegelt), 1=Cx1_nicht_verfuegbar_Fehler_oder_Init (CM_AB_Wickelklappung_Reihe2_BF_Cx1_nicht_verfuegbar_Fehler_oder_Init) (nicht_verfuegbar__Fehler_oder_Init), 0=Cx0_nicht_verbaut (CM_AB_Wickelklappung_Reihe2_BF_Cx0_nicht_verbaut)
  compu method CM_AB_Wickelklappung_Reihe2_FA: 1=Cx1_nicht_verfuegbar_Fehler_oder_Init (CM_AB_Wickelklappung_Reihe2_FA_Cx1_nicht_verfuegbar_Fehler_oder_Init) (nicht_verfuegbar__Fehler_oder_Init), 2=Cx2_nicht_verriegelt (CM_AB_Wickelklappung_Reihe2_FA_Cx2_nicht_verriegelt), 0=Cx0_nicht_verbaut (CM_AB_Wickelklappung_Reihe2_FA_Cx0_nicht_verbaut), 3=Cx3_verriegelt (CM_AB_Wickelklappung_Reihe2_FA_Cx3_verriegelt)
  compu method CM_AB_Wickelklappung_Reihe2_MI: 2=Cx2_nicht_verriegelt (CM_AB_Wickelklappung_Reihe2_MI_Cx2_nicht_verriegelt), 3=Cx3_verriegelt (CM_AB_Wickelklappung_Reihe2_MI_Cx3_verriegelt), 0=Cx0_nicht_verbaut (CM_AB_Wickelklappung_Reihe2_MI_Cx0_nicht_verbaut), 1=Cx1_nicht_verfuegbar_Fehler_oder_Init (CM_AB_Wickelklappung_Reihe2_MI_Cx1_nicht_verfuegbar_Fehler_oder_Init) (nicht_verfuegbar__Fehler_oder_Init)
  compu method CM_AB_eCS_Aktuatortest_BF: 1=Cx1_Verriegelt (CM_AB_eCS_Aktuatortest_BF_Cx1_Verriegelt), 2=Cx2_Entriegelt (CM_AB_eCS_Aktuatortest_BF_Cx2_Entriegelt), 0=Cx0_Keine_Aktion (CM_AB_eCS_Aktuatortest_BF_Cx0_Keine_Aktion), 3=Cx3_Unplausibel (CM_AB_eCS_Aktuatortest_BF_Cx3_Unplausibel)
  compu method CM_AB_eCS_Aktuatortest_FA: 2=Cx2_Entriegelt (CM_AB_eCS_Aktuatortest_FA_Cx2_Entriegelt), 3=Cx3_Unplausibel (CM_AB_eCS_Aktuatortest_FA_Cx3_Unplausibel), 0=Cx0_Keine_Aktion (CM_AB_eCS_Aktuatortest_FA_Cx0_Keine_Aktion), 1=Cx1_Verriegelt (CM_AB_eCS_Aktuatortest_FA_Cx1_Verriegelt)
  compu method CM_AB_eCS_Aktuatortest_Reihe2_BF: 1=Cx1_Verriegelt (CM_AB_eCS_Aktuatortest_Reihe2_BF_Cx1_Verriegelt), 3=Cx3_Unplausibel (CM_AB_eCS_Aktuatortest_Reihe2_BF_Cx3_Unplausibel), 0=Cx0_Keine_Aktion (CM_AB_eCS_Aktuatortest_Reihe2_BF_Cx0_Keine_Aktion), 2=Cx2_Entriegelt (CM_AB_eCS_Aktuatortest_Reihe2_BF_Cx2_Entriegelt)
  compu method CM_AB_eCS_Aktuatortest_Reihe2_FA: 0=Cx0_Keine_Aktion (CM_AB_eCS_Aktuatortest_Reihe2_FA_Cx0_Keine_Aktion), 1=Cx1_Verriegelt (CM_AB_eCS_Aktuatortest_Reihe2_FA_Cx1_Verriegelt), 2=Cx2_Entriegelt (CM_AB_eCS_Aktuatortest_Reihe2_FA_Cx2_Entriegelt), 3=Cx3_Unplausibel (CM_AB_eCS_Aktuatortest_Reihe2_FA_Cx3_Unplausibel)
  compu method CM_AB_eCS_Aktuatortest_Reihe3_BF: 1=Cx1_Verriegelt, 0=Cx0_Keine_Aktion, 3=Cx3_Unplausibel, 2=Cx2_Entriegelt
  compu method CM_AB_eCS_Aktuatortest_Reihe3_FA: 2=Cx2_Entriegelt (CM_AB_eCS_Aktuatortest_Reihe3_FA_Cx2_Entriegelt), 0=Cx0_Keine_Aktion (CM_AB_eCS_Aktuatortest_Reihe3_FA_Cx0_Keine_Aktion), 1=Cx1_Verriegelt (CM_AB_eCS_Aktuatortest_Reihe3_FA_Cx1_Verriegelt), 3=Cx3_Unplausibel (CM_AB_eCS_Aktuatortest_Reihe3_FA_Cx3_Unplausibel)
  compu method CM_AB_eCS_Error: 0=Cx0_keine_Anzeige (CM_AB_eCS_Error_Cx0_keine_Anzeige), 1=Cx1_Anzeige_anfordern (CM_AB_eCS_Error_Cx1_Anzeige_anfordern)
  compu method CM_ASM_Masterzeit_02: phys=raw*0.04 for raw 0..254, 255=Cxff_Init (CM_ASM_Masterzeit_02_Cxff_Init); unit Unit_Secon
  compu method CM_Airbag_01_BZ: phys=raw for raw 0..15
  compu method CM_Airbag_01_CRC: phys=raw for raw 0..255
  compu method CM_Airbag_02_BZ: phys=raw for raw 0..15
  compu method CM_Airbag_02_CRC: phys=raw for raw 0..255
  compu method CM_LoGeWa_Event_Kombiwarnung: 2=Cx2_Traktionsverlust (CM_LoGeWa_Event_Kombiwarnung_Cx2_Traktionsverlust), 4=Cx4_Sichtbehinderung (CM_LoGeWa_Event_Kombiwarnung_Cx4_Sichtbehinderung), 3=Cx3_Panne (CM_LoGeWa_Event_Kombiwarnung_Cx3_Panne), 0=Cx0_Init (CM_LoGeWa_Event_Kombiwarnung_Cx0_Init), 1=Cx1_Unfall (CM_LoGeWa_Event_Kombiwarnung_Cx1_Unfall), 5=Cx5_Aquaplaning (CM_LoGeWa_Event_Kombiwarnung_Cx5_Aquaplaning)
  compu method CM_SC_PAO_OFF_Anf: 3=Cx3_reserviert (CM_SC_PAO_OFF_Anf_Cx3_reserviert), 1=Cx1_LED_an (CM_SC_PAO_OFF_Anf_Cx1_LED_an) (LED an), 2=Cx2_LED_blinken (CM_SC_PAO_OFF_Anf_Cx2_LED_blinken) (LED blinken), 0=Cx0_LED_aus (CM_SC_PAO_OFF_Anf_Cx0_LED_aus) (LED aus)
  compu method CM_SC_PAO_ON_Anf: 1=Cx1_LED_an (CM_SC_PAO_ON_Anf_Cx1_LED_an) (LED an), 0=Cx0_LED_aus (CM_SC_PAO_ON_Anf_Cx0_LED_aus) (LED aus), 3=Cx3_reserviert (CM_SC_PAO_ON_Anf_Cx3_reserviert), 2=Cx2_LED_blinken (CM_SC_PAO_ON_Anf_Cx2_LED_blinken) (LED blinken)
  compu method CM_SC_PAO_Schriftzug_Anf: 2=Cx2_LED_blinken (CM_SC_PAO_Schriftzug_Anf_Cx2_LED_blinken) (LED blinken), 3=Cx3_reserviert (CM_SC_PAO_Schriftzug_Anf_Cx3_reserviert), 0=Cx0_LED_aus (CM_SC_PAO_Schriftzug_Anf_Cx0_LED_aus) (LED aus), 1=Cx1_LED_an (CM_SC_PAO_Schriftzug_Anf_Cx1_LED_an) (LED an)
  compu method CM_eCS_Error_Reihe1_BFS_1: 0=Cx0_kein_Fehler, 1=Cx1_Kurzschluss_nach_Masse, 2=Cx2_Kurzschluss_nach_Plus, 3=Cx3_Open_Circuit, 4=Cx4_Aktor_Spule_Fehler
  compu method CM_eCS_Error_Reihe1_BFS_2: 0=Cx0_kein_Fehler, 1=Cx1_Kurzschluss_nach_Masse, 2=Cx2_Kurzschluss_nach_Plus, 3=Cx3_Open_Circuit, 4=Cx4_Aktor_Spule_Fehler
  compu method CM_eCS_Error_Reihe1_FS_1: 0=Cx0_kein_Fehler, 1=Cx1_Kurzschluss_nach_Masse, 2=Cx2_Kurzschluss_nach_Plus, 3=Cx3_Open_Circuit, 4=Cx4_Aktor_Spule_Fehler
  compu method CM_eCS_Error_Reihe1_FS_2: 0=Cx0_kein_Fehler, 1=Cx1_Kurzschluss_nach_Masse, 2=Cx2_Kurzschluss_nach_Plus, 3=Cx3_Open_Circuit, 4=Cx4_Aktor_Spule_Fehler
  compu method CM_eCS_Error_Reihe2_BFS: 0=Cx0_kein_Fehler, 1=Cx1_Kurzschluss_nach_Masse, 2=Cx2_Kurzschluss_nach_Plus, 3=Cx3_Open_Circuit, 4=Cx4_Aktor_Spule_Fehler
  compu method CM_eCS_Error_Reihe2_FS: 0=Cx0_kein_Fehler, 1=Cx1_Kurzschluss_nach_Masse, 2=Cx2_Kurzschluss_nach_Plus, 3=Cx3_Open_Circuit, 4=Cx4_Aktor_Spule_Fehler
  compu method CM_eCS_Gurtschloss_Status_Reihe2_BF: 2=Cx2_nicht_gesteckt (CM_eCS_Gurtschloss_Status_Reihe2_BF_Cx2_nicht_gesteckt), 1=Cx1_nicht_verfuegbar_Fehler_o_Init (CM_eCS_Gurtschloss_Status_Reihe2_BF_Cx1_nicht_verfuegbar_Fehler_o_Init), 3=Cx3_gesteckt (CM_eCS_Gurtschloss_Status_Reihe2_BF_Cx3_gesteckt), 0=Cx0_nicht_verbaut (CM_eCS_Gurtschloss_Status_Reihe2_BF_Cx0_nicht_verbaut)
  compu method CM_eCS_Gurtschloss_Status_Reihe2_FA: 2=Cx2_nicht_gesteckt (CM_eCS_Gurtschloss_Status_Reihe2_FA_Cx2_nicht_gesteckt), 3=Cx3_gesteckt (CM_eCS_Gurtschloss_Status_Reihe2_FA_Cx3_gesteckt), 1=Cx1_nicht_verfuegbar_Fehler_o_Init (CM_eCS_Gurtschloss_Status_Reihe2_FA_Cx1_nicht_verfuegbar_Fehler_o_Init), 0=Cx0_nicht_verbaut (CM_eCS_Gurtschloss_Status_Reihe2_FA_Cx0_nicht_verbaut)
  compu method CM_eCS_HW_defekt: 0=Cx0_nicht_defekt (CM_eCS_HW_defekt_Cx0_nicht_defekt), 1=Cx1_Defekt (CM_eCS_HW_defekt_Cx1_Defekt)
  compu method CM_eCS_SBS_Belegung_Reihe2_BF: 3=Cx3_belegt (CM_eCS_SBS_Belegung_Reihe2_BF_Cx3_belegt), 2=Cx2_nicht_belegt (CM_eCS_SBS_Belegung_Reihe2_BF_Cx2_nicht_belegt), 1=Cx1_Kurzschluss_nach_Masse (CM_eCS_SBS_Belegung_Reihe2_BF_Cx1_Kurzschluss_nach_Masse), 0=Cx0_nicht_verfuegbar (CM_eCS_SBS_Belegung_Reihe2_BF_Cx0_nicht_verfuegbar)
  compu method CM_eCS_SBS_Belegung_Reihe2_FA: 1=Cx1_Kurzschluss_nach_Masse (CM_eCS_SBS_Belegung_Reihe2_FA_Cx1_Kurzschluss_nach_Masse), 3=Cx3_belegt (CM_eCS_SBS_Belegung_Reihe2_FA_Cx3_belegt), 2=Cx2_nicht_belegt (CM_eCS_SBS_Belegung_Reihe2_FA_Cx2_nicht_belegt), 0=Cx0_nicht_verfuegbar (CM_eCS_SBS_Belegung_Reihe2_FA_Cx0_nicht_verfuegbar)
  compu method CM_eCS_SBS_LastState_Reihe2_BFS: 0=Cx0_Init, 1=Cx1_belegt, 2=Cx2_nicht_belegt, 3=Cx3_Fehler
  compu method CM_eCS_SBS_LastState_Reihe2_FS: 0=Cx0_Init, 1=Cx1_belegt, 2=Cx2_nicht_belegt, 3=Cx3_Fehler
  compu method CM_eCS_Status: 3=Cx3_Fehler (CM_eCS_Status_Cx3_Fehler), 0=Cx0_Init (CM_eCS_Status_Cx0_Init), 2=Cx2_entriegelt (CM_eCS_Status_Cx2_entriegelt), 1=Cx1_verriegelt (CM_eCS_Status_Cx1_verriegelt)
  compu method CM_eCS_Status_Verr_Reihe1_BFS_1: 0=Cx0_Init_oder_Fehler, 1=Cx1_verriegelt, 2=Cx2_entriegelt, 3=Cx3_nicht_verbaut
  compu method CM_eCS_Status_Verr_Reihe1_BFS_2: 0=Cx0_Init_oder_Fehler, 1=Cx1_verriegelt, 2=Cx2_entriegelt, 3=Cx3_nicht_verbaut
  compu method CM_eCS_Status_Verr_Reihe1_FS_1: 0=Cx0_Init_oder_Fehler, 1=Cx1_verriegelt, 2=Cx2_entriegelt, 3=Cx3_nicht_verbaut
  compu method CM_eCS_Status_Verr_Reihe1_FS_2: 0=Cx0_Init_oder_Fehler, 1=Cx1_verriegelt, 2=Cx2_entriegelt, 3=Cx3_nicht_verbaut
  compu method CM_eCS_Status_Verr_Reihe2_BFS: 0=Cx0_Init_oder_Fehler, 1=Cx1_verriegelt, 2=Cx2_entriegelt, 3=Cx3_nicht_verbaut
  compu method CM_eCS_Status_Verr_Reihe2_FS: 0=Cx0_Init_oder_Fehler, 1=Cx1_verriegelt, 2=Cx2_entriegelt, 3=Cx3_nicht_verbaut
  compu method CM_eCS_Stoerung: 0=Cx0_keine_Stoerung (CM_eCS_Stoerung_Cx0_keine_Stoerung), 1=Cx1_Stoerung (CM_eCS_Stoerung_Cx1_Stoerung)
package /Unit
  unit Unit_Unit_Secon: display-name=Unit_Secon, factor-si-to-unit=1.0, physical-dimension=PD_siSecond
package /UnitPackage
  unit NoUnit
  unit Unit_Secon
